VERSION ""

NS_ :

BS_:

BU_: ICC DVR EPC BBCM EAMP CMSM SBOX FLZCU_HCU_IC FLZCU_IC HCU_IC FLZCU_Signal_IC CGW TBOX BNCM CWC FRZCU

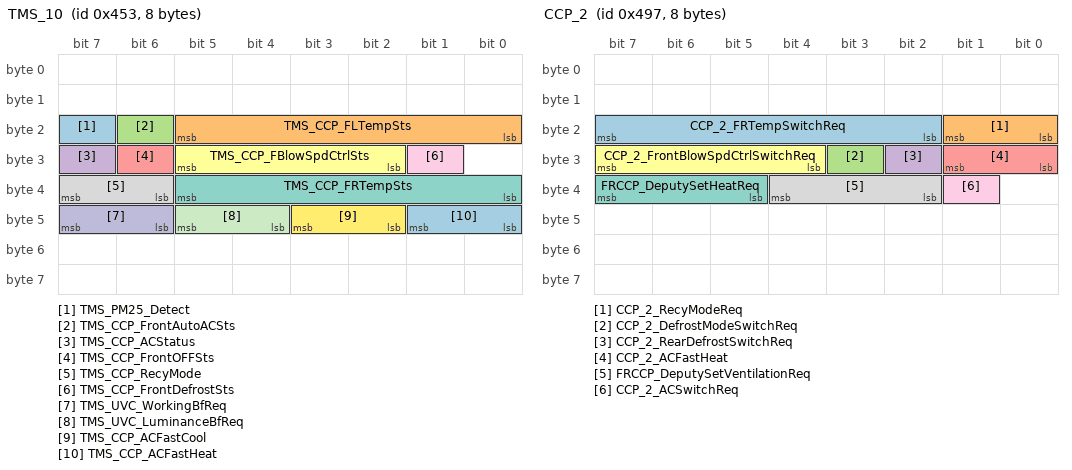
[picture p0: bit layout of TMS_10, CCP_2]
BO_ 1107 TMS_10: 8 CGW
 SG_ TMS_PM25_Detect : 23|1@0+ (1,0) [0|1] ""  ICC
 SG_ TMS_CCP_FLTempSts : 21|6@0+ (0.5,15.5) [15.5|30.5] "℃"  ICC
 SG_ TMS_CCP_FrontAutoACSts : 22|1@0+ (1,0) [0|1] ""  ICC
 SG_ TMS_CCP_ACStatus : 31|1@0+ (1,0) [0|1] ""  ICC
 SG_ TMS_CCP_FrontOFFSts : 30|1@0+ (1,0) [0|1] ""  ICC
 SG_ TMS_CCP_FBlowSpdCtrlSts : 29|4@0+ (1,0) [0|15] ""  ICC
 SG_ TMS_CCP_FRTempSts : 37|6@0+ (0.5,15.5) [15.5|30.5] "℃"  ICC
 SG_ TMS_CCP_RecyMode : 39|2@0+ (1,0) [0|3] ""  ICC
 SG_ TMS_CCP_FrontDefrostSts : 25|1@0+ (1,0) [0|1] ""  ICC
 SG_ TMS_UVC_WorkingBfReq : 47|2@0+ (1,0) [0|3] ""  ICC
 SG_ TMS_UVC_LuminanceBfReq : 45|2@0+ (1,0) [0|3] ""  ICC
 SG_ TMS_CCP_ACFastCool : 43|2@0+ (1,0) [0|3] ""  ICC
 SG_ TMS_CCP_ACFastHeat : 41|2@0+ (1,0) [0|3] ""  ICC

BO_ 1175 CCP_2: 8 CGW
 SG_ CCP_2_FRTempSwitchReq : 23|6@0+ (0.5,15.5) [15.5|30.5] "℃"  ICC
 SG_ CCP_2_RecyModeReq : 17|2@0+ (1,0) [0|3] ""  ICC
 SG_ CCP_2_DefrostModeSwitchReq : 27|1@0+ (1,0) [0|1] ""  ICC
 SG_ CCP_2_RearDefrostSwitchReq : 26|1@0+ (1,0) [0|1] ""  ICC
 SG_ CCP_2_ACFastHeat : 25|2@0+ (1,0) [0|3] ""  ICC
 SG_ CCP_2_FrontBlowSpdCtrlSwitchReq : 31|4@0+ (1,0) [0|15] ""  ICC
 SG_ FRCCP_DeputySetHeatReq : 39|3@0+ (1,0) [0|7] ""  ICC
 SG_ FRCCP_DeputySetVentilationReq : 36|3@0+ (1,0) [0|7] ""  ICC
 SG_ CCP_2_ACSwitchReq : 33|1@0+ (1,0) [0|1] ""  ICC

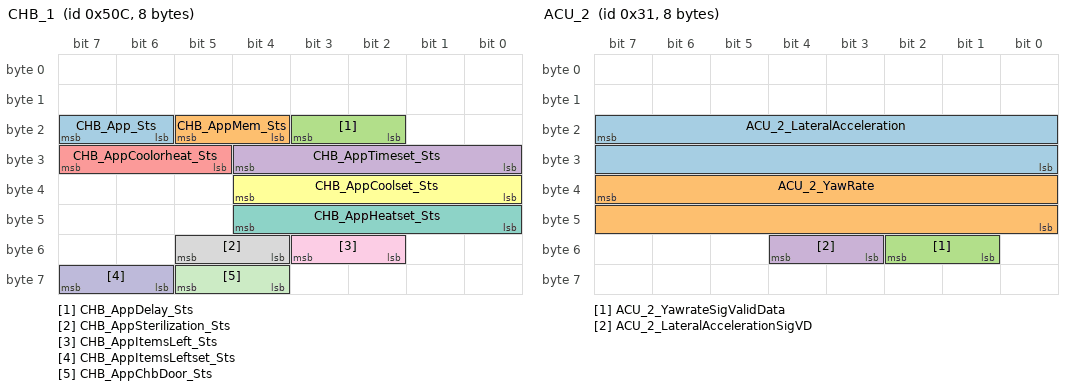
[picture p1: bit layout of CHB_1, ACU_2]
BO_ 1292 CHB_1: 8 CGW
 SG_ CHB_App_Sts : 23|2@0+ (1,0) [0|3] ""  ICC
 SG_ CHB_AppMem_Sts : 21|2@0+ (1,0) [0|3] ""  ICC
 SG_ CHB_AppDelay_Sts : 19|2@0+ (1,0) [0|3] ""  ICC
 SG_ CHB_AppTimeset_Sts : 28|5@0+ (1,0) [0|31] "h"  ICC
 SG_ CHB_AppCoolorheat_Sts : 31|3@0+ (1,0) [0|7] ""  ICC
 SG_ CHB_AppCoolset_Sts : 36|5@0+ (1,0) [0|31] ""  ICC
 SG_ CHB_AppHeatset_Sts : 44|5@0+ (1,0) [0|31] ""  ICC
 SG_ CHB_AppSterilization_Sts : 53|2@0+ (1,0) [0|3] ""  ICC
 SG_ CHB_AppItemsLeft_Sts : 51|2@0+ (1,0) [0|3] ""  ICC
 SG_ CHB_AppItemsLeftset_Sts : 63|2@0+ (1,0) [0|3] ""  ICC
 SG_ CHB_AppChbDoor_Sts : 61|2@0+ (1,0) [0|3] ""  ICC

BO_ 1241 EMS_4_G: 8 CGW
 SG_ FuelTankLidSystemFailureSts : 43|1@0+ (1,0) [0|1] ""  ICC
 SG_ FuelTankPressureConditionReached : 45|2@0+ (1,0) [0|3] ""  ICC

BO_ 49 ACU_2: 8 CGW
 SG_ ACU_2_LateralAcceleration : 23|16@0+ (0.001,-2) [-2|2] "g"  ICC
 SG_ ACU_2_YawRate : 39|16@0+ (0.01,-180) [-180|180] "deg/sec"  ICC
 SG_ ACU_2_YawrateSigValidData : 50|2@0+ (1,0) [0|3] ""  ICC
 SG_ ACU_2_LateralAccelerationSigVD : 52|2@0+ (1,0) [0|3] ""  ICC

BO_ 1024 FRZCU_13: 64 CGW
 SG_ FRZCU_QueenSeatPosSts : 80|1@0+ (1,0) [0|1] ""  BBCM,ICC
 SG_ FRZCU_QueenSeatEnterSts : 57|2@0+ (1,0) [0|3] ""  ICC
 SG_ FRZCU_QueenSeatMovFailCause : 87|4@0+ (1,0) [0|15] ""  ICC
 SG_ FRZCU_QueenSeatSts : 83|2@0+ (1,0) [0|3] ""  ICC
 SG_ FRZCU_PasgerSeatMovFailCause : 61|4@0+ (1,0) [0|15] ""  ICC
 SG_ FRZCU_ADSLightSts : 49|2@0+ (1,0) [0|3] ""  ICC
 SG_ CSunshadeSts : 23|3@0+ (1,0) [0|7] ""  ICC
 SG_ CSunshadePercentSts : 20|4@0+ (1,0) [0|15] ""  ICC
 SG_ FRZCU_SeatHeatLvlFR2 : 31|4@0+ (1,0) [0|15] ""  ICC
 SG_ FRZCU_SeatVentLvlFR2 : 27|4@0+ (1,0) [0|15] ""  ICC
 SG_ FRZCU_SeatVentLvlRR2 : 39|4@0+ (1,0) [0|15] ""  ICC
 SG_ FRZCU_SeatHeatLvlRR2 : 35|4@0+ (1,0) [0|15] ""  ICC
 SG_ FRZCU_ContainerlightSts : 47|2@0+ (1,0) [0|3] ""  ICC
 SG_ FRZCU_FRWinThermalSts : 45|1@0+ (1,0) [0|1] ""  ICC
 SG_ FRZCU_RRWinThermalSts : 44|1@0+ (1,0) [0|1] ""  ICC
 SG_ FRZCU_CSunshadeThermalSts : 43|1@0+ (1,0) [0|1] ""  ICC

BO_ 1182 CDU_OBC_3: 48 CGW
 SG_ OBC_InnerDischgVolt : 348|13@0+ (0.1,0) [0|800] ""  ICC
 SG_ OBC_InnerDischgCurr : 343|10@0+ (0.1,0) [0|100] ""  ICC
 SG_ OBC_ElectronicLockSts : 242|3@0+ (1,0) [0|4] ""  ICC
 SG_ OBC_WorkingMode : 251|4@0+ (1,0) [0|15] ""  ICC
 SG_ OBC_OutDischgCurr : 367|10@0+ (0.1,0) [0|100] "A"  ICC
 SG_ OBC_OutDischgVolt : 372|13@0+ (0.1,0) [0|800] "V"  ICC

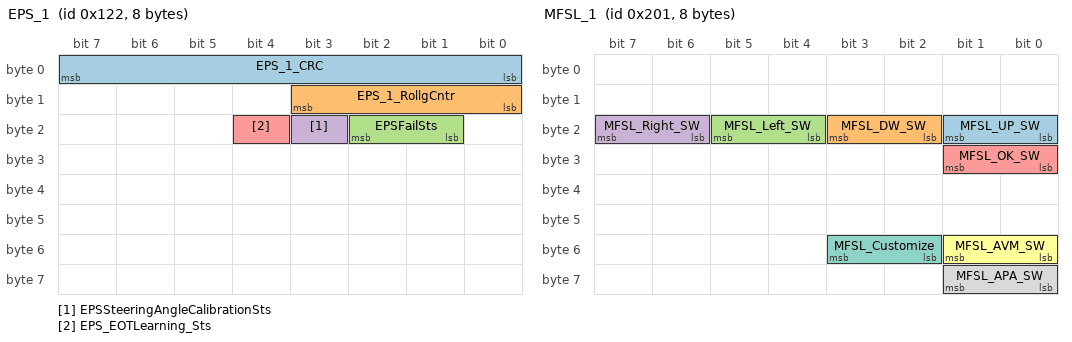
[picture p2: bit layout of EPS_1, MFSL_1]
BO_ 290 EPS_1: 8 CGW
 SG_ EPS_1_CRC : 7|8@0+ (1,0) [0|255] ""  ICC
 SG_ EPS_1_RollgCntr : 11|4@0+ (1,0) [0|14] ""  ICC
 SG_ EPSFailSts : 18|2@0+ (1,0) [0|3] ""  ICC
 SG_ EPSSteeringAngleCalibrationSts : 19|1@0+ (1,0) [0|1] ""  ICC
 SG_ EPS_EOTLearning_Sts : 20|1@0+ (1,0) [0|1] ""  ICC

BO_ 513 MFSL_1: 8 CGW
 SG_ MFSL_UP_SW : 17|2@0+ (1,0) [0|3] ""  ICC
 SG_ MFSL_DW_SW : 19|2@0+ (1,0) [0|3] ""  ICC
 SG_ MFSL_Left_SW : 21|2@0+ (1,0) [0|3] ""  ICC
 SG_ MFSL_Right_SW : 23|2@0+ (1,0) [0|3] ""  ICC
 SG_ MFSL_OK_SW : 25|2@0+ (1,0) [0|3] ""  ICC
 SG_ MFSL_AVM_SW : 49|2@0+ (1,0) [0|3] ""  ICC
 SG_ MFSL_Customize : 51|2@0+ (1,0) [0|3] ""  ICC
 SG_ MFSL_APA_SW : 57|2@0+ (1,0) [0|3] ""  ICC

BO_ 1152 TBOX_8: 16 CGW
 SG_ TBOX_PetmodeSetTemperature : 118|5@0+ (0.5,15.5) [15.5|30.5] "℃"  ICC

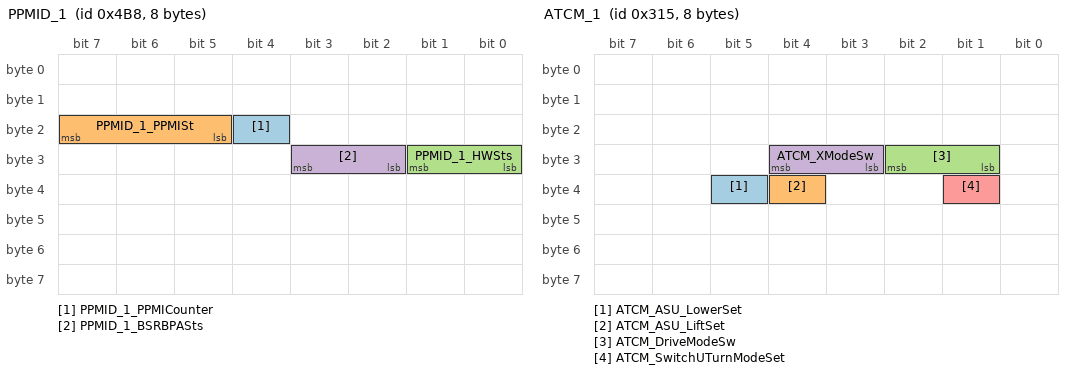
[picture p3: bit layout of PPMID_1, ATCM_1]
BO_ 1208 PPMID_1: 8 CGW
 SG_ PPMID_1_PPMICounter : 20|1@0+ (1,0) [0|1] ""  ICC
 SG_ PPMID_1_PPMISt : 23|3@0+ (1,0) [0|7] ""  ICC
 SG_ PPMID_1_HWSts : 25|2@0+ (1,0) [0|3] ""  ICC
 SG_ PPMID_1_BSRBPASts : 27|2@0+ (1,0) [0|3] ""  ICC

BO_ 794 ADS_COM_3: 24 CGW
 SG_ ADS_3_ICAStatus : 23|3@0+ (1,0) [0|7] ""  ICC
 SG_ ADS_3_ICATextinfo : 19|4@0+ (1,0) [0|15] ""  ICC
 SG_ ADS_3_ACCSts : 31|4@0+ (1,0) [0|15] ""  ICC
 SG_ ADS_3_DriverHandsoffWarning : 27|3@0+ (1,0) [0|7] ""  ICC
 SG_ ADS_3_LKSMod : 36|2@0+ (1,0) [0|3] ""  ICC
 SG_ ADS_3_LKSSts : 34|3@0+ (1,0) [0|7] ""  ICC
 SG_ ADS_3_ELKSts : 47|3@0+ (1,0) [0|7] ""  ICC
 SG_ ADS_3_LKSLeftTrackingSt : 44|2@0+ (1,0) [0|3] ""  ICC
 SG_ ADS_3_LKSRightTrackingSt : 42|2@0+ (1,0) [0|3] ""  ICC
 SG_ ADS_3_ELKLeftActiveSt : 55|2@0+ (1,0) [0|3] ""  ICC
 SG_ ADS_3_ELKRightActiveSt : 53|2@0+ (1,0) [0|3] ""  ICC

BO_ 1155 ASU_3: 16 CGW
 SG_ ASU_3_horizontalSts : 55|2@0+ (1,0) [0|3] ""  ICC
 SG_ ASU_3_horizontalmodeFb : 58|3@0+ (1,0) [0|7] ""  ICC

BO_ 1164 CDU_5: 64 CGW
 SG_ OBC_DischgSts : 123|3@0+ (1,0) [0|3] ""  ICC

BO_ 789 ATCM_1: 8 CGW
 SG_ ATCM_ASU_LowerSet : 37|1@0+ (1,0) [0|1] ""  ICC
 SG_ ATCM_ASU_LiftSet : 36|1@0+ (1,0) [0|1] ""  ICC
 SG_ ATCM_DriveModeSw : 26|2@0+ (1,0) [0|3] ""  ICC
 SG_ ATCM_XModeSw : 28|2@0+ (1,0) [0|3] ""  ICC
 SG_ ATCM_SwitchUTurnModeSet : 33|1@0+ (1,0) [0|1] ""  ICC

BO_ 1214 BNCM_16: 32 CGW
 SG_ BNCM_16_CRC1 : 7|8@0+ (1,0) [0|255] ""  ICC
 SG_ BNCM_16_RollgCntr1 : 11|4@0+ (1,0) [0|14] ""  ICC
 SG_ BNCM_16_Resd1 : 15|4@0+ (1,0) [0|15] ""  ICC
 SG_ BNCM_16_CMD : 23|16@0+ (1,0) [0|65535] ""  ICC
 SG_ BNCM_16_PDU1 : 39|64@0+ (1,0) [0|1.84467440737096E+019] ""  ICC
 SG_ BNCM_16_PDU2 : 103|64@0+ (1,0) [0|1.84467440737096E+019] ""  ICC
 SG_ BNCM_16_PDU3 : 167|64@0+ (1,0) [0|1.84467440737096E+019] ""  ICC
 SG_ BNCM_16_PDU4 : 231|32@0+ (1,0) [0|4294967295] ""  ICC

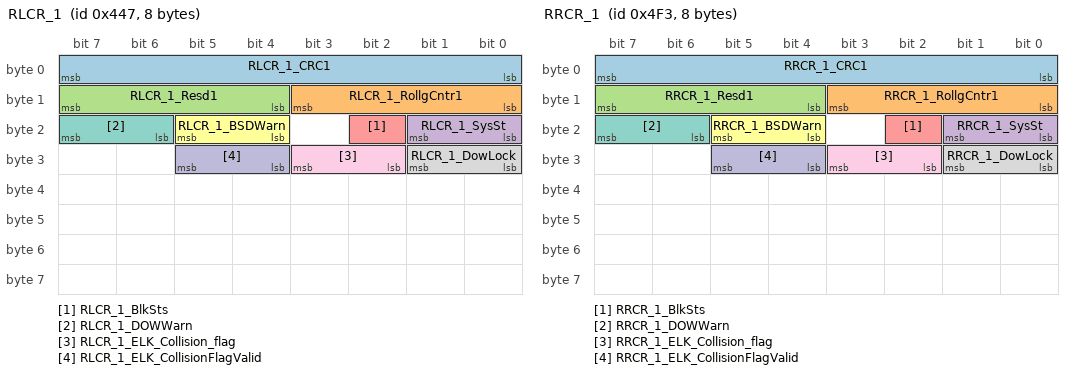
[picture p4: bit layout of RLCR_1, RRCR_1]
BO_ 1095 RLCR_1: 8 CGW
 SG_ RLCR_1_CRC1 : 7|8@0+ (1,0) [0|255] ""  ICC
 SG_ RLCR_1_RollgCntr1 : 11|4@0+ (1,0) [0|14] ""  ICC
 SG_ RLCR_1_Resd1 : 15|4@0+ (1,0) [0|15] ""  ICC
 SG_ RLCR_1_SysSt : 17|2@0+ (1,0) [0|3] ""  ICC
 SG_ RLCR_1_BlkSts : 18|1@0+ (1,0) [0|1] ""  ICC
 SG_ RLCR_1_BSDWarn : 21|2@0+ (1,0) [0|3] ""  ICC
 SG_ RLCR_1_DOWWarn : 23|2@0+ (1,0) [0|3] ""  ICC
 SG_ RLCR_1_DowLock : 25|2@0+ (1,0) [0|3] ""  ICC
 SG_ RLCR_1_ELK_Collision_flag : 27|2@0+ (1,0) [0|3] ""  ICC
 SG_ RLCR_1_ELK_CollisionFlagValid : 29|2@0+ (1,0) [0|3] ""  ICC

BO_ 1267 RRCR_1: 8 CGW
 SG_ RRCR_1_CRC1 : 7|8@0+ (1,0) [0|255] ""  ICC
 SG_ RRCR_1_RollgCntr1 : 11|4@0+ (1,0) [0|14] ""  ICC
 SG_ RRCR_1_Resd1 : 15|4@0+ (1,0) [0|15] ""  ICC
 SG_ RRCR_1_SysSt : 17|2@0+ (1,0) [0|3] ""  ICC
 SG_ RRCR_1_BlkSts : 18|1@0+ (1,0) [0|1] ""  ICC
 SG_ RRCR_1_BSDWarn : 21|2@0+ (1,0) [0|3] ""  ICC
 SG_ RRCR_1_DOWWarn : 23|2@0+ (1,0) [0|3] ""  ICC
 SG_ RRCR_1_DowLock : 25|2@0+ (1,0) [0|3] ""  ICC
 SG_ RRCR_1_ELK_Collision_flag : 27|2@0+ (1,0) [0|3] ""  ICC
 SG_ RRCR_1_ELK_CollisionFlagValid : 29|2@0+ (1,0) [0|3] ""  ICC

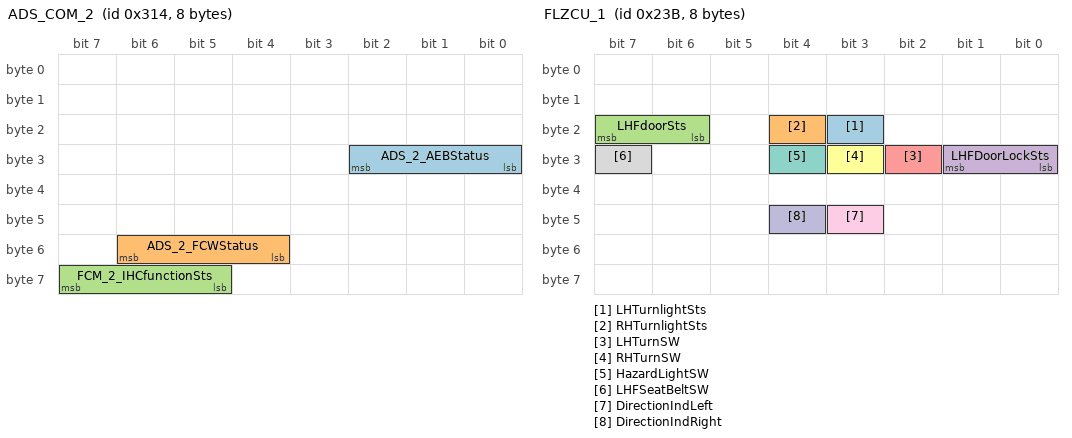
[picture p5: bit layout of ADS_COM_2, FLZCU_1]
BO_ 788 ADS_COM_2: 8 CGW
 SG_ ADS_2_AEBStatus : 26|3@0+ (1,0) [0|6] ""  ICC
 SG_ ADS_2_FCWStatus : 54|3@0+ (1,0) [0|7] ""  ICC
 SG_ FCM_2_IHCfunctionSts : 63|3@0+ (1,0) [0|7] ""  ICC

BO_ 571 FLZCU_1: 8 FLZCU_HCU_IC
 SG_ LHTurnlightSts : 19|1@0+ (1,0) [0|1] ""  ICC,DVR
 SG_ RHTurnlightSts : 20|1@0+ (1,0) [0|1] ""  ICC,DVR
 SG_ LHFdoorSts : 23|2@0+ (1,0) [0|3] ""  ICC,EPC,BBCM,CMSM
 SG_ LHFDoorLockSts : 25|2@0+ (1,0) [0|3] ""  ICC,EPC,BBCM
 SG_ LHTurnSW : 26|1@0+ (1,0) [0|1] ""  ICC
 SG_ RHTurnSW : 27|1@0+ (1,0) [0|1] ""  ICC
 SG_ HazardLightSW : 28|1@0+ (1,0) [0|1] ""  ICC
 SG_ LHFSeatBeltSW : 31|1@0+ (1,0) [0|1] ""  ICC
 SG_ DirectionIndLeft : 43|1@0+ (1,0) [0|1] ""  ICC
 SG_ DirectionIndRight : 44|1@0+ (1,0) [0|1] ""  ICC

BO_ 699 RZCU_2: 8 FLZCU_HCU_IC
 SG_ LHRdoorSts : 21|2@0+ (1,0) [0|3] ""  ICC,EPC,BBCM,CMSM

BO_ 787 FRZCU_14: 16 CGW
 SG_ ChrgHoodSts : 23|1@0+ (1,0) [0|1] ""  ICC
 SG_ FRZCU_FRSitPosnSts : 22|2@0+ (1,0) [0|3] ""  ICC

BO_ 524 ADS_6: 48 CGW
 SG_ New_Signal_20C : 16|1@0+ (1,0) [0|1] "" Vector__XXX
 SG_ New_Signal_20C_1 : 28|37@0+ (1,0) [0|137438953471] "" Vector__XXX
 SG_ ADS_6_CRC1 : 7|8@0+ (1,0) [0|255] ""  ICC
 SG_ ADS_6_RollgCntr1 : 11|4@0+ (1,0) [0|14] ""  ICC
 SG_ ADS_6_Resd1 : 15|4@0+ (1,0) [0|15] ""  ICC
 SG_ ADS_6_AVM_FuncSts : 23|2@0+ (1,0) [0|3] ""  ICC
 SG_ ADS_6_AVM_ButtonClick : 21|2@0+ (1,0) [0|1] ""  ICC
 SG_ ADS_6_Customize_buttonsFB : 19|3@0+ (1,0) [0|7] ""  ICC
 SG_ ADS_6_PAS_AudioTone : 31|3@0+ (1,0) [0|7] ""  ICC

BO_ 572 ONEBOX_7: 48 CGW
 SG_ ONEBOX_7_TAB_HighTemp : 49|1@0+ (1,0) [0|1] ""  ICC
 SG_ ONEBOX_7_TAB_Active : 51|2@0+ (1,0) [0|3] ""  ICC
 SG_ ONEBOX_7_BSW_Active : 60|2@0+ (1,0) [0|3] ""  ICC
 SG_ ONEBOX_7_iCCO_TgtVel : 151|8@0+ (0.1,0) [0|20] ""  ICC

BO_ 1212 VCU_3_G: 8 FLZCU_HCU_IC
 SG_ VCU_3_G_ActWheelTorqueFA : 23|16@0+ (1,-32768) [-32768|32767] "NM"  ICC
 SG_ VCU_3_G_ActWheelTorqueRA : 39|16@0+ (1,-32768) [-32768|32767] "NM"  ICC

BO_ 783 ADS_COM_1: 8 CGW
 SG_ ADCC_SysReadySts : 43|1@0+ (1,0) [0|1] ""  ICC

BO_ 1110 IMMO_ICC_11: 8 CGW
 SG_ IMMO_Chall_ICC : 7|64@0+ (1,0) [0|1.84467440737096E+019] ""  ICC

BO_ 1149 IMMO_VCC_12: 8 CGW
 SG_ IMMO_Teach_VCC : 7|64@0+ (1,0) [0|1.84467440737096E+019] ""  ICC

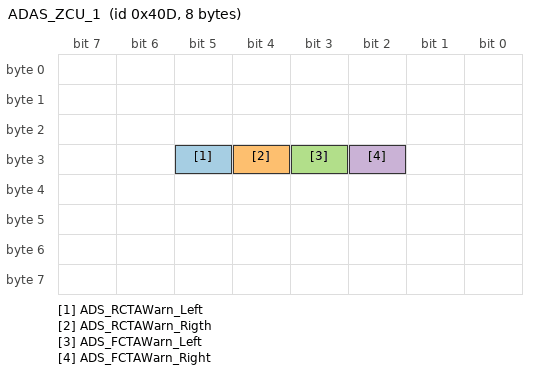
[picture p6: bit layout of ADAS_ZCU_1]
BO_ 1037 ADAS_ZCU_1: 8 CGW
 SG_ ADS_RCTAWarn_Left : 29|1@0+ (1,0) [0|1] ""  ICC
 SG_ ADS_RCTAWarn_Rigth : 28|1@0+ (1,0) [0|1] ""  ICC
 SG_ ADS_FCTAWarn_Left : 27|1@0+ (1,0) [0|1] ""  ICC
 SG_ ADS_FCTAWarn_Right : 26|1@0+ (1,0) [0|1] ""  ICC

BO_ 943 CSA_3: 32 CGW
 SG_ Fraxlebearingrate : 199|8@0+ (1,0) [0|100] ""  ICC
 SG_ CSA_3_CRC1 : 7|8@0+ (1,0) [0|255] ""  ICC
 SG_ CSA_3_RollgCntr1 : 11|4@0+ (1,0) [0|14] ""  ICC
 SG_ CSA_3_Resd1 : 15|4@0+ (1,0) [0|15] ""  ICC
 SG_ FlwheelBearing : 23|12@0+ (0.001,0) [0|4.095] "t"  ICC
 SG_ FrwheelBearing : 27|12@0+ (0.001,0) [0|4.095] "t"  ICC
 SG_ BlwheelBearing : 47|12@0+ (0.001,0) [0|4.095] "t"  ICC
 SG_ BrwheelBearing : 51|12@0+ (0.001,0) [0|4.095] "t"  ICC
 SG_ CSA_3_CRC2 : 71|8@0+ (1,0) [0|255] ""  ICC
 SG_ CSA_3_RollgCntr2 : 75|4@0+ (1,0) [0|14] ""  ICC
 SG_ VehicleBearing_kg : 87|12@0+ (1,0) [0|4095] "kg"  ICC
 SG_ VehicleBearing_lb : 91|14@0+ (1,0) [0|16383] "lb"  ICC
 SG_ GoodsWeight_kg : 109|12@0+ (1,0) [0|4095] "kg"  ICC
 SG_ Goods_Weight_Ratio : 113|10@0+ (0.1,0) [0|100] "%"  ICC
 SG_ CSA_3_CRC3 : 135|8@0+ (1,0) [0|255] ""  ICC
 SG_ CSA_3_RollgCntr3 : 139|4@0+ (1,0) [0|14] ""  ICC
 SG_ CSA_3_Resd3 : 143|4@0+ (1,0) [0|15] ""  ICC
 SG_ GoodsWeight_lb : 151|14@0+ (1,0) [0|16383] "lb"  ICC
 SG_ OverWeightValue_kg : 153|12@0+ (1,0) [0|4095] "kg"  ICC
 SG_ OverWeightValue_lb : 173|14@0+ (1,0) [0|16383] "lb"  ICC
 SG_ OverWeightRatio : 191|3@0+ (1,0) [0|7] "%"  ICC
 SG_ OverWeightWarning : 188|1@0+ (1,0) [0|1] ""  ICC
 SG_ OverLoadWarnShieldSetFed : 187|2@0+ (1,0) [0|3] ""  ICC

BO_ 1120 FLZCU_3: 8 FLZCU_HCU_IC
 SG_ RLHS_2_AmbBrightness : 19|12@0+ (20,0) [0|81880] "Lux"  ICC
 SG_ RLHS_LiSwithReason : 49|2@0+ (1,0) [0|3] ""  ICC

BO_ 850 ASU_6: 32 CGW
 SG_ ASU_trekthrough_352h : 47|2@0+ (1,0) [0|3] ""  ICC
 SG_ ASU_undergroundmode_352h : 45|2@0+ (1,0) [0|3] ""  ICC
 SG_ ASU_inflate_352h : 43|2@0+ (1,0) [0|3] ""  ICC
 SG_ ASU_6_HMIFailFb_JT : 23|4@0+ (1,0) [0|15] ""  ICC

BO_ 1199 TCM_1: 8 CGW
 SG_ TCM_1_TrailerSts : 16|1@0+ (1,0) [0|1] ""  ICC

BO_ 770 ADS_HW_302h: 64 CGW
 SG_ ADS_RPAOnlineOrNot_302h : 23|8@0+ (1,0) [0|255] ""  ICC
 SG_ ADS_RpaParkAuthn_302h : 31|2@0+ (1,0) [0|3] ""  ICC
 SG_ ADS_SeldParkID_302h : 29|4@0+ (1,0) [0|10] ""  ICC
 SG_ ADS_VehParkMod_302h : 25|3@0+ (1,0) [0|2] ""  ICC
 SG_ ADS_RemParkPatSel_302h : 38|2@0+ (1,0) [0|3] ""  ICC
 SG_ ADS_ParkDirCfm_302h : 36|4@0+ (1,0) [0|8] ""  ICC
 SG_ ADS_ParkProgs_302h : 32|7@0+ (1,0) [0|100] ""  ICC
 SG_ ADS_ParkRmngDst_302h : 41|9@0+ (0.1,0) [0|50] ""  ICC
 SG_ ADS_ObstclDst_302h : 48|5@0+ (1,0) [0|31] ""  ICC
 SG_ ADS_AutEve_302h : 59|4@0+ (1,0) [0|15] ""  ICC
 SG_ ADS_parkInterruptDuration_302h : 87|8@0+ (1,0) [0|255] ""  ICC
 SG_ APA_ResuAvl_302h : 95|2@0+ (1,0) [0|3] ""  ICC
 SG_ ADS_ParkStMac_302h : 93|5@0+ (1,0) [0|31] ""  ICC
 SG_ ADS_ParkOutDir_ParaLe_302h : 88|1@0+ (1,0) [0|1] ""  ICC
 SG_ ADS_ParkOutDir_ParaRi_302h : 103|1@0+ (1,0) [0|1] ""  ICC
 SG_ ADS_ParkOutDir_PerpFwd_302h : 102|1@0+ (1,0) [0|1] ""  ICC
 SG_ ADS_ParkOutDir_PerpLeFwd_302h : 101|1@0+ (1,0) [0|1] ""  ICC
 SG_ ADS_ParkOutDir_PerpRiFwd_302h : 100|1@0+ (1,0) [0|1] ""  ICC
 SG_ ADS_ParkOutDir_PerpLeBack_302h : 99|1@0+ (1,0) [0|1] ""  ICC
 SG_ ADS_ParkOutDir_PerpRiBack_302h : 98|1@0+ (1,0) [0|1] ""  ICC
 SG_ ADS_ParkOutDir_PerpBack_302h : 97|1@0+ (1,0) [0|1] ""  ICC
 SG_ APA_RPAFctUnavlMsg_1_302h : 96|1@0+ (1,0) [0|1] ""  ICC
 SG_ APA_RPAFctUnavlMsg_2_302h : 111|1@0+ (1,0) [0|1] ""  ICC
 SG_ APA_RPAFctUnavlMsg_3_302h : 110|1@0+ (1,0) [0|1] ""  ICC
 SG_ APA_RPAFctUnavlMsg_4_302h : 109|1@0+ (1,0) [0|1] ""  ICC
 SG_ APA_RPAFctUnavlMsg_5_302h : 108|1@0+ (1,0) [0|1] ""  ICC
 SG_ APA_RPAFctUnavlMsg_6_302h : 107|1@0+ (1,0) [0|1] ""  ICC
 SG_ APA_RPAFctUnavlMsg_7_302h : 106|1@0+ (1,0) [0|1] ""  ICC
 SG_ APA_RPAFctUnavlMsg_8_302h : 105|1@0+ (1,0) [0|1] ""  ICC
 SG_ APA_RPAFctUnavlMsg_9_302h : 104|1@0+ (1,0) [0|1] ""  ICC
 SG_ APA_RPAFctUnavlMsg_10_302h : 119|1@0+ (1,0) [0|1] ""  ICC
 SG_ APA_RPAFctUnavlMsg_11_302h : 118|1@0+ (1,0) [0|1] ""  ICC
 SG_ APA_RPAFctUnavlMsg_12_302h : 117|1@0+ (1,0) [0|1] ""  ICC
 SG_ APA_RPAFctUnavlMsg_13_302h : 116|1@0+ (1,0) [0|1] ""  ICC
 SG_ APA_RPAFctUnavlMsg_14_302h : 115|1@0+ (1,0) [0|1] ""  ICC
 SG_ APA_RPAFctUnavlMsg_15_302h : 114|1@0+ (1,0) [0|1] ""  ICC
 SG_ APA_RPAFctUnavlMsg_16_302h : 113|1@0+ (1,0) [0|1] ""  ICC
 SG_ APA_RPAFctUnavlMsg_17_302h : 112|1@0+ (1,0) [0|1] ""  ICC
 SG_ APA_RPAFctUnavlMsg_18_302h : 127|1@0+ (1,0) [0|1] ""  ICC
 SG_ APA_RPAFctUnavlMsg_19_302h : 126|1@0+ (1,0) [0|1] ""  ICC
 SG_ APA_RPAFctUnavlMsg_20_302h : 125|1@0+ (1,0) [0|1] ""  ICC
 SG_ APA_RPAFctUnavlMsg_21_302h : 124|1@0+ (1,0) [0|1] ""  ICC
 SG_ APA_RPAFctUnavlMsg_22_302h : 123|1@0+ (1,0) [0|1] ""  ICC
 SG_ APA_RPAFctUnavlMsg_23_302h : 122|1@0+ (1,0) [0|1] ""  ICC
 SG_ APA_RPAFctUnavlMsg_24_302h : 121|1@0+ (1,0) [0|1] ""  ICC
 SG_ APA_RPAFctUnavlMsg_25_302h : 120|1@0+ (1,0) [0|1] ""  ICC
 SG_ APA_RPACnclMsg_1_302h : 151|1@0+ (1,0) [0|1] ""  ICC
 SG_ APA_RPACnclMsg_2_302h : 150|1@0+ (1,0) [0|1] ""  ICC
 SG_ APA_RPACnclMsg_3 : 149|1@0+ (1,0) [0|1] ""  ICC
 SG_ APA_RPACnclMsg_4_302h : 148|1@0+ (1,0) [0|1] ""  ICC
 SG_ APA_RPACnclMsg_5_302h : 147|1@0+ (1,0) [0|1] ""  ICC
 SG_ APA_RPACnclMsg_6_302h : 146|1@0+ (1,0) [0|1] ""  ICC
 SG_ APA_RPACnclMsg_7_302h : 145|1@0+ (1,0) [0|1] ""  ICC
 SG_ APA_RPACnclMsg_8_302h : 144|1@0+ (1,0) [0|1] ""  ICC
 SG_ APA_RPACnclMsg_9_302h : 159|1@0+ (1,0) [0|1] ""  ICC
 SG_ APA_RPACnclMsg_10_302h : 158|1@0+ (1,0) [0|1] ""  ICC
 SG_ APA_RPACnclMsg_11_302h : 157|1@0+ (1,0) [0|1] ""  ICC
 SG_ APA_RPACnclMsg_12_302h : 156|1@0+ (1,0) [0|1] ""  ICC
 SG_ APA_RPACnclMsg_13_302h : 155|1@0+ (1,0) [0|1] ""  ICC
 SG_ APA_RPACnclMsg_14_302h : 154|1@0+ (1,0) [0|1] ""  ICC
 SG_ APA_RPACnclMsg_15_302h : 153|1@0+ (1,0) [0|1] ""  ICC
 SG_ APA_RPACnclMsg_16_302h : 152|1@0+ (1,0) [0|1] ""  ICC
 SG_ APA_RPACnclMsg_17_302h : 167|1@0+ (1,0) [0|1] ""  ICC
 SG_ APA_RPACnclMsg_18_302h : 166|1@0+ (1,0) [0|1] ""  ICC
 SG_ APA_RPACnclMsg_19_302h : 165|1@0+ (1,0) [0|1] ""  ICC
 SG_ APA_RPACnclMsg_20_302h : 164|1@0+ (1,0) [0|1] ""  ICC
 SG_ APA_RPAPauseMsg_1_302h : 163|1@0+ (1,0) [0|1] ""  ICC
 SG_ APA_RPAPauseMsg_2_302h : 162|1@0+ (1,0) [0|1] ""  ICC
 SG_ APA_RPAPauseMsg_3_302h : 161|1@0+ (1,0) [0|1] ""  ICC
 SG_ APA_RPAPauseMsg_4_302h : 160|1@0+ (1,0) [0|1] ""  ICC
 SG_ APA_RPAPauseMsg_5_302h : 175|1@0+ (1,0) [0|1] ""  ICC
 SG_ APA_RPAPauseMsg_6_302h : 174|1@0+ (1,0) [0|1] ""  ICC
 SG_ APA_RPAPauseMsg_7_302h : 173|1@0+ (1,0) [0|1] ""  ICC
 SG_ APA_RPAPauseMsg_8_302h : 172|1@0+ (1,0) [0|1] ""  ICC
 SG_ APA_RPAPauseMsg_9_302h : 171|1@0+ (1,0) [0|1] ""  ICC
 SG_ APA_RPAPauseMsg_10_302h : 170|1@0+ (1,0) [0|1] ""  ICC
 SG_ ADS_ParkPosn1_ID_302h : 169|4@0+ (1,0) [0|15] ""  ICC
 SG_ ADS_MnvrOrintChng1_302h : 181|2@0+ (1,0) [0|3] ""  ICC
 SG_ ADS_MnvrOrintChng2_302h : 179|2@0+ (1,0) [0|3] ""  ICC
 SG_ ADS_ParkRelPos1_x1_302h : 177|10@0+ (0.1,-50) [-50|50] ""  ICC
 SG_ ADS_ParkRelPos1_y1_302h : 215|10@0+ (0.1,-50) [-50|50] ""  ICC
 SG_ ADS_ParkRelPos1_x2_302h : 221|10@0+ (0.1,-50) [-50|50] ""  ICC
 SG_ ADS_ParkRelPos1_y2_302h : 227|10@0+ (0.1,-50) [-50|50] ""  ICC
 SG_ ADS_ParkRelPos1_x3_302h : 233|10@0+ (0.1,-50) [-50|50] ""  ICC
 SG_ ADS_TarParkSt_Posn1_302h : 255|3@0+ (1,0) [0|7] ""  ICC
 SG_ ADS_ParkChkSrc_Posn1_302h : 252|3@0+ (1,0) [0|3] ""  ICC
 SG_ ADS_VdcActvSts_302h : 249|1@0+ (1,0) [0|1] ""  ICC
 SG_ ADS_TcsActvSts_302h : 248|1@0+ (1,0) [0|1] ""  ICC
 SG_ ADS_ParkRelPos1_y3_302h : 279|10@0+ (0.1,-50) [-50|50] ""  ICC
 SG_ ADS_ParkRelPos1_x4_302h : 285|10@0+ (0.1,-50) [-50|50] ""  ICC
 SG_ ADS_ParkRelPos1_y4_302h : 291|10@0+ (0.1,-50) [-50|50] ""  ICC
 SG_ ADS_ParkPosn2_ID_302h : 297|4@0+ (1,0) [0|15] ""  ICC
 SG_ ADS_ParkRelPos2_x1_302h : 309|10@0+ (0.1,-50) [-50|50] ""  ICC
 SG_ ADS_ParkRelPos2_y1_302h : 343|10@0+ (0.1,-50) [-50|50] ""  ICC
 SG_ ADS_ParkRelPos2_x2_302h : 349|10@0+ (0.1,-50) [-50|50] ""  ICC
 SG_ ADS_ParkRelPos2_y2_302h : 355|10@0+ (0.1,-50) [-50|50] ""  ICC
 SG_ ADS_ParkRelPos2_x3_302h : 361|10@0+ (0.1,-50) [-50|50] ""  ICC
 SG_ ADS_TarParkSt_Posn2_302h : 383|3@0+ (1,0) [0|7] ""  ICC
 SG_ ADS_ParkChkSrc_Posn2_302h : 380|3@0+ (1,0) [0|3] ""  ICC
 SG_ ADS_ParkRelPos2_y3_302h : 407|10@0+ (0.1,-50) [-50|50] ""  ICC
 SG_ ADS_ParkRelPos2_x4_302h : 413|10@0+ (0.1,-50) [-50|50] ""  ICC
 SG_ ADS_ParkRelPos2_y4_302h : 419|10@0+ (0.1,-50) [-50|50] ""  ICC

BO_ 514 ADS_HW_202h: 16 CGW
 SG_ ADS_Resd1_202h : 15|4@0+ (1,0) [0|15] ""  ICC
 SG_ ADS_RollgCntr1_202h : 11|4@0+ (1,0) [0|14] ""  ICC
 SG_ ADS_CRC1_202h : 7|8@0+ (1,0) [0|255] ""  ICC
 SG_ ADS_AdsFault_202h : 23|3@0+ (1,0) [0|7] ""  ICC
 SG_ ADS_NicaReminderLEDVisual_202h : 20|3@0+ (1,0) [0|7] ""  ICC
 SG_ ADS_NicaReminderAcoustic_202h : 17|3@0+ (1,0) [0|7] ""  ICC
 SG_ ADS_TakeoverID_202h : 30|16@0+ (1,0) [0|65535] ""  ICC
 SG_ ADS_TakeoverLevel_202h : 46|3@0+ (1,0) [0|7] ""  ICC
 SG_ ADS_TakeoverType_202h : 43|4@0+ (1,0) [0|15] ""  ICC
 SG_ ADS_TORIDCorrespErrorID_202h : 55|16@0+ (1,0) [0|65535] ""  ICC
 SG_ ADS_TakeoverExtended16bit_202h : 87|16@0+ (1,0) [0|65535] ""  ICC
 SG_ ADS_TakeoverExtended8bit_202h : 103|8@0+ (1,0) [0|255] ""  ICC

BO_ 1041 ADS_HW_411h: 48 CGW
 SG_ ADS_RadarWarning0Distance_411h : 23|8@0+ (1,0) [0|255] "cm"  ICC
 SG_ ADS_RadarWarning1Distance_411h : 31|8@0+ (1,0) [0|255] "cm"  ICC
 SG_ ADS_RadarWarning2Distance_411h : 39|8@0+ (1,0) [0|255] "cm"  ICC
 SG_ ADS_RadarWarning3Distance_411h : 47|8@0+ (1,0) [0|255] "cm"  ICC
 SG_ ADS_RadarWarning4Distance_411h : 55|8@0+ (1,0) [0|255] "cm"  ICC
 SG_ ADS_RadarWarning5Distance_411h : 63|8@0+ (1,0) [0|255] "cm"  ICC
 SG_ ADS_RadarWarning6Distance_411h : 87|8@0+ (1,0) [0|255] "cm"  ICC
 SG_ ADS_RadarWarning7Distance_411h : 95|8@0+ (1,0) [0|255] "cm"  ICC
 SG_ ADS_RadarWarning8Distance_411h : 103|8@0+ (1,0) [0|255] "cm"  ICC
 SG_ ADS_RadarWarning9Distance_411h : 111|8@0+ (1,0) [0|255] "cm"  ICC
 SG_ ADS_RadarWarning10Distance_411h : 119|8@0+ (1,0) [0|255] "cm"  ICC
 SG_ ADS_RadarWarning11Distance_411h : 127|8@0+ (1,0) [0|255] "cm"  ICC
 SG_ ADS_RadarWarning12Distance_411h : 151|8@0+ (1,0) [0|255] "cm"  ICC
 SG_ ADS_RadarWarning13Distance_411h : 159|8@0+ (1,0) [0|255] "cm"  ICC
 SG_ ADS_RadarWarning14Distance_411h : 167|8@0+ (1,0) [0|255] "cm"  ICC
 SG_ ADS_RadarWarning15Distance_411h : 175|8@0+ (1,0) [0|255] "cm"  ICC
 SG_ ADS_RadarWarning0AcLvl_411h : 183|3@0+ (1,0) [0|7] ""  ICC
 SG_ ADS_RadarWarning1AcLvl_411h : 180|3@0+ (1,0) [0|7] ""  ICC
 SG_ ADS_RadarWarning2AcLvl_411h : 177|3@0+ (1,0) [0|7] ""  ICC
 SG_ ADS_RadarWarning3AcLvl_411h : 190|3@0+ (1,0) [0|7] ""  ICC
 SG_ ADS_RadarWarning4AcLvl_411h : 187|3@0+ (1,0) [0|7] ""  ICC
 SG_ ADS_RadarWarning5AcLvl_411h : 215|3@0+ (1,0) [0|7] ""  ICC
 SG_ ADS_RadarWarning6AcLvl_411h : 212|3@0+ (1,0) [0|7] ""  ICC
 SG_ ADS_RadarWarning7AcLvl_411h : 209|3@0+ (1,0) [0|7] ""  ICC
 SG_ ADS_RadarWarning8AcLvl_411h : 222|3@0+ (1,0) [0|7] ""  ICC
 SG_ ADS_RadarWarning9AcLvl_411h : 219|3@0+ (1,0) [0|7] ""  ICC
 SG_ ADS_RadarWarning10AcLvl_411h : 216|3@0+ (1,0) [0|7] ""  ICC
 SG_ ADS_RadarWarning11AcLvl_411h : 229|3@0+ (1,0) [0|7] ""  ICC
 SG_ ADS_RadarWarning12AcLvl_411h : 226|3@0+ (1,0) [0|7] ""  ICC
 SG_ ADS_RadarWarning13AcLvl_411h : 239|3@0+ (1,0) [0|7] ""  ICC
 SG_ ADS_RadarWarning14AcLvl_411h : 236|3@0+ (1,0) [0|7] ""  ICC
 SG_ ADS_RadarWarning15AcLvl_411h : 233|3@0+ (1,0) [0|7] ""  ICC
 SG_ ADC_FuncReq_SentryModWarn_411h : 246|1@0+ (1,0) [0|1] ""  ICC
 SG_ ADC_FuncReq_SentryModDetec_411h : 245|1@0+ (1,0) [0|1] ""  ICC
 SG_ ADC_MdcSentryAlarmMod_411h : 244|1@0+ (1,0) [0|1] ""  ICC

BO_ 769 ADS_HW_301h: 48 CGW
 SG_ ADS_AccFunctionStatus_301h : 23|4@0+ (1,0) [0|15] ""  ICC
 SG_ ADS_LccNcaFunctionStatus_301h : 19|6@0+ (1,0) [0|63] ""  ICC
 SG_ ADS_AdsFucntionNotActive_301h : 29|4@0+ (1,0) [0|15] ""  ICC
 SG_ ADS_AvpFunctionStatus_301h : 25|5@0+ (1,0) [0|31] ""  ICC
 SG_ ADS_SpeedSetByDriver_301h : 36|9@0+ (1,0) [0|511] "kph"  ICC
 SG_ ADS_SpeedLimitValue_301h : 43|8@0+ (1,0) [0|255] "kph"  ICC
 SG_ ADS_SpeedAutoFollow_301h : 51|3@0+ (1,0) [0|7] ""  ICC
 SG_ ADS_OneTouchSpeedAdjustment_301h : 48|3@0+ (1,0) [0|7] ""  ICC
 SG_ ADS_CalibState_301h : 61|3@0+ (1,0) [0|7] ""  ICC
 SG_ ADS_HODReminder_301h : 58|3@0+ (1,0) [0|7] ""  ICC
 SG_ ADS_DMSReminder_301h : 87|4@0+ (1,0) [0|15] ""  ICC
 SG_ ADS_FcwWaning_301h : 83|3@0+ (1,0) [0|7] ""  ICC
 SG_ ADS_FcwFault_301h : 80|2@0+ (1,0) [0|3] ""  ICC
 SG_ ADS_AebWaning_301h : 94|4@0+ (1,0) [0|15] ""  ICC
 SG_ ADS_AebFault_301h : 90|2@0+ (1,0) [0|3] ""  ICC
 SG_ ADS_AebObjType_301h : 88|3@0+ (1,0) [0|7] ""  ICC
 SG_ ADS_RaebWarning_301h : 101|3@0+ (1,0) [0|7] ""  ICC
 SG_ ADS_RaebFault_301h : 98|2@0+ (1,0) [0|3] ""  ICC
 SG_ ADS_RcwWarning_301h : 96|3@0+ (1,0) [0|7] ""  ICC
 SG_ ADS_RcwFault_301h : 109|2@0+ (1,0) [0|3] ""  ICC
 SG_ ADS_FctaLeftWarning_301h : 107|3@0+ (1,0) [0|7] ""  ICC
 SG_ ADS_FctaRightWarning_301h : 104|3@0+ (1,0) [0|7] ""  ICC
 SG_ ADS_FctbLeftWarning_301h : 117|3@0+ (1,0) [0|7] ""  ICC
 SG_ ADS_FctbRightWarning_301h : 114|3@0+ (1,0) [0|7] ""  ICC
 SG_ ADS_RctaLeftWarning_301h : 127|3@0+ (1,0) [0|7] ""  ICC
 SG_ ADS_RctaRightWarning_301h : 124|3@0+ (1,0) [0|7] ""  ICC
 SG_ ADS_RctaFault_301h : 121|2@0+ (1,0) [0|3] ""  ICC
 SG_ ADS_RctbLeftWarning_301h : 151|3@0+ (1,0) [0|7] ""  ICC
 SG_ ADS_RctbRightWarning_301h : 148|3@0+ (1,0) [0|7] ""  ICC
 SG_ ADS_LdwWarning_301h : 145|3@0+ (1,0) [0|7] ""  ICC
 SG_ ADS_LdwFault_301h : 158|3@0+ (1,0) [0|7] ""  ICC
 SG_ ADS_LKAWarning_301h : 155|3@0+ (1,0) [0|7] ""  ICC
 SG_ ADS_LkaFault_301h : 152|2@0+ (1,0) [0|3] ""  ICC
 SG_ ADS_LeftMirrWarningCmd_301h : 166|3@0+ (1,0) [0|7] ""  ICC
 SG_ ADS_RightMirrWarningCmd_301h : 163|3@0+ (1,0) [0|7] ""  ICC
 SG_ ADS_BsdFault_301h : 160|2@0+ (1,0) [0|3] ""  ICC
 SG_ ADS_LeFrntDoorWarningCmd_301h : 174|3@0+ (1,0) [0|7] ""  ICC
 SG_ ADS_LeReDoorWarningCmd_301h : 171|3@0+ (1,0) [0|7] ""  ICC
 SG_ ADS_RiFrntDoorWarningCmd_301h : 168|3@0+ (1,0) [0|7] ""  ICC
 SG_ ADS_RiReDoorWarningCmd_301h : 181|3@0+ (1,0) [0|7] ""  ICC
 SG_ ADS_DowFault_301h : 178|2@0+ (1,0) [0|3] ""  ICC
 SG_ ADS_SpeedLimitWarning_301h : 176|3@0+ (1,0) [0|7] ""  ICC
 SG_ ADS_TsrFault_301h : 189|2@0+ (1,0) [0|3] ""  ICC
 SG_ ADS_TlaFault_301h : 187|2@0+ (1,0) [0|3] ""  ICC
 SG_ ADS_ElkaFault_301h : 185|2@0+ (1,0) [0|3] ""  ICC
 SG_ ADS_AbsoultwSpeedLimit_301h : 215|16@0+ (1,0) [0|65535] "kph"  ICC
 SG_ ADS_TlaWarning_301h : 231|3@0+ (1,0) [0|7] ""  ICC
 SG_ ADS_ElkaWarning_301h : 228|3@0+ (1,0) [0|7] ""  ICC

BO_ 1042 ADS_HW_412h: 16 CGW
 SG_ New_Signal_412_1 : 56|1@0+ (1,0) [0|1] ""  ICC
 SG_ ADS_Resd1_412h : 15|4@0+ (1,0) [0|15] ""  ICC
 SG_ ADS_RollgCntr1_412h : 11|4@0+ (1,0) [0|14] ""  ICC
 SG_ ADS_CRC1_412h : 7|8@0+ (1,0) [0|255] ""  ICC
 SG_ ADS_BrkBeamReq_412h : 23|2@0+ (1,0) [0|3] ""  ICC
 SG_ ADS_AutoLightSwCtrl_412h : 21|2@0+ (1,0) [0|3] ""  ICC
 SG_ ADS_LeFrntDowWarning_412h : 19|2@0+ (1,0) [0|3] ""  ICC
 SG_ ADS_RiFrntDowWarning_412h : 17|2@0+ (1,0) [0|3] ""  ICC
 SG_ ADS_LeReDowWarning_412h : 31|2@0+ (1,0) [0|3] ""  ICC
 SG_ ADS_RiReDowWarning_412h : 29|2@0+ (1,0) [0|3] ""  ICC
 SG_ ADS_LeftMirrWarningCmd_412h : 27|2@0+ (1,0) [0|3] ""  ICC
 SG_ ADS_RightMirrWarningCmd_412h : 25|2@0+ (1,0) [0|3] ""  ICC
 SG_ ADS_ReMirrReq_412h : 39|2@0+ (1,0) [0|3] ""  ICC
 SG_ ADS_DoorLockReq_412h : 37|2@0+ (1,0) [0|3] ""  ICC
 SG_ ADS_SBeltControl_412h : 35|3@0+ (1,0) [0|7] ""  ICC
 SG_ ADS_WshrReq_412h : 32|1@0+ (1,0) [0|1] ""  ICC
 SG_ ADS_SeatShakeControl_412h : 47|2@0+ (1,0) [0|3] ""  ICC
 SG_ ADS_FrtWindshildHeatReq_412h : 45|2@0+ (1,0) [0|3] ""  ICC
 SG_ ADS_HornReq_412h : 43|2@0+ (1,0) [0|3] ""  ICC
 SG_ ADS_LeFmtWinCtrl_412h : 41|2@0+ (1,0) [0|3] ""  ICC
 SG_ ADS_RiFmtWinCtrl_412h : 55|2@0+ (1,0) [0|3] ""  ICC
 SG_ ADS_LeReWinCtrl_412h : 53|2@0+ (1,0) [0|3] ""  ICC
 SG_ ADS_RiReWinCtrl_412h : 51|2@0+ (1,0) [0|3] ""  ICC
 SG_ ADS_TopWinCtrl_412h : 49|2@0+ (1,0) [0|3] ""  ICC
 SG_ ADS_FrontWiperReq_412h : 63|1@0+ (1,0) [0|1] ""  ICC
 SG_ ADS_ChargingPortCmd_412h : 62|2@0+ (1,0) [0|3] ""  ICC
 SG_ ADAS_FctSts_412h : 60|1@0+ (1,0) [0|1] ""  ICC
 SG_ ADS_MdcCrtSts_412h : 59|3@0+ (1,0) [0|7] ""  ICC
 SG_ ADS_HVCtrlReq_412h : 87|1@0+ (1,0) [0|1] ""  ICC
 SG_ ADS_ThmPostRun_412h : 86|1@0+ (1,0) [0|1] "m/s2"  ICC
 SG_ ADS_FlowReq_412h : 85|4@0+ (1,0) [0|15] ""  ICC
 SG_ ADS_PwrOnOffReq_412h : 81|3@0+ (1,0) [0|7] ""  ICC
 SG_ ADS_hmaOnOffSts_412h : 94|2@0+ (1,0) [0|3] ""  ICC
 SG_ ADS_HMAStatus_412h : 92|2@0+ (1,0) [0|3] ""  ICC
 SG_ ADS_HiBeamReq_412h : 90|1@0+ (1,0) [0|1] ""  ICC

BO_ 1046 LBMS_SysSt4: 32 CGW
 SG_ LBMS_LoWSocFlt : 87|4@0+ (1,0) [0|15] ""  ICC
 SG_ LBMS_ThermRunawayFlt : 158|1@0+ (1,0) [0|1] ""  ICC
 SG_ LBMS_SysFlt : 157|1@0+ (1,0) [0|1] ""  ICC
 SG_ LBMS_LowPowerRemind : 167|4@0+ (1,0) [0|15] ""  ICC
 SG_ LBMS_EndLifeFlt : 152|1@0+ (1,0) [0|1] ""  ICC

BO_TX_BU_ 571 : FLZCU_HCU_IC,FLZCU_IC,FLZCU_Signal_IC;
BO_TX_BU_ 699 : FLZCU_HCU_IC,FLZCU_IC,FLZCU_Signal_IC;
BO_TX_BU_ 787 : CGW,FRZCU;
BO_TX_BU_ 1212 : FLZCU_HCU_IC,HCU_IC;
BO_TX_BU_ 1120 : FLZCU_HCU_IC,FLZCU_IC,FLZCU_Signal_IC;
CM_ SG_ 1107 TMS_CCP_FLTempSts "前排左侧温度设置";
CM_ SG_ 1107 TMS_CCP_FrontAutoACSts "前排自动功能";
CM_ SG_ 1107 TMS_CCP_ACStatus "ACStatus
AC_状态";
CM_ SG_ 1107 TMS_CCP_FrontOFFSts "空调关闭";
CM_ SG_ 1107 TMS_CCP_FBlowSpdCtrlSts "前排风速设置";
CM_ SG_ 1107 TMS_CCP_FRTempSts "前排右侧温度设置";
CM_ SG_ 1107 TMS_CCP_RecyMode "内外循环";
CM_ SG_ 1107 TMS_CCP_FrontDefrostSts "前除霜";
CM_ SG_ 1107 TMS_UVC_WorkingBfReq "紫外线杀菌灯请求";
CM_ SG_ 1107 TMS_UVC_LuminanceBfReq "紫外线杀菌灯强度请求";
CM_ SG_ 1107 TMS_CCP_ACFastCool "一键制冷反馈";
CM_ SG_ 1107 TMS_CCP_ACFastHeat "一键制热反馈";
CM_ SG_ 1175 CCP_2_FRTempSwitchReq "同上";
CM_ SG_ 1175 CCP_2_RecyModeReq "内外循环";
CM_ SG_ 1175 CCP_2_DefrostModeSwitchReq "前除霜";
CM_ SG_ 1175 CCP_2_RearDefrostSwitchReq "后除霜请求";
CM_ SG_ 1175 CCP_2_ACFastHeat "一键制热请求";
CM_ SG_ 1175 CCP_2_FrontBlowSpdCtrlSwitchReq "前排风速";
CM_ SG_ 1175 FRCCP_DeputySetHeatReq "副驾座椅加热";
CM_ SG_ 1175 FRCCP_DeputySetVentilationReq "副驾座椅通风";
CM_ SG_ 1175 CCP_2_ACSwitchReq "AC开关请求";
CM_ SG_ 1292 CHB_App_Sts "冰箱开关状态（捷途预留）";
CM_ SG_ 1292 CHB_AppMem_Sts "记忆开关状态";
CM_ SG_ 1292 CHB_AppDelay_Sts "延时开关状态";
CM_ SG_ 1292 CHB_AppTimeset_Sts "延时时间设置";
CM_ SG_ 1292 CHB_AppCoolorheat_Sts "制冷制热选择状态
冰箱工作模式（捷途使用）
0x0：无请求
0x1：制冷
0x2：制热
0x3：关
0x4：冷饮模式
0x5：冰淇淋模式
0x6：温奶模式
0x7：热饮模式";
CM_ SG_ 1292 CHB_AppCoolset_Sts "制冷温度设置
0xE~0x19:-18℃~-7℃（捷途预留）
0x1~0xD:-6℃~6℃（捷途使用）";
CM_ SG_ 1292 CHB_AppHeatset_Sts "制热温度调节设置";
CM_ SG_ 1292 CHB_AppSterilization_Sts "杀菌开关状态";
CM_ SG_ 1292 CHB_AppItemsLeft_Sts "物品遗留开关状态";
CM_ SG_ 1292 CHB_AppItemsLeftset_Sts "冰箱是否检测到物品的状态";
CM_ SG_ 1292 CHB_AppChbDoor_Sts "冰箱是门开关状态反馈信号";
CM_ SG_ 1241 FuelTankLidSystemFailureSts "加油小门系统故障信号";
CM_ SG_ 1241 FuelTankPressureConditionReached "油箱压力状态信号";
CM_ SG_ 49 ACU_2_LateralAcceleration "Lateral acceleration signal
Sensor accuracy：0.0027680342857143g";
CM_ SG_ 49 ACU_2_YawRate "Yaw rate signal
Sensor accuracy：0.122189236 deg/s";
CM_ SG_ 49 ACU_2_YawrateSigValidData "Signal state for yawrate";
CM_ SG_ 49 ACU_2_LateralAccelerationSigVD "If hasn’t been calibrated, after initialization, this signal ‘s value is always 10(invalid).";
CM_ SG_ 1024 CSunshadeSts "天幕遮阳帘实际状态
(大屏动效-可显示开启和关闭的动画)";
CM_ SG_ 1024 CSunshadePercentSts "天幕遮阳帘开度百分比状态";
CM_ SG_ 1024 FRZCU_SeatHeatLvlFR2 "副驾座椅加热状态--捷途使用";
CM_ SG_ 1024 FRZCU_SeatVentLvlFR2 "副驾座椅通风状态--捷途使用";
CM_ SG_ 1024 FRZCU_SeatVentLvlRR2 "二排右侧座椅通风状态--捷途使用";
CM_ SG_ 1024 FRZCU_SeatHeatLvlRR2 "二排右侧座椅加热状态--捷途使用";
CM_ SG_ 1024 FRZCU_ContainerlightSts "货箱灯状态反馈（D01P)";
CM_ SG_ 1024 FRZCU_FRWinThermalSts "右前车窗热保护状态
0：未触发热保护
1：热保护触发中";
CM_ SG_ 1024 FRZCU_RRWinThermalSts "右后车窗热保护状态
0：未触发热保护
1：热保护触发中";
CM_ SG_ 1024 FRZCU_CSunshadeThermalSts "天幕遮阳帘热保护状态
0：未触发热保护
1：热保护触发中";
CM_ SG_ 1182 OBC_ElectronicLockSts "Electronic Lock Sts";
CM_ SG_ 1182 OBC_WorkingMode "OBC working states";
CM_ SG_ 290 EPS_1_CRC "Profile1A:E2E CRC (SAE J1850 CRC-8) for 8 Bytes
DataID:0x002E";
CM_ SG_ 290 EPS_1_RollgCntr "Profile1A:E2E Rolling message counter(the maximum value of Alive counter is 14)";
CM_ SG_ 290 EPSFailSts "EPS Fail Status";
CM_ SG_ 290 EPSSteeringAngleCalibrationSts "EPS Steering Angle Calibration Status";
CM_ SG_ 290 EPS_EOTLearning_Sts "Indicates the status of EPS EOT(end of travel) learning, displayed on the DMC(ICM)";
CM_ SG_ 513 MFSL_APA_SW "APA开关(D01华为新增)";
CM_ SG_ 1152 TBOX_PetmodeSetTemperature "宠物模式远程空调温度设置";
CM_ SG_ 1208 PPMID_1_PPMICounter "PPMI counter/寿命计数状态";
CM_ SG_ 1208 PPMID_1_PPMISt "PPMI status/ PPMI是否有故障";
CM_ SG_ 1208 PPMID_1_HWSts "Haptic Warning(HWA) /  震动触觉提醒";
CM_ SG_ 1208 PPMID_1_BSRBPASts "Belt slack reduction(BSR) / 织带间隙消除
Belt parking assist(BPA) / 织带辅助回收";
CM_ SG_ 794 ADS_3_ICAStatus "ICA状态信号";
CM_ SG_ 794 ADS_3_ICATextinfo "ICA状态信号（文本提示）";
CM_ SG_ 794 ADS_3_ACCSts "ACC状态信号";
CM_ SG_ 794 ADS_3_DriverHandsoffWarning "驾驶员脱手报警请求";
CM_ SG_ 794 ADS_3_LKSMod "LDW LDP激活模式状态";
CM_ SG_ 794 ADS_3_LKSSts "LKS状态信号";
CM_ SG_ 794 ADS_3_ELKSts "ELK状态信号";
CM_ SG_ 794 ADS_3_LKSLeftTrackingSt "LDW LDP左侧车道线激活状态";
CM_ SG_ 794 ADS_3_LKSRightTrackingSt "LDW LDP右侧车道线激活状态";
CM_ SG_ 794 ADS_3_ELKLeftActiveSt "ELK左侧车道线激活状态";
CM_ SG_ 794 ADS_3_ELKRightActiveSt "ELK右侧车道线激活状态";
CM_ SG_ 1155 ASU_3_horizontalSts "露营找平开关状态
0x1:ON开关开启
0x2:OFF开关关闭";
CM_ SG_ 1155 ASU_3_horizontalmodeFb "露营找平模式反馈
0x0:Not Active条件不满足，未激活
0x1:Working找平中
0x2:Complete找平完成
0x3:Abort找平中断
0x4:Failure找平失败";
CM_ SG_ 1164 OBC_DischgSts "（新增OBC中控屏使用外放电电流显示）
0x0:NoDischarge
0x1:Discharging(外放电)
0x2:Discharging-Interior(内放电)
0x3:Discharging_AND_Discharging-Interior(内外放电同时进行)";
CM_ SG_ 789 ATCM_DriveModeSw "驾驶模式状态
（正旋一次共发送4帧信号：
三帧0×1加一帧0×0
反旋一次共发送4帧信号：
三帧0×2加一帧0×0
信号周期20ms/帧）";
CM_ SG_ 789 ATCM_XModeSw "X模式状态";
CM_ SG_ 789 ATCM_SwitchUTurnModeSet "极限掉头开关/坦克掉头
（点击一次共发送3帧信号：
三帧0×1）";
CM_ SG_ 1214 BNCM_16_CRC1 "Profile1A:E2E CRC (SAE J1850 CRC-8) for 8 Bytes
DataID:No ASIL requirements.Not configure
CRC Reserved.";
CM_ SG_ 1214 BNCM_16_RollgCntr1 "Profile1A:E2E Rolling message counter(the maximum value of Alive counter is 14)要求启动计数，每发一帧计数一次，到最大值14之后从0重新计数，防止有两个连续单帧的情况发生";
CM_ SG_ 1214 BNCM_16_Resd1 "Profile1A:E2E Reserved";
CM_ SG_ 1095 RLCR_1_CRC1 "Profile1A:E2E CRC (SAE J1850 CRC-8) for 8 Bytes
DataID:0x0044";
CM_ SG_ 1095 RLCR_1_RollgCntr1 "Profile1A:E2E Rolling message counter(the maximum value of Alive counter is 14)";
CM_ SG_ 1095 RLCR_1_Resd1 "Profile1A:E2E Reserved";
CM_ SG_ 1095 RLCR_1_SysSt "System self-test State";
CM_ SG_ 1095 RLCR_1_BlkSts "Blockage Status";
CM_ SG_ 1095 RLCR_1_BSDWarn "BSD/LCA Warning";
CM_ SG_ 1095 RLCR_1_DOWWarn "Door open warning Warning";
CM_ SG_ 1095 RLCR_1_DowLock "Door locking Warning（功能预留不发）";
CM_ SG_ 1267 RRCR_1_CRC1 "Profile1A:E2E CRC (SAE J1850 CRC-8) for 8 Bytes
DataID:0x0046";
CM_ SG_ 1267 RRCR_1_RollgCntr1 "Profile1A:E2E Rolling message counter(the maximum value of Alive counter is 14)";
CM_ SG_ 1267 RRCR_1_Resd1 "Profile1A:E2E Reserved";
CM_ SG_ 1267 RRCR_1_SysSt "System self-test State";
CM_ SG_ 1267 RRCR_1_BlkSts "Blockage Status";
CM_ SG_ 1267 RRCR_1_BSDWarn "BSD/LCA Warning";
CM_ SG_ 1267 RRCR_1_DOWWarn "Door open warning Warning";
CM_ SG_ 1267 RRCR_1_DowLock "Door locking Warning（功能预留不发）";
CM_ SG_ 788 ADS_2_AEBStatus "AEB状态信号
以下为平台化库数据内容
0x0:OFF
0x1:ON
0x2:Failure
0x3:no_active(0x3:available捷途使用)
0x4:active
0x5:pre-fill
0x6 blindness(捷途使用)";
CM_ SG_ 788 ADS_2_FCWStatus "FCW状态信号";
CM_ SG_ 788 FCM_2_IHCfunctionSts "远近光自动切换功能状态";
CM_ SG_ 571 LHTurnlightSts "转向灯-左";
CM_ SG_ 571 RHTurnlightSts "转向灯-右";
CM_ SG_ 571 LHFDoorLockSts "主驾门锁";
CM_ SG_ 571 LHTurnSW "左转向开关，打开发1；关闭发0，默认发0";
CM_ SG_ 571 RHTurnSW "右转向开关，打开发1；关闭发0，默认发0";
CM_ SG_ 571 HazardLightSW "带自锁的开关，按照危险灯状态发送；不带自锁的开关，发送危险灯状态";
CM_ SG_ 571 LHFSeatBeltSW "安全带检测开关，0为未插入，1为插入";
CM_ SG_ 571 DirectionIndLeft "当左转向灯闪烁时一直发1，转向灯熄灭时一直发0.";
CM_ SG_ 571 DirectionIndRight "当右转向灯闪烁时一直发1，转向灯熄灭时一直发0.";
CM_ SG_ 699 LHRdoorSts "左后门状态";
CM_ SG_ 787 ChrgHoodSts "充电口盖状态反馈
股份FLZCU0x33E发，捷途由FRZCU发";
CM_ SG_ 787 FRZCU_FRSitPosnSts "副驾座椅记忆位置反馈";
CM_ SG_ 524 ADS_6_CRC1 "Profile1A:E2E CRC (SAE J1850 CRC-8) for 8 Bytes
DataID:0x00F9";
CM_ SG_ 524 ADS_6_RollgCntr1 "Profile1A:E2E Rolling message counter(the maximum value of Alive counter is 14)";
CM_ SG_ 524 ADS_6_Resd1 "Profile1A:E2E Reserved";
CM_ SG_ 524 ADS_6_AVM_FuncSts "AVM当前激活状态";
CM_ SG_ 524 ADS_6_AVM_ButtonClick "AVM按键音请求";
CM_ SG_ 524 ADS_6_Customize_buttonsFB "自定义按键大屏设置设置项反馈
0x4:记忆泊车";
CM_ SG_ 524 ADS_6_PAS_AudioTone "倒车雷达报警声音";
CM_ SG_ 572 ONEBOX_7_TAB_HighTemp "坦克转弯工作温度过高";
CM_ SG_ 572 ONEBOX_7_TAB_Active "IPB反馈TAB状态";
CM_ SG_ 572 ONEBOX_7_BSW_Active "智能擦盘状态反馈信号";
CM_ SG_ 572 ONEBOX_7_iCCO_TgtVel "iCCO功能目标车速";
CM_ SG_ 1212 VCU_3_G_ActWheelTorqueFA "Actual wheel torque at FA前轮轮端实际扭矩";
CM_ SG_ 1212 VCU_3_G_ActWheelTorqueRA "Actual wheel torque at RA后轮轮端实际扭矩";
CM_ SG_ 783 ADCC_SysReadySts "ADAS系统状态";
CM_ SG_ 943 CSA_3_CRC1 "Profile1A:E2E CRC (SAE J1850 CRC-8) for 8 Bytes
DataID:Reserved";
CM_ SG_ 943 CSA_3_RollgCntr1 "Profile1A:E2E Rolling message counter(the maximum value of Alive counter is 14)";
CM_ SG_ 943 CSA_3_Resd1 "Profile1A:E2E Reserved";
CM_ SG_ 943 FlwheelBearing "持续发送左前轮载荷值(吨)";
CM_ SG_ 943 FrwheelBearing "持续发送右前轮载荷值(吨)";
CM_ SG_ 943 BlwheelBearing "持续发送左后轮载荷值(吨)";
CM_ SG_ 943 BrwheelBearing "持续发送右后轮载荷值(吨)";
CM_ SG_ 943 CSA_3_CRC2 "Profile1A:E2E CRC (SAE J1850 CRC-8) for 8 Bytes
DataID:Reserved";
CM_ SG_ 943 CSA_3_RollgCntr2 "Profile1A:E2E Rolling message counter(the maximum value of Alive counter is 14)";
CM_ SG_ 943 VehicleBearing_kg "持续发送整车重量(kg)";
CM_ SG_ 943 VehicleBearing_lb "持续发送整车重量(lb)";
CM_ SG_ 943 GoodsWeight_kg "持续发送货物重量(kg)";
CM_ SG_ 943 Goods_Weight_Ratio "持续发送货物重量百分比(%)";
CM_ SG_ 943 CSA_3_CRC3 "Profile1A:E2E CRC (SAE J1850 CRC-8) for 8 Bytes
DataID:Reserved";
CM_ SG_ 943 CSA_3_RollgCntr3 "Profile1A:E2E Rolling message counter(the maximum value of Alive counter is 14)";
CM_ SG_ 943 CSA_3_Resd3 "Profile1A:E2E Reserved";
CM_ SG_ 943 GoodsWeight_lb "持续发送货物重量(lb)";
CM_ SG_ 943 OverWeightValue_kg "持续发送超重值（kg)";
CM_ SG_ 943 OverWeightValue_lb "持续发送超重值（lb)";
CM_ SG_ 943 OverWeightRatio "持续发送超重百公比(%)";
CM_ SG_ 943 OverWeightWarning "超重时发送超重报警信号";
CM_ SG_ 943 OverLoadWarnShieldSetFed "大屏重量报警屏蔽软开关反馈信号";
CM_ SG_ 1120 RLHS_2_AmbBrightness "顶向光";
CM_ SG_ 1120 RLHS_LiSwithReason "开关灯切换原因
RLS_ LightSwithReason";
CM_ SG_ 850 ASU_6_HMIFailFb_JT "0x0:无状态，不显示
0x1:悬架调节已锁定，请先解除锁定
0x2:尾门未关闭，载物模式已退出
0x3:悬架高度调节已禁用
0x4:悬架软硬调节已禁用
0x5:当前海拔过高，悬架高度调节已禁用
0x6~0xF:reserved";
CM_ SG_ 1199 TCM_1_TrailerSts "Trailer Status send by TCM. Vehicle can use this information to turn off/on some assistance like Park Distance Control. Furthermore it might be used to turn off the fog light on the vehicle when a trailer is connected (at least in germany, there is a law saying that the vehicles fog lamp must not be turned on when a trailer is connected - only the fog of the trailer should be turned on).";
CM_ SG_ 770 ADS_RPAOnlineOrNot_302h "RPA业务心跳消息";
CM_ SG_ 770 ADS_RpaParkAuthn_302h "RPA泊车授权";
CM_ SG_ 770 ADS_SeldParkID_302h "选中的目标车位ID号";
CM_ SG_ 770 ADS_VehParkMod_302h "自车泊入方式";
CM_ SG_ 770 ADS_RemParkPatSel_302h "RPA远程泊车模式选择确认";
CM_ SG_ 770 ADS_ParkDirCfm_302h "RPA泊出方向确认";
CM_ SG_ 770 ADS_ParkProgs_302h "泊车进度0~100%";
CM_ SG_ 770 ADS_ParkRmngDst_302h "泊车剩余距离0~50m";
CM_ SG_ 770 ADS_ObstclDst_302h "障碍物距离";
CM_ SG_ 770 ADS_AutEve_302h "智能驾驶事件（RPA指示信息）";
CM_ SG_ 770 ADS_parkInterruptDuration_302h "RPA暂停倒计时";
CM_ SG_ 770 APA_ResuAvl_302h "RPA功能是否可以恢复泊车";
CM_ SG_ 770 ADS_ParkStMac_302h "泊车状态机";
CM_ SG_ 770 ADS_ParkOutDir_ParaLe_302h "水平向左";
CM_ SG_ 770 ADS_ParkOutDir_ParaRi_302h "水平向右";
CM_ SG_ 770 ADS_ParkOutDir_PerpFwd_302h "垂直向前";
CM_ SG_ 770 ADS_ParkOutDir_PerpLeFwd_302h "垂直向左前";
CM_ SG_ 770 ADS_ParkOutDir_PerpRiFwd_302h "垂直向右前";
CM_ SG_ 770 ADS_ParkOutDir_PerpLeBack_302h "垂直向左后";
CM_ SG_ 770 ADS_ParkOutDir_PerpRiBack_302h "垂直向右后";
CM_ SG_ 770 ADS_ParkOutDir_PerpBack_302h "垂直向后";
CM_ SG_ 770 APA_RPAFctUnavlMsg_1_302h "RPA功能不可用原因1";
CM_ SG_ 770 APA_RPAFctUnavlMsg_2_302h "RPA功能不可用原因2";
CM_ SG_ 770 APA_RPAFctUnavlMsg_3_302h "RPA功能不可用原因3";
CM_ SG_ 770 APA_RPAFctUnavlMsg_4_302h "RPA功能不可用原因4";
CM_ SG_ 770 APA_RPAFctUnavlMsg_5_302h "RPA功能不可用原因5";
CM_ SG_ 770 APA_RPAFctUnavlMsg_6_302h "RPA功能不可用原因6";
CM_ SG_ 770 APA_RPAFctUnavlMsg_7_302h "RPA功能不可用原因7";
CM_ SG_ 770 APA_RPAFctUnavlMsg_8_302h "RPA功能不可用原因8";
CM_ SG_ 770 APA_RPAFctUnavlMsg_9_302h "RPA功能不可用原因9";
CM_ SG_ 770 APA_RPAFctUnavlMsg_10_302h "RPA功能不可用原因10";
CM_ SG_ 770 APA_RPAFctUnavlMsg_11_302h "RPA功能不可用原因11";
CM_ SG_ 770 APA_RPAFctUnavlMsg_12_302h "RPA功能不可用原因12";
CM_ SG_ 770 APA_RPAFctUnavlMsg_13_302h "RPA功能不可用原因13";
CM_ SG_ 770 APA_RPAFctUnavlMsg_14_302h "RPA功能不可用原因14";
CM_ SG_ 770 APA_RPAFctUnavlMsg_15_302h "RPA功能不可用原因15";
CM_ SG_ 770 APA_RPAFctUnavlMsg_16_302h "RPA功能不可用原因16";
CM_ SG_ 770 APA_RPAFctUnavlMsg_17_302h "RPA功能不可用原因17";
CM_ SG_ 770 APA_RPAFctUnavlMsg_18_302h "RPA功能不可用原因18";
CM_ SG_ 770 APA_RPAFctUnavlMsg_19_302h "RPA功能不可用原因19";
CM_ SG_ 770 APA_RPAFctUnavlMsg_20_302h "RPA功能不可用原因20";
CM_ SG_ 770 APA_RPAFctUnavlMsg_21_302h "RPA功能不可用原因21";
CM_ SG_ 770 APA_RPAFctUnavlMsg_22_302h "RPA功能不可用原因22";
CM_ SG_ 770 APA_RPAFctUnavlMsg_23_302h "RPA功能不可用原因23";
CM_ SG_ 770 APA_RPAFctUnavlMsg_24_302h "RPA功能不可用原因24";
CM_ SG_ 770 APA_RPAFctUnavlMsg_25_302h "RPA功能不可用原因25";
CM_ SG_ 770 APA_RPACnclMsg_1_302h "RPA功能取消原因1";
CM_ SG_ 770 APA_RPACnclMsg_2_302h "RPA功能取消原因2";
CM_ SG_ 770 APA_RPACnclMsg_3 "RPA功能取消原因3";
CM_ SG_ 770 APA_RPACnclMsg_4_302h "RPA功能取消原因4";
CM_ SG_ 770 APA_RPACnclMsg_5_302h "RPA功能取消原因5";
CM_ SG_ 770 APA_RPACnclMsg_6_302h "RPA功能取消原因6";
CM_ SG_ 770 APA_RPACnclMsg_7_302h "RPA功能取消原因7";
CM_ SG_ 770 APA_RPACnclMsg_8_302h "RPA功能取消原因8";
CM_ SG_ 770 APA_RPACnclMsg_9_302h "RPA功能取消原因9";
CM_ SG_ 770 APA_RPACnclMsg_10_302h "RPA功能取消原因10";
CM_ SG_ 770 APA_RPACnclMsg_11_302h "RPA功能取消原因11";
CM_ SG_ 770 APA_RPACnclMsg_12_302h "RPA功能取消原因12";
CM_ SG_ 770 APA_RPACnclMsg_13_302h "RPA功能取消原因13";
CM_ SG_ 770 APA_RPACnclMsg_14_302h "RPA功能取消原因14";
CM_ SG_ 770 APA_RPACnclMsg_15_302h "RPA功能取消原因15";
CM_ SG_ 770 APA_RPACnclMsg_16_302h "RPA功能取消原因16";
CM_ SG_ 770 APA_RPACnclMsg_17_302h "RPA功能取消原因17";
CM_ SG_ 770 APA_RPACnclMsg_18_302h "RPA功能取消原因18";
CM_ SG_ 770 APA_RPACnclMsg_19_302h "RPA功能取消原因19";
CM_ SG_ 770 APA_RPACnclMsg_20_302h "RPA功能取消原因20";
CM_ SG_ 770 APA_RPAPauseMsg_1_302h "RPA功能暂停原因1";
CM_ SG_ 770 APA_RPAPauseMsg_2_302h "RPA功能暂停原因2";
CM_ SG_ 770 APA_RPAPauseMsg_3_302h "RPA功能暂停原因3";
CM_ SG_ 770 APA_RPAPauseMsg_4_302h "RPA功能暂停原因4";
CM_ SG_ 770 APA_RPAPauseMsg_5_302h "RPA功能暂停原因5";
CM_ SG_ 770 APA_RPAPauseMsg_6_302h "RPA功能暂停原因6";
CM_ SG_ 770 APA_RPAPauseMsg_7_302h "RPA功能暂停原因7";
CM_ SG_ 770 APA_RPAPauseMsg_8_302h "RPA功能暂停原因8";
CM_ SG_ 770 APA_RPAPauseMsg_9_302h "RPA功能暂停原因9";
CM_ SG_ 770 APA_RPAPauseMsg_10_302h "RPA功能暂停原因10";
CM_ SG_ 770 ADS_ParkPosn1_ID_302h "车位1_ID号0~15";
CM_ SG_ 770 ADS_MnvrOrintChng1_302h "目标车位1类型";
CM_ SG_ 770 ADS_MnvrOrintChng2_302h "目标车位2类型";
CM_ SG_ 770 ADS_ParkRelPos1_x1_302h "目标车位相对位置1_x1(-50.0~50.0m)";
CM_ SG_ 770 ADS_ParkRelPos1_y1_302h "目标车位相对位置1_y1(-50.0~50.0m)";
CM_ SG_ 770 ADS_ParkRelPos1_x2_302h "目标车位相对位置1_x2(-50.0~50.0m)";
CM_ SG_ 770 ADS_ParkRelPos1_y2_302h "目标车位相对位置1_y2(-50.0~50.0m)";
CM_ SG_ 770 ADS_ParkRelPos1_x3_302h "目标车位相对位置1_x3(-50.0~50.0m)";
CM_ SG_ 770 ADS_TarParkSt_Posn1_302h "目标车位1的状态";
CM_ SG_ 770 ADS_ParkChkSrc_Posn1_302h "目标车位1检测来源";
CM_ SG_ 770 ADS_VdcActvSts_302h "VDC激活状态";
CM_ SG_ 770 ADS_TcsActvSts_302h "TCS激活状态";
CM_ SG_ 770 ADS_ParkRelPos1_y3_302h "目标车位相对位置1_y3(-50.0~50.0m)";
CM_ SG_ 770 ADS_ParkRelPos1_x4_302h "目标车位相对位置1_x4(-50.0~50.0m)";
CM_ SG_ 770 ADS_ParkRelPos1_y4_302h "目标车位相对位置1_y4(-50.0~50.0m)";
CM_ SG_ 770 ADS_ParkPosn2_ID_302h "车位2_ID号(0~15)";
CM_ SG_ 770 ADS_ParkRelPos2_x1_302h "目标车位相对位置2_x1(-50.0~50.0m)";
CM_ SG_ 770 ADS_ParkRelPos2_y1_302h "目标车位相对位置2_y1(-50.0~50.0m)";
CM_ SG_ 770 ADS_ParkRelPos2_x2_302h "目标车位相对位置2_x2(-50.0~50.0m)";
CM_ SG_ 770 ADS_ParkRelPos2_y2_302h "目标车位相对位置2_y2(-50.0~50.0m)";
CM_ SG_ 770 ADS_ParkRelPos2_x3_302h "目标车位相对位置2_x3(-50.0~50.0m)";
CM_ SG_ 770 ADS_TarParkSt_Posn2_302h "目标车位2的状态";
CM_ SG_ 770 ADS_ParkChkSrc_Posn2_302h "目标车位2检测来源";
CM_ SG_ 770 ADS_ParkRelPos2_y3_302h "目标车位相对位置2_y3(-50.0~50.0m)";
CM_ SG_ 770 ADS_ParkRelPos2_x4_302h "目标车位相对位置2_x4(-50.0~50.0m)";
CM_ SG_ 770 ADS_ParkRelPos2_y4_302h "目标车位相对位置2_y4(-50.0~50.0m)";
CM_ SG_ 514 ADS_AdsFault_202h "ADS系统故障";
CM_ SG_ 514 ADS_NicaReminderLEDVisual_202h "ADS功能接告警灯提醒";
CM_ SG_ 514 ADS_NicaReminderAcoustic_202h "ADS功能告警声音提醒";
CM_ SG_ 514 ADS_TakeoverID_202h "ADS功能接管提醒ID";
CM_ SG_ 514 ADS_TakeoverLevel_202h "TORLevel";
CM_ SG_ 514 ADS_TakeoverType_202h "TORType";
CM_ SG_ 514 ADS_TORIDCorrespErrorID_202h "TOR对应的error code ID";
CM_ SG_ 514 ADS_TakeoverExtended16bit_202h "接管扩展字段(如：弹窗内数值显示)";
CM_ SG_ 514 ADS_TakeoverExtended8bit_202h "接管扩展字段(如：功能激活失败)";
CM_ SG_ 1041 ADS_RadarWarning0Distance_411h "雷达告警扇区与障碍物距离";
CM_ SG_ 1041 ADS_RadarWarning1Distance_411h "雷达告警扇区与障碍物距离";
CM_ SG_ 1041 ADS_RadarWarning2Distance_411h "雷达告警扇区与障碍物距离";
CM_ SG_ 1041 ADS_RadarWarning3Distance_411h "雷达告警扇区与障碍物距离";
CM_ SG_ 1041 ADS_RadarWarning4Distance_411h "雷达告警扇区与障碍物距离";
CM_ SG_ 1041 ADS_RadarWarning5Distance_411h "雷达告警扇区与障碍物距离";
CM_ SG_ 1041 ADS_RadarWarning6Distance_411h "雷达告警扇区与障碍物距离";
CM_ SG_ 1041 ADS_RadarWarning7Distance_411h "雷达告警扇区与障碍物距离";
CM_ SG_ 1041 ADS_RadarWarning8Distance_411h "雷达告警扇区与障碍物距离";
CM_ SG_ 1041 ADS_RadarWarning9Distance_411h "雷达告警扇区与障碍物距离";
CM_ SG_ 1041 ADS_RadarWarning10Distance_411h "雷达告警扇区与障碍物距离";
CM_ SG_ 1041 ADS_RadarWarning11Distance_411h "雷达告警扇区与障碍物距离";
CM_ SG_ 1041 ADS_RadarWarning12Distance_411h "雷达告警扇区与障碍物距离";
CM_ SG_ 1041 ADS_RadarWarning13Distance_411h "雷达告警扇区与障碍物距离";
CM_ SG_ 1041 ADS_RadarWarning14Distance_411h "雷达告警扇区与障碍物距离";
CM_ SG_ 1041 ADS_RadarWarning15Distance_411h "雷达告警扇区与障碍物距离";
CM_ SG_ 1041 ADS_RadarWarning0AcLvl_411h "雷达告警扇区与障碍物声音报警等级";
CM_ SG_ 1041 ADS_RadarWarning1AcLvl_411h "雷达告警扇区与障碍物声音报警等级";
CM_ SG_ 1041 ADS_RadarWarning2AcLvl_411h "雷达告警扇区与障碍物声音报警等级";
CM_ SG_ 1041 ADS_RadarWarning3AcLvl_411h "雷达告警扇区与障碍物声音报警等级";
CM_ SG_ 1041 ADS_RadarWarning4AcLvl_411h "雷达告警扇区与障碍物声音报警等级";
CM_ SG_ 1041 ADS_RadarWarning5AcLvl_411h "雷达告警扇区与障碍物声音报警等级";
CM_ SG_ 1041 ADS_RadarWarning6AcLvl_411h "雷达告警扇区与障碍物声音报警等级";
CM_ SG_ 1041 ADS_RadarWarning7AcLvl_411h "雷达告警扇区与障碍物声音报警等级";
CM_ SG_ 1041 ADS_RadarWarning8AcLvl_411h "雷达告警扇区与障碍物声音报警等级";
CM_ SG_ 1041 ADS_RadarWarning9AcLvl_411h "雷达告警扇区与障碍物声音报警等级";
CM_ SG_ 1041 ADS_RadarWarning10AcLvl_411h "雷达告警扇区与障碍物声音报警等级";
CM_ SG_ 1041 ADS_RadarWarning11AcLvl_411h "雷达告警扇区与障碍物声音报警等级";
CM_ SG_ 1041 ADS_RadarWarning12AcLvl_411h "雷达告警扇区与障碍物声音报警等级";
CM_ SG_ 1041 ADS_RadarWarning13AcLvl_411h "雷达告警扇区与障碍物声音报警等级";
CM_ SG_ 1041 ADS_RadarWarning14AcLvl_411h "雷达告警扇区与障碍物声音报警等级";
CM_ SG_ 1041 ADS_RadarWarning15AcLvl_411h "雷达告警扇区与障碍物声音报警等级";
CM_ SG_ 1041 ADC_FuncReq_SentryModWarn_411h "ADS哨兵模式告警唤醒功能报文";
CM_ SG_ 1041 ADC_FuncReq_SentryModDetec_411h "哨兵模式功能维持信号";
CM_ SG_ 1041 ADC_MdcSentryAlarmMod_411h "ADS哨兵模式警告";
CM_ SG_ 769 ADS_AccFunctionStatus_301h "ACC功能状态机";
CM_ SG_ 769 ADS_LccNcaFunctionStatus_301h "LCC和NCA的功能状态机";
CM_ SG_ 769 ADS_AdsFucntionNotActive_301h "ADS无法激活";
CM_ SG_ 769 ADS_AvpFunctionStatus_301h "AVP的功能状态机";
CM_ SG_ 769 ADS_SpeedSetByDriver_301h "ADS 智驾定速值";
CM_ SG_ 769 ADS_SpeedLimitValue_301h "ADS 道路限速值";
CM_ SG_ 769 ADS_SpeedAutoFollow_301h "智能限速状态";
CM_ SG_ 769 ADS_OneTouchSpeedAdjustment_301h "非智能限速一键调速";
CM_ SG_ 769 ADS_CalibState_301h "标定状态";
CM_ SG_ 769 ADS_HODReminder_301h "脱手提醒";
CM_ SG_ 769 ADS_DMSReminder_301h "DIL提醒";
CM_ SG_ 769 ADS_FcwWaning_301h "FCW告警";
CM_ SG_ 769 ADS_FcwFault_301h "FCW故障";
CM_ SG_ 769 ADS_AebWaning_301h "AEB告警";
CM_ SG_ 769 ADS_AebFault_301h "AEB故障";
CM_ SG_ 769 ADS_AebObjType_301h "AEB触发障碍物类型";
CM_ SG_ 769 ADS_RaebWarning_301h "RAEB告警";
CM_ SG_ 769 ADS_RaebFault_301h "RAEB故障";
CM_ SG_ 769 ADS_RcwWarning_301h "RCW告警";
CM_ SG_ 769 ADS_RcwFault_301h "RCW故障";
CM_ SG_ 769 ADS_FctaLeftWarning_301h "左FCTA告警";
CM_ SG_ 769 ADS_FctaRightWarning_301h "右FCTA告警";
CM_ SG_ 769 ADS_FctbLeftWarning_301h "左FCTB告警";
CM_ SG_ 769 ADS_FctbRightWarning_301h "右FCTB告警";
CM_ SG_ 769 ADS_RctaLeftWarning_301h "左RCTA告警";
CM_ SG_ 769 ADS_RctaRightWarning_301h "右RCTA告警";
CM_ SG_ 769 ADS_RctaFault_301h "RCTA故障";
CM_ SG_ 769 ADS_RctbLeftWarning_301h "左RCTB告警";
CM_ SG_ 769 ADS_RctbRightWarning_301h "右RCTB告警";
CM_ SG_ 769 ADS_LdwWarning_301h "LDW告警";
CM_ SG_ 769 ADS_LdwFault_301h "LDW故障";
CM_ SG_ 769 ADS_LKAWarning_301h "LKA告警";
CM_ SG_ 769 ADS_LkaFault_301h "LKA故障";
CM_ SG_ 769 ADS_LeftMirrWarningCmd_301h "左BSD告警";
CM_ SG_ 769 ADS_RightMirrWarningCmd_301h "右BSD告警";
CM_ SG_ 769 ADS_BsdFault_301h "BSD故障";
CM_ SG_ 769 ADS_LeFrntDoorWarningCmd_301h "左前门的告警";
CM_ SG_ 769 ADS_LeReDoorWarningCmd_301h "左后门的告警";
CM_ SG_ 769 ADS_RiFrntDoorWarningCmd_301h "右前门的告警";
CM_ SG_ 769 ADS_RiReDoorWarningCmd_301h "右后门的告警";
CM_ SG_ 769 ADS_DowFault_301h "DOW故障";
CM_ SG_ 769 ADS_SpeedLimitWarning_301h "超速告警";
CM_ SG_ 769 ADS_TsrFault_301h "TSR故障";
CM_ SG_ 769 ADS_TlaFault_301h "TLA故障";
CM_ SG_ 769 ADS_ElkaFault_301h "ELKA故障";
CM_ SG_ 769 ADS_AbsoultwSpeedLimit_301h "设定的绝对限速值";
CM_ SG_ 769 ADS_TlaWarning_301h "TLA告警";
CM_ SG_ 769 ADS_ElkaWarning_301h "ELKA告警";
CM_ SG_ 1042 ADS_BrkBeamReq_412h "刹车灯开启请求";
CM_ SG_ 1042 ADS_AutoLightSwCtrl_412h "自动灯光控制（Auto）";
CM_ SG_ 1042 ADS_LeFrntDowWarning_412h "左前门氛围灯报警";
CM_ SG_ 1042 ADS_RiFrntDowWarning_412h "右前门氛围灯报警";
CM_ SG_ 1042 ADS_LeReDowWarning_412h "左后门氛围灯报警";
CM_ SG_ 1042 ADS_RiReDowWarning_412h "右后门氛围灯报警";
CM_ SG_ 1042 ADS_LeftMirrWarningCmd_412h "左后视镜告警请求";
CM_ SG_ 1042 ADS_RightMirrWarningCmd_412h "右后视镜告警请求";
CM_ SG_ 1042 ADS_ReMirrReq_412h "后视镜控制请求";
CM_ SG_ 1042 ADS_DoorLockReq_412h "车门解闭锁控制请求";
CM_ SG_ 1042 ADS_SBeltControl_412h "主动安全带控制";
CM_ SG_ 1042 ADS_WshrReq_412h "洗涤点动开启请求";
CM_ SG_ 1042 ADS_SeatShakeControl_412h "座椅震动提示";
CM_ SG_ 1042 ADS_FrtWindshildHeatReq_412h "前风挡加热丝控制请求";
CM_ SG_ 1042 ADS_HornReq_412h "喇叭开启请求";
CM_ SG_ 1042 ADS_LeFmtWinCtrl_412h "驾驶员侧车窗控制";
CM_ SG_ 1042 ADS_RiFmtWinCtrl_412h "副驾驶员侧车窗控制";
CM_ SG_ 1042 ADS_LeReWinCtrl_412h "左后侧车窗控制";
CM_ SG_ 1042 ADS_RiReWinCtrl_412h "右后侧车窗控制";
CM_ SG_ 1042 ADS_TopWinCtrl_412h "天窗控制（若有）";
CM_ SG_ 1042 ADS_FrontWiperReq_412h "雨刮开启请求";
CM_ SG_ 1042 ADS_ChargingPortCmd_412h "充电口控制";
CM_ SG_ 1042 ADAS_FctSts_412h "智驾功能状态";
CM_ SG_ 1042 ADS_MdcCrtSts_412h "MDC工作状态";
CM_ SG_ 1042 ADS_HVCtrlReq_412h "MDC请求高压";
CM_ SG_ 1042 ADS_ThmPostRun_412h "MDC液冷需求";
CM_ SG_ 1042 ADS_FlowReq_412h "MDC冷却液流速请求（百分比或枚举如下）";
CM_ SG_ 1042 ADS_PwrOnOffReq_412h "整车上下电控制请求
泊车上下电和上下Ready";
CM_ SG_ 1042 ADS_hmaOnOffSts_412h "智能大灯辅助(HMA)功能开启/关闭状态信号";
CM_ SG_ 1042 ADS_HMAStatus_412h "智能远光灯状态";
CM_ SG_ 1042 ADS_HiBeamReq_412h "HMA远光灯控制请求";
CM_ SG_ 1046 LBMS_LoWSocFlt "SOC过低故障(同时也是电量告警整车的标志)";
CM_ SG_ 1046 LBMS_ThermRunawayFlt "热失控故障";
CM_ SG_ 1046 LBMS_SysFlt "低压电池故障状态";
CM_ SG_ 1046 LBMS_LowPowerRemind "锁电信号提示";
CM_ SG_ 1046 LBMS_EndLifeFlt "锂电池寿命终结信号，SOH≤70%置为1";
BA_DEF_ BO_  "GenMsgCycleTimeFast" INT 0 50000;
BA_DEF_ BO_  "GenMsgNrOfRepetition" INT 0 999999;
BA_DEF_ BO_  "GenMsgDelayTime" INT 0 1000;
BA_DEF_ BO_  "VFrameFormat" ENUM  "StandardCAN","ExtendedCAN","reserved","reserved","reserved","reserved","reserved","reserved","reserved","reserved","reserved","reserved","reserved","reserved","StandardCAN_FD","ExtendedCAN_FD";
BA_DEF_ BO_  "GenMsgILSupport" ENUM  "No","Yes";
BA_DEF_ BO_  "NmMessage" ENUM  "No","Yes";
BA_DEF_ BO_  "GenMsgSendType" ENUM  "Cycle","Event","IfActive","CE","CA","NoMsgSendType";
BA_DEF_ BO_  "GenMsgCycleTime" INT 0 50000;
BA_DEF_ BO_  "CANFD_BRS" INT 0 1;
BA_DEF_ BO_  "NmAsrMessage" ENUM  "No","Yes";
BA_DEF_ BO_  "GRC_ASIL" ENUM  "vector_leerstring","QM","A","B","C","D";
BA_DEF_ BO_  "GRC_History" STRING ;
BA_DEF_ SG_  "GenSigStartValue" FLOAT 0 100000000000;
BA_DEF_ SG_  "GenSigInactiveValue" INT 0 100000;
BA_DEF_ SG_  "GenSigInvalidValue" INT 0 100000;
BA_DEF_ SG_  "GenSigSendType" ENUM  "Cycle","OnChange","OnWrite","IfActive","OnChangeWithRepetition","OnWriteWithRepetition","IfActiveWithRepetition","NoSigSendType","OnChangeAndIfActive","OnChangeAndIfActiveWithRepetition","CA","CE","Event";
BA_DEF_ SG_  "GRC_Sig_ASIL" ENUM  "vector_leerstring","QM","A","B","C","D";
BA_DEF_ SG_  "E2EDataId" INT 0 0;
BA_DEF_ SG_  "E2EProfile" STRING ;
BA_DEF_ SG_  "E2EDataLength" INT 0 512;
BA_DEF_DEF_  "GenMsgCycleTimeFast" 0;
BA_DEF_DEF_  "GenMsgNrOfRepetition" 0;
BA_DEF_DEF_  "GenMsgDelayTime" 0;
BA_DEF_DEF_  "VFrameFormat" "StandardCAN";
BA_DEF_DEF_  "GenMsgILSupport" "No";
BA_DEF_DEF_  "NmMessage" "No";
BA_DEF_DEF_  "GenMsgSendType" "NoMsgSendType";
BA_DEF_DEF_  "GenMsgCycleTime" 0;
BA_DEF_DEF_  "CANFD_BRS" 0;
BA_DEF_DEF_  "NmAsrMessage" "No";
BA_DEF_DEF_  "GRC_ASIL" "";
BA_DEF_DEF_  "GRC_History" "";
BA_DEF_DEF_  "GenSigStartValue" 0;
BA_DEF_DEF_  "GenSigInactiveValue" 0;
BA_DEF_DEF_  "GenSigInvalidValue" 0;
BA_DEF_DEF_  "GenSigSendType" "NoSigSendType";
BA_DEF_DEF_  "GRC_Sig_ASIL" "";
BA_DEF_DEF_  "E2EDataId" 0;
BA_DEF_DEF_  "E2EProfile" "";
BA_DEF_DEF_  "E2EDataLength" 0;
BA_ "CANFD_BRS" BO_ 1107 1;
BA_ "GenMsgSendType" BO_ 1107 0;
BA_ "GenMsgCycleTime" BO_ 1107 100;
BA_ "GenMsgILSupport" BO_ 1107 1;
BA_ "GRC_History" BO_ 1107 "[{'approvedBy':'贾少辉','author':'吴慧','changesComments':'史文妍GL网段更新，根据与热管理TMS,UVC魏成贤、刘林森沟通：\n将TMS_UVC_WorkingBfSts名称更新为TMS_UVC_WorkingBfReq，信号描述更新为紫外线杀菌灯请求；TMS_UVC_LuminanceBfSts名称更新为TMS_UVC_LuminanceB";
BA_ "VFrameFormat" BO_ 1107 14;
BA_ "CANFD_BRS" BO_ 1175 1;
BA_ "GenMsgSendType" BO_ 1175 3;
BA_ "GenMsgCycleTime" BO_ 1175 100;
BA_ "GenMsgCycleTimeFast" BO_ 1175 20;
BA_ "GenMsgNrOfRepetition" BO_ 1175 3;
BA_ "GenMsgDelayTime" BO_ 1175 5;
BA_ "GenMsgILSupport" BO_ 1175 1;
BA_ "GRC_History" BO_ 1175 "[{'approvedBy':'贾少辉','author':'吴慧','changesComments':'刘标ICC需求新增接收CCP_2_ACFastHeat一键制热请求，D01P使用','date':'2025/3/10','ecu':'CCP_2(0x497)','ecuName':'ICC','reviewedBy':'杨华','revision':'V2.3'}]";
BA_ "VFrameFormat" BO_ 1175 14;
BA_ "CANFD_BRS" BO_ 1292 1;
BA_ "GenMsgSendType" BO_ 1292 0;
BA_ "GenMsgCycleTime" BO_ 1292 500;
BA_ "GenMsgILSupport" BO_ 1292 1;
BA_ "VFrameFormat" BO_ 1292 14;
BA_ "CANFD_BRS" BO_ 1241 1;
BA_ "GenMsgSendType" BO_ 1241 0;
BA_ "GenMsgCycleTime" BO_ 1241 100;
BA_ "GenMsgILSupport" BO_ 1241 1;
BA_ "VFrameFormat" BO_ 1241 14;
BA_ "CANFD_BRS" BO_ 49 1;
BA_ "GenMsgSendType" BO_ 49 0;
BA_ "GenMsgCycleTime" BO_ 49 10;
BA_ "GenMsgILSupport" BO_ 49 1;
BA_ "VFrameFormat" BO_ 49 14;
BA_ "CANFD_BRS" BO_ 1024 1;
BA_ "GenMsgSendType" BO_ 1024 0;
BA_ "GenMsgCycleTime" BO_ 1024 100;
BA_ "GenMsgILSupport" BO_ 1024 1;
BA_ "GRC_History" BO_ 1024 "[{'approvedBy':'贾少辉','author':'吴慧','changesComments':'同步GL网段：电子电器丁阁文需求新增一个信号Antifault_UnlockReq，无接收','date':'2025/3/17','ecu':'FRZCU_13(0x400)','ecuName':'CGW','reviewedBy':'杨华','revision':'V2.3'},{'approvedBy':'贾少辉','au";
BA_ "VFrameFormat" BO_ 1024 14;
BA_ "CANFD_BRS" BO_ 1182 1;
BA_ "GenMsgSendType" BO_ 1182 0;
BA_ "GenMsgCycleTime" BO_ 1182 100;
BA_ "GenMsgILSupport" BO_ 1182 1;
BA_ "VFrameFormat" BO_ 1182 14;
BA_ "CANFD_BRS" BO_ 290 1;
BA_ "GenMsgSendType" BO_ 290 0;
BA_ "GenMsgCycleTime" BO_ 290 10;
BA_ "GenMsgILSupport" BO_ 290 1;
BA_ "VFrameFormat" BO_ 290 14;
BA_ "CANFD_BRS" BO_ 513 1;
BA_ "GenMsgSendType" BO_ 513 0;
BA_ "GenMsgCycleTime" BO_ 513 20;
BA_ "GenMsgILSupport" BO_ 513 1;
BA_ "GRC_History" BO_ 513 "[{'approvedBy':'贾少辉','author':'吴慧','changesComments':'刘胤翠BD网段-D01华为项目新增MFSL_APA_SW开关信号，ICC接收','date':'2025/3/10','ecu':'MFSL_1(0x201)','ecuName':'ICC','reviewedBy':'杨华','revision':'V3.0'}]";
BA_ "VFrameFormat" BO_ 513 14;
BA_ "CANFD_BRS" BO_ 1152 1;
BA_ "GenMsgSendType" BO_ 1152 1;
BA_ "GenMsgCycleTimeFast" BO_ 1152 100;
BA_ "GenMsgNrOfRepetition" BO_ 1152 3;
BA_ "GenMsgDelayTime" BO_ 1152 5;
BA_ "GenMsgILSupport" BO_ 1152 1;
BA_ "GRC_History" BO_ 1152 "[{'approvedBy':'贾少辉','author':'吴慧','changesComments':'（同步D01主项目V2.3.1版本更新）章攀TBOX新增发送TBOX_SetTemperature_R信号，远控空调副驾，无接收','date':'2025/5/6','ecu':'TBOX_8(0x480)','ecuName':'CGW','reviewedBy':'杨华','revision':'V3.2'}]";
BA_ "VFrameFormat" BO_ 1152 14;
BA_ "GenMsgSendType" BO_ 1208 0;
BA_ "GenMsgCycleTime" BO_ 1208 100;
BA_ "GenMsgILSupport" BO_ 1208 1;
BA_ "VFrameFormat" BO_ 1208 14;
BA_ "CANFD_BRS" BO_ 794 1;
BA_ "GenMsgSendType" BO_ 794 0;
BA_ "GenMsgCycleTime" BO_ 794 50;
BA_ "GenMsgILSupport" BO_ 794 1;
BA_ "GRC_History" BO_ 794 "[{'approvedBy':'贾少辉','author':'吴慧','changesComments':'匹配华为MDC需求，智驾删除发送，矩阵预留（预留DA-DK路由）','date':'2025/3/10','ecu':'ADS_COM_3(0x31A)','ecuName':'ICC','reviewedBy':'杨华','revision':'V3.0'}]";
BA_ "VFrameFormat" BO_ 794 14;
BA_ "CANFD_BRS" BO_ 1155 1;
BA_ "GenMsgSendType" BO_ 1155 0;
BA_ "GenMsgCycleTime" BO_ 1155 100;
BA_ "GenMsgILSupport" BO_ 1155 1;
BA_ "VFrameFormat" BO_ 1155 14;
BA_ "CANFD_BRS" BO_ 1164 1;
BA_ "GenMsgSendType" BO_ 1164 0;
BA_ "GenMsgCycleTime" BO_ 1164 100;
BA_ "GenMsgILSupport" BO_ 1164 1;
BA_ "VFrameFormat" BO_ 1164 14;
BA_ "GenMsgSendType" BO_ 789 1;
BA_ "GenMsgCycleTimeFast" BO_ 789 20;
BA_ "GenMsgNrOfRepetition" BO_ 789 3;
BA_ "GenMsgDelayTime" BO_ 789 5;
BA_ "GenMsgILSupport" BO_ 789 1;
BA_ "VFrameFormat" BO_ 789 14;
BA_ "CANFD_BRS" BO_ 1214 1;
BA_ "GenMsgSendType" BO_ 1214 1;
BA_ "GenMsgDelayTime" BO_ 1214 5;
BA_ "GenMsgILSupport" BO_ 1214 1;
BA_ "VFrameFormat" BO_ 1214 14;
BA_ "CANFD_BRS" BO_ 1095 1;
BA_ "GenMsgSendType" BO_ 1095 0;
BA_ "GenMsgCycleTime" BO_ 1095 100;
BA_ "GenMsgILSupport" BO_ 1095 1;
BA_ "GRC_History" BO_ 1095 "[{'approvedBy':'贾少辉','author':'吴慧','changesComments':'匹配华为MDC需求，重新编制DA矩阵，矩阵预留（预留DA-DK路由）','date':'2025/3/10','ecu':'RLCR_1(0x447)','ecuName':'ICC','reviewedBy':'杨华','revision':'V3.0'}]";
BA_ "VFrameFormat" BO_ 1095 14;
BA_ "CANFD_BRS" BO_ 1267 1;
BA_ "GenMsgSendType" BO_ 1267 0;
BA_ "GenMsgCycleTime" BO_ 1267 100;
BA_ "GenMsgILSupport" BO_ 1267 1;
BA_ "GRC_History" BO_ 1267 "[{'approvedBy':'贾少辉','author':'吴慧','changesComments':'匹配华为MDC需求，重新编制DA矩阵，矩阵预留（预留DA-DK路由）','date':'2025/3/10','ecu':'RRCR_1(0x4F3)','ecuName':'ICC','reviewedBy':'杨华','revision':'V3.0'}]";
BA_ "VFrameFormat" BO_ 1267 14;
BA_ "CANFD_BRS" BO_ 788 1;
BA_ "GenMsgSendType" BO_ 788 0;
BA_ "GenMsgCycleTime" BO_ 788 50;
BA_ "GenMsgILSupport" BO_ 788 1;
BA_ "GRC_History" BO_ 788 "[{'approvedBy':'贾少辉','author':'吴慧','changesComments':'匹配华为MDC需求，智驾删除发送，矩阵预留（预留DA-DK路由）','date':'2025/3/10','ecu':'ADS_COM_2(0x314)','ecuName':'ICC','reviewedBy':'杨华','revision':'V3.0'}]";
BA_ "VFrameFormat" BO_ 788 14;
BA_ "CANFD_BRS" BO_ 571 1;
BA_ "GenMsgSendType" BO_ 571 0;
BA_ "GenMsgCycleTime" BO_ 571 20;
BA_ "GenMsgILSupport" BO_ 571 1;
BA_ "VFrameFormat" BO_ 571 14;
BA_ "CANFD_BRS" BO_ 699 1;
BA_ "GenMsgSendType" BO_ 699 0;
BA_ "GenMsgCycleTime" BO_ 699 20;
BA_ "GenMsgILSupport" BO_ 699 1;
BA_ "VFrameFormat" BO_ 699 14;
BA_ "CANFD_BRS" BO_ 787 1;
BA_ "GenMsgSendType" BO_ 787 0;
BA_ "GenMsgCycleTime" BO_ 787 50;
BA_ "GenMsgILSupport" BO_ 787 1;
BA_ "GRC_ASIL" BO_ 787 3;
BA_ "GRC_History" BO_ 787 "[{'approvedBy':'贾少辉','author':'吴慧','changesComments':'（同步D01主项目V2.3.3版本更新）同步史文妍FL网段更新：电子电器FRZCU丁阁文需求（产线需求）\n1、FRZCU_PwrOnReason信号值描述增加0xB:Diagnose_power_on_from_OFF、0xC:Diagnose_power_on_from_Comfort\n2、";
BA_ "VFrameFormat" BO_ 787 14;
BA_ "CANFD_BRS" BO_ 524 1;
BA_ "GenMsgSendType" BO_ 524 0;
BA_ "GenMsgCycleTime" BO_ 524 20;
BA_ "GenMsgILSupport" BO_ 524 1;
BA_ "GRC_History" BO_ 524 "[{'approvedBy':'贾少辉','author':'吴慧','changesComments':'匹配华为MDC需求，重新编制DA矩阵，矩阵预留（预留DA-DK路由）','date':'2025/3/10','ecu':'ADS_6(0x20C)','ecuName':'ICC','reviewedBy':'杨华','revision':'V3.0'}]";
BA_ "VFrameFormat" BO_ 524 14;
BA_ "CANFD_BRS" BO_ 572 1;
BA_ "GenMsgSendType" BO_ 572 0;
BA_ "GenMsgCycleTime" BO_ 572 20;
BA_ "GenMsgILSupport" BO_ 572 1;
BA_ "GRC_History" BO_ 572 "[{'approvedBy':'贾少辉','author':'吴慧','changesComments':'（同步T1J华为智驾版更改）汪苇CH网段-根据越野王曦秀需求：\nONEBOX_7(0x23C)新增发送ONEBOX_7_TAB_Active(TAB状态反馈)；\nONEBOX_7_TAB_HighTemp(TAB工作温度过高);ICC接收','date':'2025/3/10','ecu':'ONEB";
BA_ "VFrameFormat" BO_ 572 14;
BA_ "CANFD_BRS" BO_ 1212 1;
BA_ "GenMsgSendType" BO_ 1212 0;
BA_ "GenMsgCycleTime" BO_ 1212 100;
BA_ "GenMsgILSupport" BO_ 1212 1;
BA_ "VFrameFormat" BO_ 1212 14;
BA_ "CANFD_BRS" BO_ 783 1;
BA_ "GenMsgSendType" BO_ 783 0;
BA_ "GenMsgCycleTime" BO_ 783 50;
BA_ "GenMsgILSupport" BO_ 783 1;
BA_ "GRC_History" BO_ 783 "[{'approvedBy':'贾少辉','author':'吴慧','changesComments':'匹配华为MDC需求，重新编制DA矩阵，矩阵预留（预留DA-DK路由）','date':'2025/3/10','ecu':'ADS_COM_1(0x30F)','ecuName':'ICC','reviewedBy':'杨华','revision':'V3.0'}]";
BA_ "VFrameFormat" BO_ 783 14;
BA_ "CANFD_BRS" BO_ 1110 1;
BA_ "GenMsgSendType" BO_ 1110 1;
BA_ "GenMsgILSupport" BO_ 1110 1;
BA_ "VFrameFormat" BO_ 1110 14;
BA_ "CANFD_BRS" BO_ 1149 1;
BA_ "GenMsgSendType" BO_ 1149 1;
BA_ "GenMsgILSupport" BO_ 1149 1;
BA_ "VFrameFormat" BO_ 1149 14;
BA_ "CANFD_BRS" BO_ 1037 1;
BA_ "GenMsgSendType" BO_ 1037 0;
BA_ "GenMsgCycleTime" BO_ 1037 100;
BA_ "GenMsgILSupport" BO_ 1037 1;
BA_ "GRC_History" BO_ 1037 "[{'approvedBy':'贾少辉','author':'吴慧','changesComments':'匹配华为MDC需求，重新编制DA矩阵，矩阵预留（预留DA-DK路由）','date':'2025/3/10','ecu':'ADAS_ZCU_1(0x40D)','ecuName':'ICC','reviewedBy':'杨华','revision':'V3.0'}]";
BA_ "VFrameFormat" BO_ 1037 14;
BA_ "CANFD_BRS" BO_ 943 1;
BA_ "GenMsgSendType" BO_ 943 0;
BA_ "GenMsgCycleTime" BO_ 943 50;
BA_ "GenMsgILSupport" BO_ 943 1;
BA_ "VFrameFormat" BO_ 943 14;
BA_ "CANFD_BRS" BO_ 1120 1;
BA_ "GenMsgSendType" BO_ 1120 0;
BA_ "GenMsgCycleTime" BO_ 1120 100;
BA_ "GenMsgILSupport" BO_ 1120 1;
BA_ "VFrameFormat" BO_ 1120 14;
BA_ "CANFD_BRS" BO_ 850 1;
BA_ "GenMsgSendType" BO_ 850 0;
BA_ "GenMsgCycleTime" BO_ 850 50;
BA_ "GenMsgILSupport" BO_ 850 1;
BA_ "VFrameFormat" BO_ 850 14;
BA_ "GenMsgSendType" BO_ 1199 0;
BA_ "GenMsgCycleTime" BO_ 1199 100;
BA_ "GenMsgILSupport" BO_ 1199 1;
BA_ "VFrameFormat" BO_ 1199 14;
BA_ "CANFD_BRS" BO_ 770 1;
BA_ "GenMsgSendType" BO_ 770 0;
BA_ "GenMsgCycleTime" BO_ 770 50;
BA_ "GenMsgILSupport" BO_ 770 1;
BA_ "GRC_History" BO_ 770 "[{'approvedBy':'贾少辉','author':'吴慧','changesComments':'（同步T1J华为智驾版新增）姜新ICC需求接收报文，MDC华为智驾方案，新增DA-IC路由','date':'2025/3/10','ecu':'ADS_HW_302h(0x302)','ecuName':'ICC','reviewedBy':'杨华','revision':'V3.0'},{'approvedBy':'�";
BA_ "VFrameFormat" BO_ 770 14;
BA_ "CANFD_BRS" BO_ 514 1;
BA_ "GenMsgSendType" BO_ 514 0;
BA_ "GenMsgCycleTime" BO_ 514 20;
BA_ "GenMsgILSupport" BO_ 514 1;
BA_ "GRC_History" BO_ 514 "[{'approvedBy':'贾少辉','author':'吴慧','changesComments':'（同步T1J华为智驾版新增）姜新ICC需求接收报文，MDC华为智驾方案，新增DA-IC路由','date':'2025/3/10','ecu':'ADS_HW_202h(0x202)','ecuName':'ICC','reviewedBy':'杨华','revision':'V3.0'}]";
BA_ "VFrameFormat" BO_ 514 14;
BA_ "CANFD_BRS" BO_ 1041 1;
BA_ "GenMsgSendType" BO_ 1041 0;
BA_ "GenMsgCycleTime" BO_ 1041 100;
BA_ "GenMsgILSupport" BO_ 1041 1;
BA_ "GRC_History" BO_ 1041 "[{'approvedBy':'贾少辉','author':'吴慧','changesComments':'（同步T1J华为智驾版新增）姜新ICC需求接收报文，MDC华为智驾方案，新增DA-IC路由','date':'2025/3/10','ecu':'ADS_HW_411h(0x411)','ecuName':'ICC','reviewedBy':'杨华','revision':'V3.0'}]";
BA_ "VFrameFormat" BO_ 1041 14;
BA_ "CANFD_BRS" BO_ 769 1;
BA_ "GenMsgSendType" BO_ 769 0;
BA_ "GenMsgCycleTime" BO_ 769 50;
BA_ "GenMsgILSupport" BO_ 769 1;
BA_ "GRC_History" BO_ 769 "[{'approvedBy':'贾少辉','author':'吴慧','changesComments':'（同步T1J华为智驾版新增）姜新ICC需求接收报文，MDC华为智驾方案，新增DA-IC路由','date':'2025/3/10','ecu':'ADS_HW_301h(0x301)','ecuName':'ICC','reviewedBy':'杨华','revision':'V3.0'}]";
BA_ "VFrameFormat" BO_ 769 14;
BA_ "CANFD_BRS" BO_ 1042 1;
BA_ "GenMsgSendType" BO_ 1042 0;
BA_ "GenMsgCycleTime" BO_ 1042 100;
BA_ "GenMsgILSupport" BO_ 1042 1;
BA_ "GRC_History" BO_ 1042 "[{'approvedBy':'贾少辉','author':'吴慧','changesComments':'（同步T1J华为智驾版新增）姜新ICC需求接收报文，MDC华为智驾方案，新增DA-IC路由','date':'2025/3/10','ecu':'ADS_HW_412h(0x412)','ecuName':'ICC','reviewedBy':'杨华','revision':'V3.0'}]";
BA_ "VFrameFormat" BO_ 1042 14;
BA_ "CANFD_BRS" BO_ 1046 1;
BA_ "GenMsgSendType" BO_ 1046 0;
BA_ "GenMsgCycleTime" BO_ 1046 100;
BA_ "GenMsgILSupport" BO_ 1046 1;
BA_ "GRC_History" BO_ 1046 "[{'approvedBy':'贾少辉','author':'吴慧','changesComments':'（同步T1J华为智驾版新增）新增EP-IC路由转发：王振兴需求ICC新增接收5条信号','date':'2025/4/15','ecu':'LBMS_SysSt4(0x416)','ecuName':'ICC','reviewedBy':'杨华','revision':'V3.1'}]";
BA_ "VFrameFormat" BO_ 1046 14;
BA_ "GenSigSendType" SG_ 1107 TMS_PM25_Detect 0;
BA_ "GenSigSendType" SG_ 1107 TMS_CCP_FLTempSts 0;
BA_ "GenSigInvalidValue" SG_ 1107 TMS_CCP_FLTempSts 31;
BA_ "GenSigStartValue" SG_ 1107 TMS_CCP_FLTempSts 31;
BA_ "GenSigSendType" SG_ 1107 TMS_CCP_FrontAutoACSts 0;
BA_ "GenSigSendType" SG_ 1107 TMS_CCP_ACStatus 0;
BA_ "GenSigSendType" SG_ 1107 TMS_CCP_FrontOFFSts 0;
BA_ "GenSigSendType" SG_ 1107 TMS_CCP_FBlowSpdCtrlSts 0;
BA_ "GenSigSendType" SG_ 1107 TMS_CCP_FRTempSts 0;
BA_ "GenSigInvalidValue" SG_ 1107 TMS_CCP_FRTempSts 31;
BA_ "GenSigStartValue" SG_ 1107 TMS_CCP_FRTempSts 31;
BA_ "GenSigSendType" SG_ 1107 TMS_CCP_RecyMode 0;
BA_ "GenSigSendType" SG_ 1107 TMS_CCP_FrontDefrostSts 0;
BA_ "GenSigSendType" SG_ 1107 TMS_UVC_WorkingBfReq 0;
BA_ "GenSigSendType" SG_ 1107 TMS_UVC_LuminanceBfReq 0;
BA_ "GenSigSendType" SG_ 1107 TMS_CCP_ACFastCool 0;
BA_ "GenSigSendType" SG_ 1107 TMS_CCP_ACFastHeat 0;
BA_ "GenSigSendType" SG_ 1175 CCP_2_FRTempSwitchReq 0;
BA_ "GenSigInvalidValue" SG_ 1175 CCP_2_FRTempSwitchReq 31;
BA_ "GenSigStartValue" SG_ 1175 CCP_2_FRTempSwitchReq 31;
BA_ "GenSigSendType" SG_ 1175 CCP_2_RecyModeReq 0;
BA_ "GenSigSendType" SG_ 1175 CCP_2_DefrostModeSwitchReq 0;
BA_ "GenSigSendType" SG_ 1175 CCP_2_RearDefrostSwitchReq 0;
BA_ "GenSigSendType" SG_ 1175 CCP_2_ACFastHeat 0;
BA_ "GenSigSendType" SG_ 1175 CCP_2_FrontBlowSpdCtrlSwitchReq 0;
BA_ "GenSigSendType" SG_ 1175 FRCCP_DeputySetHeatReq 0;
BA_ "GenSigSendType" SG_ 1175 FRCCP_DeputySetVentilationReq 0;
BA_ "GenSigSendType" SG_ 1175 CCP_2_ACSwitchReq 0;
BA_ "GenSigSendType" SG_ 1292 CHB_App_Sts 0;
BA_ "GenSigSendType" SG_ 1292 CHB_AppMem_Sts 0;
BA_ "GenSigSendType" SG_ 1292 CHB_AppDelay_Sts 0;
BA_ "GenSigSendType" SG_ 1292 CHB_AppTimeset_Sts 0;
BA_ "GenSigInvalidValue" SG_ 1292 CHB_AppTimeset_Sts 31;
BA_ "GenSigSendType" SG_ 1292 CHB_AppCoolorheat_Sts 0;
BA_ "GenSigSendType" SG_ 1292 CHB_AppCoolset_Sts 0;
BA_ "GenSigSendType" SG_ 1292 CHB_AppHeatset_Sts 0;
BA_ "GenSigSendType" SG_ 1292 CHB_AppSterilization_Sts 0;
BA_ "GenSigSendType" SG_ 1292 CHB_AppItemsLeft_Sts 0;
BA_ "GenSigSendType" SG_ 1292 CHB_AppItemsLeftset_Sts 0;
BA_ "GenSigSendType" SG_ 1292 CHB_AppChbDoor_Sts 0;
BA_ "GenSigSendType" SG_ 1241 FuelTankLidSystemFailureSts 0;
BA_ "GenSigSendType" SG_ 1241 FuelTankPressureConditionReached 0;
BA_ "GRC_Sig_ASIL" SG_ 49 ACU_2_LateralAcceleration 3;
BA_ "GenSigSendType" SG_ 49 ACU_2_LateralAcceleration 0;
BA_ "GenSigInvalidValue" SG_ 49 ACU_2_LateralAcceleration 65535;
BA_ "GenSigStartValue" SG_ 49 ACU_2_LateralAcceleration 2000;
BA_ "GRC_Sig_ASIL" SG_ 49 ACU_2_YawRate 3;
BA_ "GenSigSendType" SG_ 49 ACU_2_YawRate 0;
BA_ "GenSigInvalidValue" SG_ 49 ACU_2_YawRate 65535;
BA_ "GenSigStartValue" SG_ 49 ACU_2_YawRate 18000;
BA_ "GRC_Sig_ASIL" SG_ 49 ACU_2_YawrateSigValidData 3;
BA_ "GenSigSendType" SG_ 49 ACU_2_YawrateSigValidData 0;
BA_ "GenSigStartValue" SG_ 49 ACU_2_YawrateSigValidData 3;
BA_ "GRC_Sig_ASIL" SG_ 49 ACU_2_LateralAccelerationSigVD 3;
BA_ "GenSigSendType" SG_ 49 ACU_2_LateralAccelerationSigVD 0;
BA_ "GenSigStartValue" SG_ 49 ACU_2_LateralAccelerationSigVD 3;
BA_ "GenSigSendType" SG_ 1024 FRZCU_QueenSeatPosSts 0;
BA_ "GenSigSendType" SG_ 1024 FRZCU_QueenSeatEnterSts 0;
BA_ "GenSigSendType" SG_ 1024 FRZCU_QueenSeatMovFailCause 0;
BA_ "GenSigSendType" SG_ 1024 FRZCU_QueenSeatSts 0;
BA_ "GenSigSendType" SG_ 1024 FRZCU_PasgerSeatMovFailCause 0;
BA_ "GenSigSendType" SG_ 1024 FRZCU_ADSLightSts 0;
BA_ "GenSigSendType" SG_ 1024 CSunshadeSts 0;
BA_ "GenSigSendType" SG_ 1024 CSunshadePercentSts 0;
BA_ "GenSigSendType" SG_ 1024 FRZCU_SeatHeatLvlFR2 0;
BA_ "GenSigSendType" SG_ 1024 FRZCU_SeatVentLvlFR2 0;
BA_ "GenSigSendType" SG_ 1024 FRZCU_SeatVentLvlRR2 0;
BA_ "GenSigSendType" SG_ 1024 FRZCU_SeatHeatLvlRR2 0;
BA_ "GenSigSendType" SG_ 1024 FRZCU_ContainerlightSts 0;
BA_ "GenSigSendType" SG_ 1024 FRZCU_FRWinThermalSts 0;
BA_ "GenSigSendType" SG_ 1024 FRZCU_RRWinThermalSts 0;
BA_ "GenSigSendType" SG_ 1024 FRZCU_CSunshadeThermalSts 0;
BA_ "GenSigSendType" SG_ 1182 OBC_InnerDischgVolt 0;
BA_ "GenSigSendType" SG_ 1182 OBC_InnerDischgCurr 0;
BA_ "GenSigSendType" SG_ 1182 OBC_ElectronicLockSts 0;
BA_ "GRC_Sig_ASIL" SG_ 1182 OBC_WorkingMode 2;
BA_ "GenSigSendType" SG_ 1182 OBC_WorkingMode 0;
BA_ "GRC_Sig_ASIL" SG_ 1182 OBC_OutDischgCurr 2;
BA_ "GenSigSendType" SG_ 1182 OBC_OutDischgCurr 0;
BA_ "GRC_Sig_ASIL" SG_ 1182 OBC_OutDischgVolt 2;
BA_ "GenSigSendType" SG_ 1182 OBC_OutDischgVolt 0;
BA_ "GenSigSendType" SG_ 290 EPS_1_CRC 0;
BA_ "E2EDataId" SG_ 290 EPS_1_CRC 46;
BA_ "E2EProfile" SG_ 290 EPS_1_CRC "P01";
BA_ "E2EDataLength" SG_ 290 EPS_1_CRC 64;
BA_ "GenSigSendType" SG_ 290 EPS_1_RollgCntr 0;
BA_ "E2EDataId" SG_ 290 EPS_1_RollgCntr 46;
BA_ "E2EProfile" SG_ 290 EPS_1_RollgCntr "P01";
BA_ "E2EDataLength" SG_ 290 EPS_1_RollgCntr 64;
BA_ "GRC_Sig_ASIL" SG_ 290 EPSFailSts 3;
BA_ "GenSigSendType" SG_ 290 EPSFailSts 0;
BA_ "E2EDataId" SG_ 290 EPSFailSts 46;
BA_ "E2EProfile" SG_ 290 EPSFailSts "P01";
BA_ "E2EDataLength" SG_ 290 EPSFailSts 64;
BA_ "GenSigSendType" SG_ 290 EPSSteeringAngleCalibrationSts 0;
BA_ "E2EDataId" SG_ 290 EPSSteeringAngleCalibrationSts 46;
BA_ "E2EProfile" SG_ 290 EPSSteeringAngleCalibrationSts "P01";
BA_ "E2EDataLength" SG_ 290 EPSSteeringAngleCalibrationSts 64;
BA_ "GenSigSendType" SG_ 290 EPS_EOTLearning_Sts 0;
BA_ "E2EDataId" SG_ 290 EPS_EOTLearning_Sts 46;
BA_ "E2EProfile" SG_ 290 EPS_EOTLearning_Sts "P01";
BA_ "E2EDataLength" SG_ 290 EPS_EOTLearning_Sts 64;
BA_ "GenSigSendType" SG_ 513 MFSL_UP_SW 0;
BA_ "GenSigSendType" SG_ 513 MFSL_DW_SW 0;
BA_ "GenSigSendType" SG_ 513 MFSL_Left_SW 0;
BA_ "GenSigSendType" SG_ 513 MFSL_Right_SW 0;
BA_ "GenSigSendType" SG_ 513 MFSL_OK_SW 0;
BA_ "GenSigSendType" SG_ 513 MFSL_AVM_SW 0;
BA_ "GenSigSendType" SG_ 513 MFSL_Customize 0;
BA_ "GenSigSendType" SG_ 513 MFSL_APA_SW 0;
BA_ "GenSigSendType" SG_ 1152 TBOX_PetmodeSetTemperature 5;
BA_ "GenSigInvalidValue" SG_ 1152 TBOX_PetmodeSetTemperature 31;
BA_ "GenSigStartValue" SG_ 1152 TBOX_PetmodeSetTemperature 31;
BA_ "GenSigSendType" SG_ 1208 PPMID_1_PPMICounter 0;
BA_ "GenSigSendType" SG_ 1208 PPMID_1_PPMISt 0;
BA_ "GenSigStartValue" SG_ 1208 PPMID_1_PPMISt 1;
BA_ "GenSigSendType" SG_ 1208 PPMID_1_HWSts 0;
BA_ "GenSigStartValue" SG_ 1208 PPMID_1_HWSts 1;
BA_ "GenSigSendType" SG_ 1208 PPMID_1_BSRBPASts 0;
BA_ "GenSigStartValue" SG_ 1208 PPMID_1_BSRBPASts 1;
BA_ "GenSigSendType" SG_ 794 ADS_3_ICAStatus 0;
BA_ "GenSigSendType" SG_ 794 ADS_3_ICATextinfo 0;
BA_ "GenSigSendType" SG_ 794 ADS_3_ACCSts 0;
BA_ "GenSigSendType" SG_ 794 ADS_3_DriverHandsoffWarning 0;
BA_ "GenSigSendType" SG_ 794 ADS_3_LKSMod 0;
BA_ "GenSigSendType" SG_ 794 ADS_3_LKSSts 0;
BA_ "GenSigSendType" SG_ 794 ADS_3_ELKSts 0;
BA_ "GenSigSendType" SG_ 794 ADS_3_LKSLeftTrackingSt 0;
BA_ "GenSigSendType" SG_ 794 ADS_3_LKSRightTrackingSt 0;
BA_ "GenSigSendType" SG_ 794 ADS_3_ELKLeftActiveSt 0;
BA_ "GenSigSendType" SG_ 794 ADS_3_ELKRightActiveSt 0;
BA_ "GenSigSendType" SG_ 1155 ASU_3_horizontalSts 0;
BA_ "GenSigSendType" SG_ 1155 ASU_3_horizontalmodeFb 0;
BA_ "GenSigSendType" SG_ 1164 OBC_DischgSts 0;
BA_ "GenSigSendType" SG_ 789 ATCM_ASU_LowerSet 5;
BA_ "GenSigSendType" SG_ 789 ATCM_ASU_LiftSet 5;
BA_ "GenSigSendType" SG_ 789 ATCM_DriveModeSw 5;
BA_ "GenSigSendType" SG_ 789 ATCM_XModeSw 5;
BA_ "GenSigSendType" SG_ 789 ATCM_SwitchUTurnModeSet 5;
BA_ "GenSigSendType" SG_ 1214 BNCM_16_CRC1 1;
BA_ "GenSigSendType" SG_ 1214 BNCM_16_RollgCntr1 1;
BA_ "GenSigSendType" SG_ 1214 BNCM_16_Resd1 1;
BA_ "GenSigSendType" SG_ 1214 BNCM_16_CMD 1;
BA_ "GenSigSendType" SG_ 1214 BNCM_16_PDU1 1;
BA_ "GenSigSendType" SG_ 1214 BNCM_16_PDU2 1;
BA_ "GenSigSendType" SG_ 1214 BNCM_16_PDU3 1;
BA_ "GenSigSendType" SG_ 1214 BNCM_16_PDU4 1;
BA_ "GenSigSendType" SG_ 1095 RLCR_1_CRC1 0;
BA_ "E2EDataId" SG_ 1095 RLCR_1_CRC1 68;
BA_ "E2EProfile" SG_ 1095 RLCR_1_CRC1 "P01";
BA_ "E2EDataLength" SG_ 1095 RLCR_1_CRC1 64;
BA_ "GenSigSendType" SG_ 1095 RLCR_1_RollgCntr1 0;
BA_ "E2EDataId" SG_ 1095 RLCR_1_RollgCntr1 68;
BA_ "E2EProfile" SG_ 1095 RLCR_1_RollgCntr1 "P01";
BA_ "E2EDataLength" SG_ 1095 RLCR_1_RollgCntr1 64;
BA_ "GenSigSendType" SG_ 1095 RLCR_1_Resd1 0;
BA_ "E2EDataId" SG_ 1095 RLCR_1_Resd1 68;
BA_ "E2EProfile" SG_ 1095 RLCR_1_Resd1 "P01";
BA_ "E2EDataLength" SG_ 1095 RLCR_1_Resd1 64;
BA_ "GenSigSendType" SG_ 1095 RLCR_1_SysSt 0;
BA_ "E2EDataId" SG_ 1095 RLCR_1_SysSt 68;
BA_ "E2EProfile" SG_ 1095 RLCR_1_SysSt "P01";
BA_ "E2EDataLength" SG_ 1095 RLCR_1_SysSt 64;
BA_ "GenSigSendType" SG_ 1095 RLCR_1_BlkSts 0;
BA_ "E2EDataId" SG_ 1095 RLCR_1_BlkSts 68;
BA_ "E2EProfile" SG_ 1095 RLCR_1_BlkSts "P01";
BA_ "E2EDataLength" SG_ 1095 RLCR_1_BlkSts 64;
BA_ "GenSigSendType" SG_ 1095 RLCR_1_BSDWarn 0;
BA_ "E2EDataId" SG_ 1095 RLCR_1_BSDWarn 68;
BA_ "E2EProfile" SG_ 1095 RLCR_1_BSDWarn "P01";
BA_ "E2EDataLength" SG_ 1095 RLCR_1_BSDWarn 64;
BA_ "GenSigSendType" SG_ 1095 RLCR_1_DOWWarn 0;
BA_ "E2EDataId" SG_ 1095 RLCR_1_DOWWarn 68;
BA_ "E2EProfile" SG_ 1095 RLCR_1_DOWWarn "P01";
BA_ "E2EDataLength" SG_ 1095 RLCR_1_DOWWarn 64;
BA_ "GenSigSendType" SG_ 1095 RLCR_1_DowLock 0;
BA_ "E2EDataId" SG_ 1095 RLCR_1_DowLock 68;
BA_ "E2EProfile" SG_ 1095 RLCR_1_DowLock "P01";
BA_ "E2EDataLength" SG_ 1095 RLCR_1_DowLock 64;
BA_ "GenSigSendType" SG_ 1095 RLCR_1_ELK_Collision_flag 0;
BA_ "E2EDataId" SG_ 1095 RLCR_1_ELK_Collision_flag 68;
BA_ "E2EProfile" SG_ 1095 RLCR_1_ELK_Collision_flag "P01";
BA_ "E2EDataLength" SG_ 1095 RLCR_1_ELK_Collision_flag 64;
BA_ "GenSigSendType" SG_ 1095 RLCR_1_ELK_CollisionFlagValid 0;
BA_ "E2EDataId" SG_ 1095 RLCR_1_ELK_CollisionFlagValid 68;
BA_ "E2EProfile" SG_ 1095 RLCR_1_ELK_CollisionFlagValid "P01";
BA_ "E2EDataLength" SG_ 1095 RLCR_1_ELK_CollisionFlagValid 64;
BA_ "GenSigSendType" SG_ 1267 RRCR_1_CRC1 0;
BA_ "E2EDataId" SG_ 1267 RRCR_1_CRC1 70;
BA_ "E2EProfile" SG_ 1267 RRCR_1_CRC1 "P01";
BA_ "E2EDataLength" SG_ 1267 RRCR_1_CRC1 64;
BA_ "GenSigSendType" SG_ 1267 RRCR_1_RollgCntr1 0;
BA_ "E2EDataId" SG_ 1267 RRCR_1_RollgCntr1 70;
BA_ "E2EProfile" SG_ 1267 RRCR_1_RollgCntr1 "P01";
BA_ "E2EDataLength" SG_ 1267 RRCR_1_RollgCntr1 64;
BA_ "GenSigSendType" SG_ 1267 RRCR_1_Resd1 0;
BA_ "E2EDataId" SG_ 1267 RRCR_1_Resd1 70;
BA_ "E2EProfile" SG_ 1267 RRCR_1_Resd1 "P01";
BA_ "E2EDataLength" SG_ 1267 RRCR_1_Resd1 64;
BA_ "GenSigSendType" SG_ 1267 RRCR_1_SysSt 0;
BA_ "E2EDataId" SG_ 1267 RRCR_1_SysSt 70;
BA_ "E2EProfile" SG_ 1267 RRCR_1_SysSt "P01";
BA_ "E2EDataLength" SG_ 1267 RRCR_1_SysSt 64;
BA_ "GenSigSendType" SG_ 1267 RRCR_1_BlkSts 0;
BA_ "E2EDataId" SG_ 1267 RRCR_1_BlkSts 70;
BA_ "E2EProfile" SG_ 1267 RRCR_1_BlkSts "P01";
BA_ "E2EDataLength" SG_ 1267 RRCR_1_BlkSts 64;
BA_ "GenSigSendType" SG_ 1267 RRCR_1_BSDWarn 0;
BA_ "E2EDataId" SG_ 1267 RRCR_1_BSDWarn 70;
BA_ "E2EProfile" SG_ 1267 RRCR_1_BSDWarn "P01";
BA_ "E2EDataLength" SG_ 1267 RRCR_1_BSDWarn 64;
BA_ "GenSigSendType" SG_ 1267 RRCR_1_DOWWarn 0;
BA_ "E2EDataId" SG_ 1267 RRCR_1_DOWWarn 70;
BA_ "E2EProfile" SG_ 1267 RRCR_1_DOWWarn "P01";
BA_ "E2EDataLength" SG_ 1267 RRCR_1_DOWWarn 64;
BA_ "GenSigSendType" SG_ 1267 RRCR_1_DowLock 0;
BA_ "E2EDataId" SG_ 1267 RRCR_1_DowLock 70;
BA_ "E2EProfile" SG_ 1267 RRCR_1_DowLock "P01";
BA_ "E2EDataLength" SG_ 1267 RRCR_1_DowLock 64;
BA_ "GenSigSendType" SG_ 1267 RRCR_1_ELK_Collision_flag 0;
BA_ "E2EDataId" SG_ 1267 RRCR_1_ELK_Collision_flag 70;
BA_ "E2EProfile" SG_ 1267 RRCR_1_ELK_Collision_flag "P01";
BA_ "E2EDataLength" SG_ 1267 RRCR_1_ELK_Collision_flag 64;
BA_ "GenSigSendType" SG_ 1267 RRCR_1_ELK_CollisionFlagValid 0;
BA_ "E2EDataId" SG_ 1267 RRCR_1_ELK_CollisionFlagValid 70;
BA_ "E2EProfile" SG_ 1267 RRCR_1_ELK_CollisionFlagValid "P01";
BA_ "E2EDataLength" SG_ 1267 RRCR_1_ELK_CollisionFlagValid 64;
BA_ "GenSigSendType" SG_ 788 ADS_2_AEBStatus 0;
BA_ "GenSigSendType" SG_ 788 ADS_2_FCWStatus 0;
BA_ "GenSigSendType" SG_ 788 FCM_2_IHCfunctionSts 0;
BA_ "GRC_Sig_ASIL" SG_ 571 LHTurnlightSts 3;
BA_ "GenSigSendType" SG_ 571 LHTurnlightSts 0;
BA_ "GRC_Sig_ASIL" SG_ 571 RHTurnlightSts 3;
BA_ "GenSigSendType" SG_ 571 RHTurnlightSts 0;
BA_ "GRC_Sig_ASIL" SG_ 571 LHFdoorSts 2;
BA_ "GenSigSendType" SG_ 571 LHFdoorSts 0;
BA_ "GRC_Sig_ASIL" SG_ 571 LHFDoorLockSts 2;
BA_ "GenSigSendType" SG_ 571 LHFDoorLockSts 0;
BA_ "GenSigStartValue" SG_ 571 LHFDoorLockSts 3;
BA_ "GenSigSendType" SG_ 571 LHTurnSW 0;
BA_ "GenSigSendType" SG_ 571 RHTurnSW 0;
BA_ "GenSigSendType" SG_ 571 HazardLightSW 0;
BA_ "GRC_Sig_ASIL" SG_ 571 LHFSeatBeltSW 2;
BA_ "GenSigSendType" SG_ 571 LHFSeatBeltSW 0;
BA_ "GRC_Sig_ASIL" SG_ 571 DirectionIndLeft 3;
BA_ "GenSigSendType" SG_ 571 DirectionIndLeft 0;
BA_ "GRC_Sig_ASIL" SG_ 571 DirectionIndRight 3;
BA_ "GenSigSendType" SG_ 571 DirectionIndRight 0;
BA_ "GRC_Sig_ASIL" SG_ 699 LHRdoorSts 2;
BA_ "GenSigSendType" SG_ 699 LHRdoorSts 0;
BA_ "GenSigSendType" SG_ 787 ChrgHoodSts 0;
BA_ "GenSigSendType" SG_ 787 FRZCU_FRSitPosnSts 0;
BA_ "GenSigSendType" SG_ 524 New_Signal_20C 0;
BA_ "E2EDataId" SG_ 524 New_Signal_20C 249;
BA_ "E2EProfile" SG_ 524 New_Signal_20C "P01";
BA_ "E2EDataLength" SG_ 524 New_Signal_20C 64;
BA_ "GenSigSendType" SG_ 524 New_Signal_20C_1 0;
BA_ "E2EDataId" SG_ 524 New_Signal_20C_1 249;
BA_ "E2EProfile" SG_ 524 New_Signal_20C_1 "P01";
BA_ "E2EDataLength" SG_ 524 New_Signal_20C_1 64;
BA_ "GenSigSendType" SG_ 524 ADS_6_CRC1 0;
BA_ "E2EDataId" SG_ 524 ADS_6_CRC1 249;
BA_ "E2EProfile" SG_ 524 ADS_6_CRC1 "P01";
BA_ "E2EDataLength" SG_ 524 ADS_6_CRC1 64;
BA_ "GenSigSendType" SG_ 524 ADS_6_RollgCntr1 0;
BA_ "E2EDataId" SG_ 524 ADS_6_RollgCntr1 249;
BA_ "E2EProfile" SG_ 524 ADS_6_RollgCntr1 "P01";
BA_ "E2EDataLength" SG_ 524 ADS_6_RollgCntr1 64;
BA_ "GenSigSendType" SG_ 524 ADS_6_Resd1 0;
BA_ "E2EDataId" SG_ 524 ADS_6_Resd1 249;
BA_ "E2EProfile" SG_ 524 ADS_6_Resd1 "P01";
BA_ "E2EDataLength" SG_ 524 ADS_6_Resd1 64;
BA_ "GenSigSendType" SG_ 524 ADS_6_AVM_FuncSts 0;
BA_ "E2EDataId" SG_ 524 ADS_6_AVM_FuncSts 249;
BA_ "E2EProfile" SG_ 524 ADS_6_AVM_FuncSts "P01";
BA_ "E2EDataLength" SG_ 524 ADS_6_AVM_FuncSts 64;
BA_ "GenSigSendType" SG_ 524 ADS_6_AVM_ButtonClick 0;
BA_ "E2EDataId" SG_ 524 ADS_6_AVM_ButtonClick 249;
BA_ "E2EProfile" SG_ 524 ADS_6_AVM_ButtonClick "P01";
BA_ "E2EDataLength" SG_ 524 ADS_6_AVM_ButtonClick 64;
BA_ "GenSigSendType" SG_ 524 ADS_6_Customize_buttonsFB 0;
BA_ "E2EDataId" SG_ 524 ADS_6_Customize_buttonsFB 249;
BA_ "E2EProfile" SG_ 524 ADS_6_Customize_buttonsFB "P01";
BA_ "E2EDataLength" SG_ 524 ADS_6_Customize_buttonsFB 64;
BA_ "GenSigSendType" SG_ 524 ADS_6_PAS_AudioTone 0;
BA_ "E2EDataId" SG_ 524 ADS_6_PAS_AudioTone 249;
BA_ "E2EProfile" SG_ 524 ADS_6_PAS_AudioTone "P01";
BA_ "E2EDataLength" SG_ 524 ADS_6_PAS_AudioTone 64;
BA_ "GenSigSendType" SG_ 572 ONEBOX_7_TAB_HighTemp 0;
BA_ "GenSigSendType" SG_ 572 ONEBOX_7_TAB_Active 0;
BA_ "GenSigSendType" SG_ 572 ONEBOX_7_BSW_Active 0;
BA_ "GenSigSendType" SG_ 572 ONEBOX_7_iCCO_TgtVel 0;
BA_ "GRC_Sig_ASIL" SG_ 1212 VCU_3_G_ActWheelTorqueFA 3;
BA_ "GenSigSendType" SG_ 1212 VCU_3_G_ActWheelTorqueFA 0;
BA_ "GRC_Sig_ASIL" SG_ 1212 VCU_3_G_ActWheelTorqueRA 3;
BA_ "GenSigSendType" SG_ 1212 VCU_3_G_ActWheelTorqueRA 0;
BA_ "GenSigSendType" SG_ 783 ADCC_SysReadySts 0;
BA_ "GenSigSendType" SG_ 1110 IMMO_Chall_ICC 2;
BA_ "GenSigSendType" SG_ 1149 IMMO_Teach_VCC 2;
BA_ "GenSigSendType" SG_ 1037 ADS_RCTAWarn_Left 0;
BA_ "GenSigSendType" SG_ 1037 ADS_RCTAWarn_Rigth 0;
BA_ "GenSigSendType" SG_ 1037 ADS_FCTAWarn_Left 0;
BA_ "GenSigSendType" SG_ 1037 ADS_FCTAWarn_Right 0;
BA_ "GenSigSendType" SG_ 943 Fraxlebearingrate 0;
BA_ "GenSigInvalidValue" SG_ 943 Fraxlebearingrate 255;
BA_ "GenSigSendType" SG_ 943 CSA_3_CRC1 0;
BA_ "GenSigSendType" SG_ 943 CSA_3_RollgCntr1 0;
BA_ "GenSigSendType" SG_ 943 CSA_3_Resd1 0;
BA_ "GenSigSendType" SG_ 943 FlwheelBearing 0;
BA_ "GenSigInvalidValue" SG_ 943 FlwheelBearing 4095;
BA_ "GenSigSendType" SG_ 943 FrwheelBearing 0;
BA_ "GenSigInvalidValue" SG_ 943 FrwheelBearing 4095;
BA_ "GenSigSendType" SG_ 943 BlwheelBearing 0;
BA_ "GenSigInvalidValue" SG_ 943 BlwheelBearing 4095;
BA_ "GenSigSendType" SG_ 943 BrwheelBearing 0;
BA_ "GenSigInvalidValue" SG_ 943 BrwheelBearing 4095;
BA_ "GenSigSendType" SG_ 943 CSA_3_CRC2 0;
BA_ "GenSigSendType" SG_ 943 CSA_3_RollgCntr2 0;
BA_ "GenSigSendType" SG_ 943 VehicleBearing_kg 0;
BA_ "GenSigInvalidValue" SG_ 943 VehicleBearing_kg 4095;
BA_ "GenSigSendType" SG_ 943 VehicleBearing_lb 0;
BA_ "GenSigInvalidValue" SG_ 943 VehicleBearing_lb 4095;
BA_ "GenSigSendType" SG_ 943 GoodsWeight_kg 0;
BA_ "GenSigInvalidValue" SG_ 943 GoodsWeight_kg 4095;
BA_ "GenSigSendType" SG_ 943 Goods_Weight_Ratio 0;
BA_ "GenSigInvalidValue" SG_ 943 Goods_Weight_Ratio 1023;
BA_ "GenSigSendType" SG_ 943 CSA_3_CRC3 0;
BA_ "GenSigSendType" SG_ 943 CSA_3_RollgCntr3 0;
BA_ "GenSigSendType" SG_ 943 CSA_3_Resd3 0;
BA_ "GenSigSendType" SG_ 943 GoodsWeight_lb 0;
BA_ "GenSigInvalidValue" SG_ 943 GoodsWeight_lb 4095;
BA_ "GenSigSendType" SG_ 943 OverWeightValue_kg 0;
BA_ "GenSigInvalidValue" SG_ 943 OverWeightValue_kg 4095;
BA_ "GenSigSendType" SG_ 943 OverWeightValue_lb 0;
BA_ "GenSigInvalidValue" SG_ 943 OverWeightValue_lb 4095;
BA_ "GenSigSendType" SG_ 943 OverWeightRatio 0;
BA_ "GenSigSendType" SG_ 943 OverWeightWarning 0;
BA_ "GenSigSendType" SG_ 943 OverLoadWarnShieldSetFed 0;
BA_ "GenSigSendType" SG_ 1120 RLHS_2_AmbBrightness 0;
BA_ "GenSigInvalidValue" SG_ 1120 RLHS_2_AmbBrightness 4095;
BA_ "GenSigSendType" SG_ 1120 RLHS_LiSwithReason 0;
BA_ "GenSigSendType" SG_ 850 ASU_trekthrough_352h 0;
BA_ "GenSigSendType" SG_ 850 ASU_undergroundmode_352h 0;
BA_ "GenSigSendType" SG_ 850 ASU_inflate_352h 0;
BA_ "GRC_Sig_ASIL" SG_ 850 ASU_6_HMIFailFb_JT 3;
BA_ "GenSigSendType" SG_ 850 ASU_6_HMIFailFb_JT 0;
BA_ "GenSigSendType" SG_ 1199 TCM_1_TrailerSts 0;
BA_ "GenSigSendType" SG_ 770 ADS_RPAOnlineOrNot_302h 0;
BA_ "GenSigSendType" SG_ 770 ADS_RpaParkAuthn_302h 0;
BA_ "GenSigSendType" SG_ 770 ADS_SeldParkID_302h 0;
BA_ "GenSigInvalidValue" SG_ 770 ADS_SeldParkID_302h 11;
BA_ "GenSigSendType" SG_ 770 ADS_VehParkMod_302h 0;
BA_ "GenSigInvalidValue" SG_ 770 ADS_VehParkMod_302h 3;
BA_ "GenSigSendType" SG_ 770 ADS_RemParkPatSel_302h 0;
BA_ "GenSigSendType" SG_ 770 ADS_ParkDirCfm_302h 0;
BA_ "GenSigInvalidValue" SG_ 770 ADS_ParkDirCfm_302h 8;
BA_ "GenSigSendType" SG_ 770 ADS_ParkProgs_302h 0;
BA_ "GenSigSendType" SG_ 770 ADS_ParkRmngDst_302h 0;
BA_ "GenSigSendType" SG_ 770 ADS_ObstclDst_302h 0;
BA_ "GenSigSendType" SG_ 770 ADS_AutEve_302h 0;
BA_ "GenSigSendType" SG_ 770 ADS_parkInterruptDuration_302h 0;
BA_ "GenSigSendType" SG_ 770 APA_ResuAvl_302h 0;
BA_ "GenSigSendType" SG_ 770 ADS_ParkStMac_302h 0;
BA_ "GenSigSendType" SG_ 770 ADS_ParkOutDir_ParaLe_302h 0;
BA_ "GenSigSendType" SG_ 770 ADS_ParkOutDir_ParaRi_302h 0;
BA_ "GenSigSendType" SG_ 770 ADS_ParkOutDir_PerpFwd_302h 0;
BA_ "GenSigSendType" SG_ 770 ADS_ParkOutDir_PerpLeFwd_302h 0;
BA_ "GenSigSendType" SG_ 770 ADS_ParkOutDir_PerpRiFwd_302h 0;
BA_ "GenSigSendType" SG_ 770 ADS_ParkOutDir_PerpLeBack_302h 0;
BA_ "GenSigSendType" SG_ 770 ADS_ParkOutDir_PerpRiBack_302h 0;
BA_ "GenSigSendType" SG_ 770 ADS_ParkOutDir_PerpBack_302h 0;
BA_ "GenSigSendType" SG_ 770 APA_RPAFctUnavlMsg_1_302h 0;
BA_ "GenSigSendType" SG_ 770 APA_RPAFctUnavlMsg_2_302h 0;
BA_ "GenSigSendType" SG_ 770 APA_RPAFctUnavlMsg_3_302h 0;
BA_ "GenSigSendType" SG_ 770 APA_RPAFctUnavlMsg_4_302h 0;
BA_ "GenSigSendType" SG_ 770 APA_RPAFctUnavlMsg_5_302h 0;
BA_ "GenSigSendType" SG_ 770 APA_RPAFctUnavlMsg_6_302h 0;
BA_ "GenSigSendType" SG_ 770 APA_RPAFctUnavlMsg_7_302h 0;
BA_ "GenSigSendType" SG_ 770 APA_RPAFctUnavlMsg_8_302h 0;
BA_ "GenSigSendType" SG_ 770 APA_RPAFctUnavlMsg_9_302h 0;
BA_ "GenSigSendType" SG_ 770 APA_RPAFctUnavlMsg_10_302h 0;
BA_ "GenSigSendType" SG_ 770 APA_RPAFctUnavlMsg_11_302h 0;
BA_ "GenSigSendType" SG_ 770 APA_RPAFctUnavlMsg_12_302h 0;
BA_ "GenSigSendType" SG_ 770 APA_RPAFctUnavlMsg_13_302h 0;
BA_ "GenSigSendType" SG_ 770 APA_RPAFctUnavlMsg_14_302h 0;
BA_ "GenSigSendType" SG_ 770 APA_RPAFctUnavlMsg_15_302h 0;
BA_ "GenSigSendType" SG_ 770 APA_RPAFctUnavlMsg_16_302h 0;
BA_ "GenSigSendType" SG_ 770 APA_RPAFctUnavlMsg_17_302h 0;
BA_ "GenSigSendType" SG_ 770 APA_RPAFctUnavlMsg_18_302h 0;
BA_ "GenSigSendType" SG_ 770 APA_RPAFctUnavlMsg_19_302h 0;
BA_ "GenSigSendType" SG_ 770 APA_RPAFctUnavlMsg_20_302h 0;
BA_ "GenSigSendType" SG_ 770 APA_RPAFctUnavlMsg_21_302h 0;
BA_ "GenSigSendType" SG_ 770 APA_RPAFctUnavlMsg_22_302h 0;
BA_ "GenSigSendType" SG_ 770 APA_RPAFctUnavlMsg_23_302h 0;
BA_ "GenSigSendType" SG_ 770 APA_RPAFctUnavlMsg_24_302h 0;
BA_ "GenSigSendType" SG_ 770 APA_RPAFctUnavlMsg_25_302h 0;
BA_ "GenSigSendType" SG_ 770 APA_RPACnclMsg_1_302h 0;
BA_ "GenSigSendType" SG_ 770 APA_RPACnclMsg_2_302h 0;
BA_ "GenSigSendType" SG_ 770 APA_RPACnclMsg_3 0;
BA_ "GenSigSendType" SG_ 770 APA_RPACnclMsg_4_302h 0;
BA_ "GenSigSendType" SG_ 770 APA_RPACnclMsg_5_302h 0;
BA_ "GenSigSendType" SG_ 770 APA_RPACnclMsg_6_302h 0;
BA_ "GenSigSendType" SG_ 770 APA_RPACnclMsg_7_302h 0;
BA_ "GenSigSendType" SG_ 770 APA_RPACnclMsg_8_302h 0;
BA_ "GenSigSendType" SG_ 770 APA_RPACnclMsg_9_302h 0;
BA_ "GenSigSendType" SG_ 770 APA_RPACnclMsg_10_302h 0;
BA_ "GenSigSendType" SG_ 770 APA_RPACnclMsg_11_302h 0;
BA_ "GenSigSendType" SG_ 770 APA_RPACnclMsg_12_302h 0;
BA_ "GenSigSendType" SG_ 770 APA_RPACnclMsg_13_302h 0;
BA_ "GenSigSendType" SG_ 770 APA_RPACnclMsg_14_302h 0;
BA_ "GenSigSendType" SG_ 770 APA_RPACnclMsg_15_302h 0;
BA_ "GenSigSendType" SG_ 770 APA_RPACnclMsg_16_302h 0;
BA_ "GenSigSendType" SG_ 770 APA_RPACnclMsg_17_302h 0;
BA_ "GenSigSendType" SG_ 770 APA_RPACnclMsg_18_302h 0;
BA_ "GenSigSendType" SG_ 770 APA_RPACnclMsg_19_302h 0;
BA_ "GenSigSendType" SG_ 770 APA_RPACnclMsg_20_302h 0;
BA_ "GenSigSendType" SG_ 770 APA_RPAPauseMsg_1_302h 0;
BA_ "GenSigSendType" SG_ 770 APA_RPAPauseMsg_2_302h 0;
BA_ "GenSigSendType" SG_ 770 APA_RPAPauseMsg_3_302h 0;
BA_ "GenSigSendType" SG_ 770 APA_RPAPauseMsg_4_302h 0;
BA_ "GenSigSendType" SG_ 770 APA_RPAPauseMsg_5_302h 0;
BA_ "GenSigSendType" SG_ 770 APA_RPAPauseMsg_6_302h 0;
BA_ "GenSigSendType" SG_ 770 APA_RPAPauseMsg_7_302h 0;
BA_ "GenSigSendType" SG_ 770 APA_RPAPauseMsg_8_302h 0;
BA_ "GenSigSendType" SG_ 770 APA_RPAPauseMsg_9_302h 0;
BA_ "GenSigSendType" SG_ 770 APA_RPAPauseMsg_10_302h 0;
BA_ "GenSigSendType" SG_ 770 ADS_ParkPosn1_ID_302h 0;
BA_ "GenSigSendType" SG_ 770 ADS_MnvrOrintChng1_302h 0;
BA_ "GenSigSendType" SG_ 770 ADS_MnvrOrintChng2_302h 0;
BA_ "GenSigSendType" SG_ 770 ADS_ParkRelPos1_x1_302h 0;
BA_ "GenSigSendType" SG_ 770 ADS_ParkRelPos1_y1_302h 0;
BA_ "GenSigSendType" SG_ 770 ADS_ParkRelPos1_x2_302h 0;
BA_ "GenSigSendType" SG_ 770 ADS_ParkRelPos1_y2_302h 0;
BA_ "GenSigSendType" SG_ 770 ADS_ParkRelPos1_x3_302h 0;
BA_ "GenSigSendType" SG_ 770 ADS_TarParkSt_Posn1_302h 0;
BA_ "GenSigSendType" SG_ 770 ADS_ParkChkSrc_Posn1_302h 0;
BA_ "GenSigSendType" SG_ 770 ADS_VdcActvSts_302h 0;
BA_ "GenSigSendType" SG_ 770 ADS_TcsActvSts_302h 0;
BA_ "GenSigSendType" SG_ 770 ADS_ParkRelPos1_y3_302h 0;
BA_ "GenSigSendType" SG_ 770 ADS_ParkRelPos1_x4_302h 0;
BA_ "GenSigSendType" SG_ 770 ADS_ParkRelPos1_y4_302h 0;
BA_ "GenSigSendType" SG_ 770 ADS_ParkPosn2_ID_302h 0;
BA_ "GenSigSendType" SG_ 770 ADS_ParkRelPos2_x1_302h 0;
BA_ "GenSigSendType" SG_ 770 ADS_ParkRelPos2_y1_302h 0;
BA_ "GenSigSendType" SG_ 770 ADS_ParkRelPos2_x2_302h 0;
BA_ "GenSigSendType" SG_ 770 ADS_ParkRelPos2_y2_302h 0;
BA_ "GenSigSendType" SG_ 770 ADS_ParkRelPos2_x3_302h 0;
BA_ "GenSigSendType" SG_ 770 ADS_TarParkSt_Posn2_302h 0;
BA_ "GenSigSendType" SG_ 770 ADS_ParkChkSrc_Posn2_302h 0;
BA_ "GenSigSendType" SG_ 770 ADS_ParkRelPos2_y3_302h 0;
BA_ "GenSigSendType" SG_ 770 ADS_ParkRelPos2_x4_302h 0;
BA_ "GenSigSendType" SG_ 770 ADS_ParkRelPos2_y4_302h 0;
BA_ "GenSigSendType" SG_ 514 ADS_Resd1_202h 0;
BA_ "E2EDataId" SG_ 514 ADS_Resd1_202h 255;
BA_ "E2EProfile" SG_ 514 ADS_Resd1_202h "P01";
BA_ "E2EDataLength" SG_ 514 ADS_Resd1_202h 64;
BA_ "GenSigSendType" SG_ 514 ADS_RollgCntr1_202h 0;
BA_ "E2EDataId" SG_ 514 ADS_RollgCntr1_202h 255;
BA_ "E2EProfile" SG_ 514 ADS_RollgCntr1_202h "P01";
BA_ "E2EDataLength" SG_ 514 ADS_RollgCntr1_202h 64;
BA_ "GenSigSendType" SG_ 514 ADS_CRC1_202h 0;
BA_ "E2EDataId" SG_ 514 ADS_CRC1_202h 255;
BA_ "E2EProfile" SG_ 514 ADS_CRC1_202h "P01";
BA_ "E2EDataLength" SG_ 514 ADS_CRC1_202h 64;
BA_ "GRC_Sig_ASIL" SG_ 514 ADS_AdsFault_202h 3;
BA_ "GenSigSendType" SG_ 514 ADS_AdsFault_202h 0;
BA_ "E2EDataId" SG_ 514 ADS_AdsFault_202h 255;
BA_ "E2EProfile" SG_ 514 ADS_AdsFault_202h "P01";
BA_ "E2EDataLength" SG_ 514 ADS_AdsFault_202h 64;
BA_ "GRC_Sig_ASIL" SG_ 514 ADS_NicaReminderLEDVisual_202h 3;
BA_ "GenSigSendType" SG_ 514 ADS_NicaReminderLEDVisual_202h 0;
BA_ "E2EDataId" SG_ 514 ADS_NicaReminderLEDVisual_202h 255;
BA_ "E2EProfile" SG_ 514 ADS_NicaReminderLEDVisual_202h "P01";
BA_ "E2EDataLength" SG_ 514 ADS_NicaReminderLEDVisual_202h 64;
BA_ "GRC_Sig_ASIL" SG_ 514 ADS_NicaReminderAcoustic_202h 1;
BA_ "GenSigSendType" SG_ 514 ADS_NicaReminderAcoustic_202h 0;
BA_ "E2EDataId" SG_ 514 ADS_NicaReminderAcoustic_202h 255;
BA_ "E2EProfile" SG_ 514 ADS_NicaReminderAcoustic_202h "P01";
BA_ "E2EDataLength" SG_ 514 ADS_NicaReminderAcoustic_202h 64;
BA_ "GRC_Sig_ASIL" SG_ 514 ADS_TakeoverID_202h 1;
BA_ "GenSigSendType" SG_ 514 ADS_TakeoverID_202h 0;
BA_ "E2EDataId" SG_ 514 ADS_TakeoverID_202h 255;
BA_ "E2EProfile" SG_ 514 ADS_TakeoverID_202h "P01";
BA_ "E2EDataLength" SG_ 514 ADS_TakeoverID_202h 64;
BA_ "GRC_Sig_ASIL" SG_ 514 ADS_TakeoverLevel_202h 1;
BA_ "GenSigSendType" SG_ 514 ADS_TakeoverLevel_202h 0;
BA_ "E2EDataId" SG_ 514 ADS_TakeoverLevel_202h 255;
BA_ "E2EProfile" SG_ 514 ADS_TakeoverLevel_202h "P01";
BA_ "E2EDataLength" SG_ 514 ADS_TakeoverLevel_202h 64;
BA_ "GRC_Sig_ASIL" SG_ 514 ADS_TakeoverType_202h 1;
BA_ "GenSigSendType" SG_ 514 ADS_TakeoverType_202h 0;
BA_ "E2EDataId" SG_ 514 ADS_TakeoverType_202h 255;
BA_ "E2EProfile" SG_ 514 ADS_TakeoverType_202h "P01";
BA_ "E2EDataLength" SG_ 514 ADS_TakeoverType_202h 64;
BA_ "GRC_Sig_ASIL" SG_ 514 ADS_TORIDCorrespErrorID_202h 1;
BA_ "GenSigSendType" SG_ 514 ADS_TORIDCorrespErrorID_202h 0;
BA_ "E2EDataId" SG_ 514 ADS_TORIDCorrespErrorID_202h 255;
BA_ "E2EDataLength" SG_ 514 ADS_TORIDCorrespErrorID_202h 64;
BA_ "E2EProfile" SG_ 514 ADS_TORIDCorrespErrorID_202h "P01";
BA_ "GRC_Sig_ASIL" SG_ 514 ADS_TakeoverExtended16bit_202h 1;
BA_ "GenSigSendType" SG_ 514 ADS_TakeoverExtended16bit_202h 0;
BA_ "GRC_Sig_ASIL" SG_ 514 ADS_TakeoverExtended8bit_202h 1;
BA_ "GenSigSendType" SG_ 514 ADS_TakeoverExtended8bit_202h 0;
BA_ "GenSigSendType" SG_ 1041 ADS_RadarWarning0Distance_411h 0;
BA_ "GenSigSendType" SG_ 1041 ADS_RadarWarning1Distance_411h 0;
BA_ "GenSigSendType" SG_ 1041 ADS_RadarWarning2Distance_411h 0;
BA_ "GenSigSendType" SG_ 1041 ADS_RadarWarning3Distance_411h 0;
BA_ "GenSigSendType" SG_ 1041 ADS_RadarWarning4Distance_411h 0;
BA_ "GenSigSendType" SG_ 1041 ADS_RadarWarning5Distance_411h 0;
BA_ "GenSigSendType" SG_ 1041 ADS_RadarWarning6Distance_411h 0;
BA_ "GenSigSendType" SG_ 1041 ADS_RadarWarning7Distance_411h 0;
BA_ "GenSigSendType" SG_ 1041 ADS_RadarWarning8Distance_411h 0;
BA_ "GenSigSendType" SG_ 1041 ADS_RadarWarning9Distance_411h 0;
BA_ "GenSigSendType" SG_ 1041 ADS_RadarWarning10Distance_411h 0;
BA_ "GenSigSendType" SG_ 1041 ADS_RadarWarning11Distance_411h 0;
BA_ "GenSigSendType" SG_ 1041 ADS_RadarWarning12Distance_411h 0;
BA_ "GenSigSendType" SG_ 1041 ADS_RadarWarning13Distance_411h 0;
BA_ "GenSigSendType" SG_ 1041 ADS_RadarWarning14Distance_411h 0;
BA_ "GenSigSendType" SG_ 1041 ADS_RadarWarning15Distance_411h 0;
BA_ "GenSigSendType" SG_ 1041 ADS_RadarWarning0AcLvl_411h 0;
BA_ "GenSigSendType" SG_ 1041 ADS_RadarWarning1AcLvl_411h 0;
BA_ "GenSigSendType" SG_ 1041 ADS_RadarWarning2AcLvl_411h 0;
BA_ "GenSigSendType" SG_ 1041 ADS_RadarWarning3AcLvl_411h 0;
BA_ "GenSigSendType" SG_ 1041 ADS_RadarWarning4AcLvl_411h 0;
BA_ "GenSigSendType" SG_ 1041 ADS_RadarWarning5AcLvl_411h 0;
BA_ "GenSigSendType" SG_ 1041 ADS_RadarWarning6AcLvl_411h 0;
BA_ "GenSigSendType" SG_ 1041 ADS_RadarWarning7AcLvl_411h 0;
BA_ "GenSigSendType" SG_ 1041 ADS_RadarWarning8AcLvl_411h 0;
BA_ "GenSigSendType" SG_ 1041 ADS_RadarWarning9AcLvl_411h 0;
BA_ "GenSigSendType" SG_ 1041 ADS_RadarWarning10AcLvl_411h 0;
BA_ "GenSigSendType" SG_ 1041 ADS_RadarWarning11AcLvl_411h 0;
BA_ "GenSigSendType" SG_ 1041 ADS_RadarWarning12AcLvl_411h 0;
BA_ "GenSigSendType" SG_ 1041 ADS_RadarWarning13AcLvl_411h 0;
BA_ "GenSigSendType" SG_ 1041 ADS_RadarWarning14AcLvl_411h 0;
BA_ "GenSigSendType" SG_ 1041 ADS_RadarWarning15AcLvl_411h 0;
BA_ "GenSigSendType" SG_ 1041 ADC_FuncReq_SentryModWarn_411h 0;
BA_ "GenSigSendType" SG_ 1041 ADC_FuncReq_SentryModDetec_411h 0;
BA_ "GenSigSendType" SG_ 1041 ADC_MdcSentryAlarmMod_411h 0;
BA_ "GRC_Sig_ASIL" SG_ 769 ADS_AccFunctionStatus_301h 1;
BA_ "GenSigSendType" SG_ 769 ADS_AccFunctionStatus_301h 0;
BA_ "GRC_Sig_ASIL" SG_ 769 ADS_LccNcaFunctionStatus_301h 1;
BA_ "GenSigSendType" SG_ 769 ADS_LccNcaFunctionStatus_301h 0;
BA_ "GRC_Sig_ASIL" SG_ 769 ADS_AdsFucntionNotActive_301h 1;
BA_ "GenSigSendType" SG_ 769 ADS_AdsFucntionNotActive_301h 0;
BA_ "GRC_Sig_ASIL" SG_ 769 ADS_AvpFunctionStatus_301h 1;
BA_ "GenSigSendType" SG_ 769 ADS_AvpFunctionStatus_301h 0;
BA_ "GRC_Sig_ASIL" SG_ 769 ADS_SpeedSetByDriver_301h 1;
BA_ "GenSigSendType" SG_ 769 ADS_SpeedSetByDriver_301h 0;
BA_ "GRC_Sig_ASIL" SG_ 769 ADS_SpeedLimitValue_301h 1;
BA_ "GenSigSendType" SG_ 769 ADS_SpeedLimitValue_301h 0;
BA_ "GRC_Sig_ASIL" SG_ 769 ADS_SpeedAutoFollow_301h 1;
BA_ "GenSigSendType" SG_ 769 ADS_SpeedAutoFollow_301h 0;
BA_ "GRC_Sig_ASIL" SG_ 769 ADS_OneTouchSpeedAdjustment_301h 1;
BA_ "GenSigSendType" SG_ 769 ADS_OneTouchSpeedAdjustment_301h 0;
BA_ "GRC_Sig_ASIL" SG_ 769 ADS_CalibState_301h 1;
BA_ "GenSigSendType" SG_ 769 ADS_CalibState_301h 0;
BA_ "GRC_Sig_ASIL" SG_ 769 ADS_HODReminder_301h 1;
BA_ "GenSigSendType" SG_ 769 ADS_HODReminder_301h 0;
BA_ "GRC_Sig_ASIL" SG_ 769 ADS_DMSReminder_301h 1;
BA_ "GenSigSendType" SG_ 769 ADS_DMSReminder_301h 0;
BA_ "GRC_Sig_ASIL" SG_ 769 ADS_FcwWaning_301h 1;
BA_ "GenSigSendType" SG_ 769 ADS_FcwWaning_301h 0;
BA_ "GRC_Sig_ASIL" SG_ 769 ADS_FcwFault_301h 1;
BA_ "GenSigSendType" SG_ 769 ADS_FcwFault_301h 0;
BA_ "GRC_Sig_ASIL" SG_ 769 ADS_AebWaning_301h 1;
BA_ "GenSigSendType" SG_ 769 ADS_AebWaning_301h 0;
BA_ "GRC_Sig_ASIL" SG_ 769 ADS_AebFault_301h 1;
BA_ "GenSigSendType" SG_ 769 ADS_AebFault_301h 0;
BA_ "GRC_Sig_ASIL" SG_ 769 ADS_AebObjType_301h 1;
BA_ "GenSigSendType" SG_ 769 ADS_AebObjType_301h 0;
BA_ "GRC_Sig_ASIL" SG_ 769 ADS_RaebWarning_301h 1;
BA_ "GenSigSendType" SG_ 769 ADS_RaebWarning_301h 0;
BA_ "GRC_Sig_ASIL" SG_ 769 ADS_RaebFault_301h 1;
BA_ "GenSigSendType" SG_ 769 ADS_RaebFault_301h 0;
BA_ "GRC_Sig_ASIL" SG_ 769 ADS_RcwWarning_301h 1;
BA_ "GenSigSendType" SG_ 769 ADS_RcwWarning_301h 0;
BA_ "GRC_Sig_ASIL" SG_ 769 ADS_RcwFault_301h 1;
BA_ "GenSigSendType" SG_ 769 ADS_RcwFault_301h 0;
BA_ "GRC_Sig_ASIL" SG_ 769 ADS_FctaLeftWarning_301h 1;
BA_ "GenSigSendType" SG_ 769 ADS_FctaLeftWarning_301h 0;
BA_ "GRC_Sig_ASIL" SG_ 769 ADS_FctaRightWarning_301h 1;
BA_ "GenSigSendType" SG_ 769 ADS_FctaRightWarning_301h 0;
BA_ "GRC_Sig_ASIL" SG_ 769 ADS_FctbLeftWarning_301h 1;
BA_ "GenSigSendType" SG_ 769 ADS_FctbLeftWarning_301h 0;
BA_ "GRC_Sig_ASIL" SG_ 769 ADS_FctbRightWarning_301h 1;
BA_ "GenSigSendType" SG_ 769 ADS_FctbRightWarning_301h 0;
BA_ "GRC_Sig_ASIL" SG_ 769 ADS_RctaLeftWarning_301h 1;
BA_ "GenSigSendType" SG_ 769 ADS_RctaLeftWarning_301h 0;
BA_ "GRC_Sig_ASIL" SG_ 769 ADS_RctaRightWarning_301h 1;
BA_ "GenSigSendType" SG_ 769 ADS_RctaRightWarning_301h 0;
BA_ "GRC_Sig_ASIL" SG_ 769 ADS_RctaFault_301h 1;
BA_ "GenSigSendType" SG_ 769 ADS_RctaFault_301h 0;
BA_ "GRC_Sig_ASIL" SG_ 769 ADS_RctbLeftWarning_301h 1;
BA_ "GenSigSendType" SG_ 769 ADS_RctbLeftWarning_301h 0;
BA_ "GRC_Sig_ASIL" SG_ 769 ADS_RctbRightWarning_301h 1;
BA_ "GenSigSendType" SG_ 769 ADS_RctbRightWarning_301h 0;
BA_ "GRC_Sig_ASIL" SG_ 769 ADS_LdwWarning_301h 1;
BA_ "GenSigSendType" SG_ 769 ADS_LdwWarning_301h 0;
BA_ "GRC_Sig_ASIL" SG_ 769 ADS_LdwFault_301h 1;
BA_ "GenSigSendType" SG_ 769 ADS_LdwFault_301h 0;
BA_ "GRC_Sig_ASIL" SG_ 769 ADS_LKAWarning_301h 1;
BA_ "GenSigSendType" SG_ 769 ADS_LKAWarning_301h 0;
BA_ "GRC_Sig_ASIL" SG_ 769 ADS_LkaFault_301h 1;
BA_ "GenSigSendType" SG_ 769 ADS_LkaFault_301h 0;
BA_ "GRC_Sig_ASIL" SG_ 769 ADS_LeftMirrWarningCmd_301h 1;
BA_ "GenSigSendType" SG_ 769 ADS_LeftMirrWarningCmd_301h 0;
BA_ "GRC_Sig_ASIL" SG_ 769 ADS_RightMirrWarningCmd_301h 1;
BA_ "GenSigSendType" SG_ 769 ADS_RightMirrWarningCmd_301h 0;
BA_ "GRC_Sig_ASIL" SG_ 769 ADS_BsdFault_301h 1;
BA_ "GenSigSendType" SG_ 769 ADS_BsdFault_301h 0;
BA_ "GRC_Sig_ASIL" SG_ 769 ADS_LeFrntDoorWarningCmd_301h 1;
BA_ "GenSigSendType" SG_ 769 ADS_LeFrntDoorWarningCmd_301h 0;
BA_ "GRC_Sig_ASIL" SG_ 769 ADS_LeReDoorWarningCmd_301h 1;
BA_ "GenSigSendType" SG_ 769 ADS_LeReDoorWarningCmd_301h 0;
BA_ "GRC_Sig_ASIL" SG_ 769 ADS_RiFrntDoorWarningCmd_301h 1;
BA_ "GenSigSendType" SG_ 769 ADS_RiFrntDoorWarningCmd_301h 0;
BA_ "GRC_Sig_ASIL" SG_ 769 ADS_RiReDoorWarningCmd_301h 1;
BA_ "GenSigSendType" SG_ 769 ADS_RiReDoorWarningCmd_301h 0;
BA_ "GRC_Sig_ASIL" SG_ 769 ADS_DowFault_301h 1;
BA_ "GenSigSendType" SG_ 769 ADS_DowFault_301h 0;
BA_ "GRC_Sig_ASIL" SG_ 769 ADS_SpeedLimitWarning_301h 1;
BA_ "GenSigSendType" SG_ 769 ADS_SpeedLimitWarning_301h 0;
BA_ "GRC_Sig_ASIL" SG_ 769 ADS_TsrFault_301h 1;
BA_ "GenSigSendType" SG_ 769 ADS_TsrFault_301h 0;
BA_ "GRC_Sig_ASIL" SG_ 769 ADS_TlaFault_301h 1;
BA_ "GenSigSendType" SG_ 769 ADS_TlaFault_301h 0;
BA_ "GRC_Sig_ASIL" SG_ 769 ADS_ElkaFault_301h 1;
BA_ "GenSigSendType" SG_ 769 ADS_ElkaFault_301h 0;
BA_ "GRC_Sig_ASIL" SG_ 769 ADS_AbsoultwSpeedLimit_301h 1;
BA_ "GenSigSendType" SG_ 769 ADS_AbsoultwSpeedLimit_301h 0;
BA_ "GRC_Sig_ASIL" SG_ 769 ADS_TlaWarning_301h 1;
BA_ "GenSigSendType" SG_ 769 ADS_TlaWarning_301h 0;
BA_ "GRC_Sig_ASIL" SG_ 769 ADS_ElkaWarning_301h 1;
BA_ "GenSigSendType" SG_ 769 ADS_ElkaWarning_301h 0;
BA_ "GenSigSendType" SG_ 1042 New_Signal_412_1 0;
BA_ "E2EDataId" SG_ 1042 New_Signal_412_1 479;
BA_ "E2EProfile" SG_ 1042 New_Signal_412_1 "P01";
BA_ "E2EDataLength" SG_ 1042 New_Signal_412_1 64;
BA_ "GenSigSendType" SG_ 1042 ADS_Resd1_412h 0;
BA_ "E2EDataId" SG_ 1042 ADS_Resd1_412h 479;
BA_ "E2EProfile" SG_ 1042 ADS_Resd1_412h "P01";
BA_ "E2EDataLength" SG_ 1042 ADS_Resd1_412h 64;
BA_ "GenSigSendType" SG_ 1042 ADS_RollgCntr1_412h 0;
BA_ "E2EDataId" SG_ 1042 ADS_RollgCntr1_412h 479;
BA_ "E2EProfile" SG_ 1042 ADS_RollgCntr1_412h "P01";
BA_ "E2EDataLength" SG_ 1042 ADS_RollgCntr1_412h 64;
BA_ "GenSigSendType" SG_ 1042 ADS_CRC1_412h 0;
BA_ "E2EDataId" SG_ 1042 ADS_CRC1_412h 479;
BA_ "E2EProfile" SG_ 1042 ADS_CRC1_412h "P01";
BA_ "E2EDataLength" SG_ 1042 ADS_CRC1_412h 64;
BA_ "GRC_Sig_ASIL" SG_ 1042 ADS_BrkBeamReq_412h 3;
BA_ "GenSigSendType" SG_ 1042 ADS_BrkBeamReq_412h 0;
BA_ "E2EDataId" SG_ 1042 ADS_BrkBeamReq_412h 479;
BA_ "E2EProfile" SG_ 1042 ADS_BrkBeamReq_412h "P01";
BA_ "E2EDataLength" SG_ 1042 ADS_BrkBeamReq_412h 64;
BA_ "GenSigSendType" SG_ 1042 ADS_AutoLightSwCtrl_412h 0;
BA_ "E2EDataId" SG_ 1042 ADS_AutoLightSwCtrl_412h 479;
BA_ "E2EProfile" SG_ 1042 ADS_AutoLightSwCtrl_412h "P01";
BA_ "E2EDataLength" SG_ 1042 ADS_AutoLightSwCtrl_412h 64;
BA_ "GRC_Sig_ASIL" SG_ 1042 ADS_LeFrntDowWarning_412h 1;
BA_ "GenSigSendType" SG_ 1042 ADS_LeFrntDowWarning_412h 0;
BA_ "E2EDataId" SG_ 1042 ADS_LeFrntDowWarning_412h 479;
BA_ "E2EProfile" SG_ 1042 ADS_LeFrntDowWarning_412h "P01";
BA_ "E2EDataLength" SG_ 1042 ADS_LeFrntDowWarning_412h 64;
BA_ "GRC_Sig_ASIL" SG_ 1042 ADS_RiFrntDowWarning_412h 1;
BA_ "GenSigSendType" SG_ 1042 ADS_RiFrntDowWarning_412h 0;
BA_ "E2EDataId" SG_ 1042 ADS_RiFrntDowWarning_412h 479;
BA_ "E2EProfile" SG_ 1042 ADS_RiFrntDowWarning_412h "P01";
BA_ "E2EDataLength" SG_ 1042 ADS_RiFrntDowWarning_412h 64;
BA_ "GRC_Sig_ASIL" SG_ 1042 ADS_LeReDowWarning_412h 1;
BA_ "GenSigSendType" SG_ 1042 ADS_LeReDowWarning_412h 0;
BA_ "E2EDataId" SG_ 1042 ADS_LeReDowWarning_412h 479;
BA_ "E2EProfile" SG_ 1042 ADS_LeReDowWarning_412h "P01";
BA_ "E2EDataLength" SG_ 1042 ADS_LeReDowWarning_412h 64;
BA_ "GRC_Sig_ASIL" SG_ 1042 ADS_RiReDowWarning_412h 1;
BA_ "GenSigSendType" SG_ 1042 ADS_RiReDowWarning_412h 0;
BA_ "E2EDataId" SG_ 1042 ADS_RiReDowWarning_412h 479;
BA_ "E2EProfile" SG_ 1042 ADS_RiReDowWarning_412h "P01";
BA_ "E2EDataLength" SG_ 1042 ADS_RiReDowWarning_412h 64;
BA_ "GRC_Sig_ASIL" SG_ 1042 ADS_LeftMirrWarningCmd_412h 1;
BA_ "GenSigSendType" SG_ 1042 ADS_LeftMirrWarningCmd_412h 0;
BA_ "E2EDataId" SG_ 1042 ADS_LeftMirrWarningCmd_412h 479;
BA_ "E2EProfile" SG_ 1042 ADS_LeftMirrWarningCmd_412h "P01";
BA_ "E2EDataLength" SG_ 1042 ADS_LeftMirrWarningCmd_412h 64;
BA_ "GRC_Sig_ASIL" SG_ 1042 ADS_RightMirrWarningCmd_412h 1;
BA_ "GenSigSendType" SG_ 1042 ADS_RightMirrWarningCmd_412h 0;
BA_ "E2EDataId" SG_ 1042 ADS_RightMirrWarningCmd_412h 479;
BA_ "E2EProfile" SG_ 1042 ADS_RightMirrWarningCmd_412h "P01";
BA_ "E2EDataLength" SG_ 1042 ADS_RightMirrWarningCmd_412h 64;
BA_ "GRC_Sig_ASIL" SG_ 1042 ADS_ReMirrReq_412h 1;
BA_ "GenSigSendType" SG_ 1042 ADS_ReMirrReq_412h 0;
BA_ "E2EDataId" SG_ 1042 ADS_ReMirrReq_412h 479;
BA_ "E2EProfile" SG_ 1042 ADS_ReMirrReq_412h "P01";
BA_ "E2EDataLength" SG_ 1042 ADS_ReMirrReq_412h 64;
BA_ "GRC_Sig_ASIL" SG_ 1042 ADS_DoorLockReq_412h 1;
BA_ "GenSigSendType" SG_ 1042 ADS_DoorLockReq_412h 0;
BA_ "E2EDataId" SG_ 1042 ADS_DoorLockReq_412h 479;
BA_ "E2EProfile" SG_ 1042 ADS_DoorLockReq_412h "P01";
BA_ "E2EDataLength" SG_ 1042 ADS_DoorLockReq_412h 64;
BA_ "GRC_Sig_ASIL" SG_ 1042 ADS_SBeltControl_412h 1;
BA_ "GenSigSendType" SG_ 1042 ADS_SBeltControl_412h 0;
BA_ "E2EDataId" SG_ 1042 ADS_SBeltControl_412h 479;
BA_ "E2EProfile" SG_ 1042 ADS_SBeltControl_412h "P01";
BA_ "E2EDataLength" SG_ 1042 ADS_SBeltControl_412h 64;
BA_ "GRC_Sig_ASIL" SG_ 1042 ADS_WshrReq_412h 1;
BA_ "GenSigSendType" SG_ 1042 ADS_WshrReq_412h 0;
BA_ "E2EDataId" SG_ 1042 ADS_WshrReq_412h 479;
BA_ "E2EProfile" SG_ 1042 ADS_WshrReq_412h "P01";
BA_ "E2EDataLength" SG_ 1042 ADS_WshrReq_412h 64;
BA_ "GenSigSendType" SG_ 1042 ADS_SeatShakeControl_412h 0;
BA_ "E2EDataId" SG_ 1042 ADS_SeatShakeControl_412h 479;
BA_ "E2EProfile" SG_ 1042 ADS_SeatShakeControl_412h "P01";
BA_ "E2EDataLength" SG_ 1042 ADS_SeatShakeControl_412h 64;
BA_ "GRC_Sig_ASIL" SG_ 1042 ADS_FrtWindshildHeatReq_412h 1;
BA_ "GenSigSendType" SG_ 1042 ADS_FrtWindshildHeatReq_412h 0;
BA_ "E2EDataId" SG_ 1042 ADS_FrtWindshildHeatReq_412h 479;
BA_ "E2EProfile" SG_ 1042 ADS_FrtWindshildHeatReq_412h "P01";
BA_ "E2EDataLength" SG_ 1042 ADS_FrtWindshildHeatReq_412h 64;
BA_ "GRC_Sig_ASIL" SG_ 1042 ADS_HornReq_412h 1;
BA_ "GenSigSendType" SG_ 1042 ADS_HornReq_412h 0;
BA_ "E2EDataId" SG_ 1042 ADS_HornReq_412h 479;
BA_ "E2EProfile" SG_ 1042 ADS_HornReq_412h "P01";
BA_ "E2EDataLength" SG_ 1042 ADS_HornReq_412h 64;
BA_ "GRC_Sig_ASIL" SG_ 1042 ADS_LeFmtWinCtrl_412h 1;
BA_ "GenSigSendType" SG_ 1042 ADS_LeFmtWinCtrl_412h 0;
BA_ "E2EDataId" SG_ 1042 ADS_LeFmtWinCtrl_412h 479;
BA_ "E2EProfile" SG_ 1042 ADS_LeFmtWinCtrl_412h "P01";
BA_ "E2EDataLength" SG_ 1042 ADS_LeFmtWinCtrl_412h 64;
BA_ "GRC_Sig_ASIL" SG_ 1042 ADS_RiFmtWinCtrl_412h 1;
BA_ "GenSigSendType" SG_ 1042 ADS_RiFmtWinCtrl_412h 0;
BA_ "E2EDataId" SG_ 1042 ADS_RiFmtWinCtrl_412h 479;
BA_ "E2EProfile" SG_ 1042 ADS_RiFmtWinCtrl_412h "P01";
BA_ "E2EDataLength" SG_ 1042 ADS_RiFmtWinCtrl_412h 64;
BA_ "GRC_Sig_ASIL" SG_ 1042 ADS_LeReWinCtrl_412h 1;
BA_ "GenSigSendType" SG_ 1042 ADS_LeReWinCtrl_412h 0;
BA_ "E2EDataId" SG_ 1042 ADS_LeReWinCtrl_412h 479;
BA_ "E2EProfile" SG_ 1042 ADS_LeReWinCtrl_412h "P01";
BA_ "E2EDataLength" SG_ 1042 ADS_LeReWinCtrl_412h 64;
BA_ "GRC_Sig_ASIL" SG_ 1042 ADS_RiReWinCtrl_412h 1;
BA_ "GenSigSendType" SG_ 1042 ADS_RiReWinCtrl_412h 0;
BA_ "E2EDataId" SG_ 1042 ADS_RiReWinCtrl_412h 479;
BA_ "E2EProfile" SG_ 1042 ADS_RiReWinCtrl_412h "P01";
BA_ "E2EDataLength" SG_ 1042 ADS_RiReWinCtrl_412h 64;
BA_ "GRC_Sig_ASIL" SG_ 1042 ADS_TopWinCtrl_412h 1;
BA_ "GenSigSendType" SG_ 1042 ADS_TopWinCtrl_412h 0;
BA_ "E2EDataId" SG_ 1042 ADS_TopWinCtrl_412h 479;
BA_ "E2EProfile" SG_ 1042 ADS_TopWinCtrl_412h "P01";
BA_ "E2EDataLength" SG_ 1042 ADS_TopWinCtrl_412h 64;
BA_ "GRC_Sig_ASIL" SG_ 1042 ADS_FrontWiperReq_412h 1;
BA_ "GenSigSendType" SG_ 1042 ADS_FrontWiperReq_412h 0;
BA_ "E2EDataId" SG_ 1042 ADS_FrontWiperReq_412h 479;
BA_ "E2EProfile" SG_ 1042 ADS_FrontWiperReq_412h "P01";
BA_ "E2EDataLength" SG_ 1042 ADS_FrontWiperReq_412h 64;
BA_ "GenSigSendType" SG_ 1042 ADS_ChargingPortCmd_412h 0;
BA_ "E2EDataId" SG_ 1042 ADS_ChargingPortCmd_412h 479;
BA_ "E2EProfile" SG_ 1042 ADS_ChargingPortCmd_412h "P01";
BA_ "E2EDataLength" SG_ 1042 ADS_ChargingPortCmd_412h 64;
BA_ "GenSigSendType" SG_ 1042 ADAS_FctSts_412h 0;
BA_ "E2EDataId" SG_ 1042 ADAS_FctSts_412h 479;
BA_ "E2EProfile" SG_ 1042 ADAS_FctSts_412h "P01";
BA_ "E2EDataLength" SG_ 1042 ADAS_FctSts_412h 64;
BA_ "GenSigSendType" SG_ 1042 ADS_MdcCrtSts_412h 0;
BA_ "GenSigInvalidValue" SG_ 1042 ADS_MdcCrtSts_412h 7;
BA_ "E2EDataId" SG_ 1042 ADS_MdcCrtSts_412h 479;
BA_ "E2EProfile" SG_ 1042 ADS_MdcCrtSts_412h "P01";
BA_ "E2EDataLength" SG_ 1042 ADS_MdcCrtSts_412h 64;
BA_ "GenSigSendType" SG_ 1042 ADS_HVCtrlReq_412h 0;
BA_ "GenSigSendType" SG_ 1042 ADS_ThmPostRun_412h 0;
BA_ "GenSigSendType" SG_ 1042 ADS_FlowReq_412h 0;
BA_ "GenSigInvalidValue" SG_ 1042 ADS_FlowReq_412h 15;
BA_ "GenSigSendType" SG_ 1042 ADS_PwrOnOffReq_412h 0;
BA_ "GenSigSendType" SG_ 1042 ADS_hmaOnOffSts_412h 0;
BA_ "GenSigSendType" SG_ 1042 ADS_HMAStatus_412h 0;
BA_ "GenSigSendType" SG_ 1042 ADS_HiBeamReq_412h 0;
BA_ "GRC_Sig_ASIL" SG_ 1046 LBMS_LoWSocFlt 3;
BA_ "GenSigSendType" SG_ 1046 LBMS_LoWSocFlt 0;
BA_ "GRC_Sig_ASIL" SG_ 1046 LBMS_ThermRunawayFlt 3;
BA_ "GenSigSendType" SG_ 1046 LBMS_ThermRunawayFlt 0;
BA_ "GRC_Sig_ASIL" SG_ 1046 LBMS_SysFlt 3;
BA_ "GenSigSendType" SG_ 1046 LBMS_SysFlt 0;
BA_ "GRC_Sig_ASIL" SG_ 1046 LBMS_LowPowerRemind 3;
BA_ "GenSigSendType" SG_ 1046 LBMS_LowPowerRemind 0;
BA_ "GRC_Sig_ASIL" SG_ 1046 LBMS_EndLifeFlt 3;
BA_ "GenSigSendType" SG_ 1046 LBMS_EndLifeFlt 0;
VAL_ 1107 TMS_PM25_Detect 0 "NotActive" 1 "Active" ;
VAL_ 1107 TMS_CCP_FrontAutoACSts 0 "NotActive" 1 "Active" ;
VAL_ 1107 TMS_CCP_ACStatus 0 "NotActive" 1 "Active" ;
VAL_ 1107 TMS_CCP_FrontOFFSts 0 "NotActive" 1 "Active" ;
VAL_ 1107 TMS_CCP_FBlowSpdCtrlSts 0 "No_Request" 1 "Speed_1_Request" 2 "Speed_2_Request" 3 "Speed_3_Request" 4 "Speed_4_Request" 5 "Speed_5_Request" 6 "Speed_6_Request" 7 "Speed_7_Request" 8 "Speed_8_Request" 9 "Speed_9_Request" 10 "Speed_10_Request" 12 "Speed_0_Request" 15 "Invalid" ;
VAL_ 1107 TMS_CCP_RecyMode 0 "no_Request" 1 "internal_Recycle_Request" 2 "external_Recycle_Request" 3 "auto_Recycle_Request" ;
VAL_ 1107 TMS_CCP_FrontDefrostSts 0 "NotActive" 1 "Active" ;
VAL_ 1107 TMS_UVC_WorkingBfReq 0 "No_Request" 1 "Open_Request" 2 "Close_Request" 3 "AUTO" ;
VAL_ 1107 TMS_UVC_LuminanceBfReq 0 "No_Request" 1 "Higher" 2 "Lower" 3 "Reserved" ;
VAL_ 1107 TMS_CCP_ACFastCool 0 "Not_Active" 1 "ON" 2 "OFF" 3 "Not_Used" ;
VAL_ 1107 TMS_CCP_ACFastHeat 0 "Not_Active" 1 "ON" 2 "OFF" 3 "Not_Used" ;
VAL_ 1175 CCP_2_RecyModeReq 0 "no_Request" 1 "internal_Recycle_Request" 2 "external_Recycle_Request" ;
VAL_ 1175 CCP_2_DefrostModeSwitchReq 0 "No_Pressed" 1 "Pressed" ;
VAL_ 1175 CCP_2_RearDefrostSwitchReq 0 "No_Pressed" 1 "Pressed" ;
VAL_ 1175 CCP_2_ACFastHeat 0 "Not_Active" 1 "ON" 2 "OFF" 3 "Not_Used" ;
VAL_ 1175 CCP_2_FrontBlowSpdCtrlSwitchReq 0 "No_Request" 1 "Speed_1_Request" 2 "Speed_2_Request" 3 "Speed_3_Request" 4 "Speed_4_Request" 5 "Speed_5_Request" 6 "Speed_6_Request" 7 "Speed_7_Request" 8 "Speed_8_Request" 9 "Speed_9_Request" 10 "Speed_10_Request" 12 "Speed_0_Request" 15 "Invalid" ;
VAL_ 1175 FRCCP_DeputySetHeatReq 0 "Not_Active" 1 "OFF" 2 "Seat_heating_Level1" 3 "Seat_heating_Level2" 4 "Seat_heating_Level3" ;
VAL_ 1175 FRCCP_DeputySetVentilationReq 0 "Not_Active" 1 "OFF" 2 "Seat_Ventilation_Level1" 3 "Seat_Ventilation_Level2" 4 "Seat_Ventilation_Level3" ;
VAL_ 1175 CCP_2_ACSwitchReq 0 "No_Pressed" 1 "Pressed" ;
VAL_ 1292 CHB_App_Sts 0 "NotActive" 1 "Chb_ON" 2 "Chb_OFF" 3 "reserved" ;
VAL_ 1292 CHB_AppMem_Sts 0 "NotActive" 1 "ChbMem_ON" 2 "ChbMem_OFF" 3 "reserved" ;
VAL_ 1292 CHB_AppDelay_Sts 0 "NotActive" 1 "ChbDelay_ON" 2 "ChbDelay_OFF" 3 "reserved" ;
VAL_ 1292 CHB_AppCoolorheat_Sts 0 "NotActive" 1 "ChbCool_on" 2 "ChbHeat_on" 3 "Close" 4 "ColdDrinkMode" 5 "IceCreamMode" 6 "WarmMilkMode" 7 "WarmDrinkMode" ;
VAL_ 1292 CHB_AppCoolset_Sts 0 "Not_Active" 1 "ChbCoolset_-6" 2 "ChbCoolset_-5" 3 "ChbCoolset_-4" 4 "ChbCoolset_-3" 5 "ChbCoolset_-2" 6 "ChbCoolset_-1" 7 "ChbCoolset_0" 8 "ChbCoolset_1" 9 "ChbCoolset_2" 10 "ChbCoolset_3" 11 "ChbCoolset_4" 12 "ChbCoolset_5" 13 "ChbCoolset_6" 14 "ChbCoolset_-18" 15 "ChbCoolset_-17" 16 "ChbCoolset_-16" 17 "ChbCoolset_-15" 18 "ChbCoolset_-14" 19 "ChbCoolset_-13" 20 "ChbCoolset_-12" 21 "ChbCoolset_-11" 22 "ChbCoolset_-10" 23 "ChbCoolset_-9" 24 "ChbCoolset_-8" 25 "ChbCoolset_-7" 26 "Reserved" 27 "Reserved" 28 "Reserved" 29 "Reserved" 30 "Reserved" 31 "Reserved" ;
VAL_ 1292 CHB_AppHeatset_Sts 0 "Not_Active" 1 "ChbHeatset_35" 2 "ChbHeatset_36" 3 "ChbHeatset_37" 4 "ChbHeatset_38" 5 "ChbHeatset_39" 6 "ChbHeatset_40" 7 "ChbHeatset_41" 8 "ChbHeatset_42" 9 "ChbHeatset_43" 10 "ChbHeatset_44" 11 "ChbHeatset_45" 12 "ChbHeatset_46" 13 "ChbHeatset_47" 14 "ChbHeatset_48" 15 "ChbHeatset_49" 16 "ChbHeatset_50" ;
VAL_ 1292 CHB_AppSterilization_Sts 0 "NotActive" 1 "Chbsterilize_ON" 2 "Chbsterilize_OFF" 3 "Chbsterilize_Stop" ;
VAL_ 1292 CHB_AppItemsLeft_Sts 0 "NotActive" 1 "ChbItemsLeft_ON" 2 "ChbItemsLeft_OFF" 3 "reserved" ;
VAL_ 1292 CHB_AppItemsLeftset_Sts 0 "NotActive" 1 "CHB_ItemsLeftset_ON" 2 "CHB_ItemsLeftset_OFF" 3 "Reserved" ;
VAL_ 1292 CHB_AppChbDoor_Sts 0 "NotActive" 1 "ChbDoor_ON" 2 "ChbDoor_OFF" 3 "reserved" ;
VAL_ 1241 FuelTankLidSystemFailureSts 0 "No failure" 1 "Failure" ;
VAL_ 1241 FuelTankPressureConditionReached 0 "Not Active" 1 "Wait to refuel" 2 "Ready to refuel" 3 "Reserved" ;
VAL_ 49 ACU_2_LateralAcceleration 65535 "Invalid" ;
VAL_ 49 ACU_2_YawRate 65535 "Invalid" ;
VAL_ 49 ACU_2_YawrateSigValidData 0 "Valid" 1 "Reserved" 2 "Invalid" 3 "Initialize" ;
VAL_ 49 ACU_2_LateralAccelerationSigVD 0 "Valid" 1 "Reserved" 2 "Invalid" 3 "Initialize" ;
VAL_ 1024 CSunshadeSts 0 "Not Active" 1 "Open" 2 "Close" 3 "Half_Open" 4 "Opening" 5 "Closing" 6 "Stop" 7 "Error" ;
VAL_ 1024 CSunshadePercentSts 0 "Not Active" 1 "0%" 2 "10%" 3 "20%" 4 "30%" 5 "40%" 6 "50%" 7 "60%" 8 "70%" 9 "80%" 10 "90%" 11 "100%" 12 "reserved" 13 "reserved" 14 "reserved" 15 "reserved" ;
VAL_ 1024 FRZCU_SeatHeatLvlFR2 0 "Not Active" 1 "OFF" 2 "Level1" 3 "Level2" 4 "Level3" 5 "Level4" 6 "Level5" 7 "Level6" 8 "Level7" 9 "Level8" 10 "Level9" ;
VAL_ 1024 FRZCU_SeatVentLvlFR2 0 "Not Active" 1 "OFF" 2 "Level1" 3 "Level2" 4 "Level3" 5 "Level4" 6 "Level5" 7 "Level6" 8 "Level7" 9 "Level8" 10 "Level9" ;
VAL_ 1024 FRZCU_SeatVentLvlRR2 0 "Not Active" 1 "OFF" 2 "Level1" 3 "Level2" 4 "Level3" 5 "Level4" 6 "Level5" 7 "Level6" 8 "Level7" 9 "Level8" 10 "Level9" ;
VAL_ 1024 FRZCU_SeatHeatLvlRR2 0 "Not Active" 1 "OFF" 2 "Level1" 3 "Level2" 4 "Level3" 5 "Level4" 6 "Level5" 7 "Level6" 8 "Level7" 9 "Level8" 10 "Level9" ;
VAL_ 1024 FRZCU_ContainerlightSts 0 "Not Active" 1 "ON" 2 "OFF" 3 "reserved" ;
VAL_ 1024 FRZCU_FRWinThermalSts 0 "Normal" 1 "Thermal protection" ;
VAL_ 1024 FRZCU_RRWinThermalSts 0 "Normal" 1 "Thermal protection" ;
VAL_ 1024 FRZCU_CSunshadeThermalSts 0 "Normal" 1 "Thermal protection" ;
VAL_ 1182 OBC_ElectronicLockSts 0 "Unlock" 1 "Lock" 2 "Lock error" 3 "Unlock error" 4 "Elock error" ;
VAL_ 1182 OBC_WorkingMode 0 "Init" 1 "Standby" 2 "Chg" 3 "Default" 4 "Preheat" 5 "Keepwarm" 6 "V2L" 7 "V2V" 8 "Powerdown" 9 "Afterrun" 10 "Fault" 11 "Reserved" 12 "Reserved" 13 "Reserved" 14 "Reserved" 15 "Reserved" ;
VAL_ 1182 OBC_OutDischgCurr 1023 "Invalid" ;
VAL_ 1182 OBC_OutDischgVolt 8191 "Invalid" ;
VAL_ 290 EPSFailSts 0 "Not present" 1 "Fail present" 2 "Reserved" 3 "Reserved" ;
VAL_ 290 EPSSteeringAngleCalibrationSts 0 "Calibration is fine" 1 "No calibration or no initialization" ;
VAL_ 290 EPS_EOTLearning_Sts 0 "Learnt" 1 "Not Learnt" ;
VAL_ 513 MFSL_UP_SW 0 "Not_action" 1 "Pressed" 2 "Stuck" 3 "invalid" ;
VAL_ 513 MFSL_DW_SW 0 "Not_action" 1 "Pressed" 2 "Stuck" 3 "invalid" ;
VAL_ 513 MFSL_Left_SW 0 "Not_action" 1 "Pressed" 2 "Stuck" 3 "invalid" ;
VAL_ 513 MFSL_Right_SW 0 "Not_action" 1 "Pressed" 2 "Stuck" 3 "invalid" ;
VAL_ 513 MFSL_OK_SW 0 "Not_action" 1 "Pressed" 2 "Stuck" 3 "invalid" ;
VAL_ 513 MFSL_AVM_SW 0 "Not_action" 1 "Pressed" 2 "Stuck" 3 "invalid" ;
VAL_ 513 MFSL_Customize 0 "Not_action" 1 "Pressed" 2 "Stuck" 3 "invalid" ;
VAL_ 513 MFSL_APA_SW 0 "Not_action" 1 "Pressed" 2 "Stuck" 3 "invalid" ;
VAL_ 1208 PPMID_1_PPMICounter 0 "Count not full" 1 "Count is full" ;
VAL_ 1208 PPMID_1_PPMISt 0 "PPMI no error" 1 "PPMI initialization" 2 "PPMI internal error" 3 "External error" 4 "Reserved" 5 "Reserved" 6 "Reserved" 7 "Reserved" ;
VAL_ 1208 PPMID_1_HWSts 0 "Not active" 1 "ON" 2 "OFF" 3 "Reserved" ;
VAL_ 1208 PPMID_1_BSRBPASts 0 "Not active" 1 "ON" 2 "OFF" 3 "Reserved" ;
VAL_ 794 ADS_3_ICAStatus 0 "Off" 1 "Passive" 2 "Standby" 3 "Active" 4 "Failure" 5 "Suspend" 6 "reserved" 7 "reserved" ;
VAL_ 794 ADS_3_ICATextinfo 0 "No dispaly" 1 "TJAICA Activated" 2 "TJAICA Cannot Be Activated" 3 "TJAICA Cancelled" 4 "TJAICA failure" 5 "TJAICA Suspend" 6 "TJAICA resumed" 7 "TJAICA degrade to ACC" 8 "Urgent TOR request" 9 "uncentered" 10 "Too Large curve" 11 "Abnormal tire pressure" 12 "Camera block" 13 "Master switch is off" 14 "reserved" 15 "reserved" ;
VAL_ 794 ADS_3_ACCSts 0 "Off" 1 "Passive" 2 "Standby" 3 "Active_Control" 4 "Brake Only" 5 "Override" 6 "Stand Wait" 7 "failure" 8 "Stand Active" 9 "reserved" 10 "reserved" 11 "reserved" 12 "reserved" 13 "reserved" 14 "reserved" 15 "reserved" ;
VAL_ 794 ADS_3_DriverHandsoffWarning 0 "None" 1 "Warning 1 for stage1" 2 "Warning 2  for stage2" 3 "Warning 3 for stage3(TOR)" 4 "Warning 4 for stage4(Punishment)" 5 "reserved" 6 "reserved" 7 "reserved" ;
VAL_ 794 ADS_3_LKSMod 0 "Off" 1 "Warning" 2 "Warning+intervention" 3 "reserved" ;
VAL_ 794 ADS_3_LKSSts 0 "OFF" 1 "Standby" 2 "Active" 3 "Failure" 4 "Passive" 5 "Reserved" 6 "Blindness(捷途使用)" 7 "Reserved" ;
VAL_ 794 ADS_3_ELKSts 0 "OFF" 1 "Standby" 2 "Active" 3 "Failure" 4 "Passive" 5 "Reserved" 6 "Blindness(捷途使用)" 7 "Reserved" ;
VAL_ 794 ADS_3_LKSLeftTrackingSt 0 "Inactive" 1 "Lane Tracking" 2 "Intervention" 3 "warning" ;
VAL_ 794 ADS_3_LKSRightTrackingSt 0 "Inactive" 1 "Lane Tracking" 2 "Intervention" 3 "warning" ;
VAL_ 794 ADS_3_ELKLeftActiveSt 0 "no warning" 1 "tracking" 2 "intervention" ;
VAL_ 794 ADS_3_ELKRightActiveSt 0 "no warning" 1 "tracking" 2 "intervention" ;
VAL_ 1155 ASU_3_horizontalSts 0 "Not Active" 1 "ON" 2 "OFF" 3 "Not use" ;
VAL_ 1155 ASU_3_horizontalmodeFb 0 "Not Active" 1 "Working" 2 "Complete" 3 "Abort" 4 "Failure" 5 "Reserved" 6 "Reserved" 7 "Reserved" ;
VAL_ 1164 OBC_DischgSts 0 "NoDischarge" 1 "Discharging" 2 "Discharging-Interior" 3 "Discharging_AND_Discharging-Interior" ;
VAL_ 789 ATCM_DriveModeSw 0 "Not Active" 1 "Plus" 2 "Minus" 3 "Reserved" ;
VAL_ 789 ATCM_XModeSw 0 "Not_Active" 1 "ON" 2 "OFF" 3 "Reserved" ;
VAL_ 789 ATCM_SwitchUTurnModeSet 0 "Release" 1 "Press" ;
VAL_ 1095 RLCR_1_SysSt 0 "Off" 1 "On" 2 "Temporary Error" 3 "System Error" ;
VAL_ 1095 RLCR_1_BlkSts 0 "Not Blockage" 1 "Blockage" ;
VAL_ 1095 RLCR_1_BSDWarn 0 "No Warning" 1 "Standard Warning" 2 "Critical Warning" 3 "Not Used" ;
VAL_ 1095 RLCR_1_DOWWarn 0 "No Warning" 1 "Level1 Warning" 2 "Level2 Warning" 3 "Not Used" ;
VAL_ 1095 RLCR_1_DowLock 0 "No Warning" 1 "Dow lock" 2 "Dow unlock" 3 "Not Used" ;
VAL_ 1095 RLCR_1_ELK_Collision_flag 0 "No critical situation of collision" 1 "Critical situation of collision" ;
VAL_ 1095 RLCR_1_ELK_CollisionFlagValid 0 "Not valid" 1 "Valid" ;
VAL_ 1267 RRCR_1_SysSt 0 "Off" 1 "On" 2 "Temporary Error" 3 "System Error" ;
VAL_ 1267 RRCR_1_BlkSts 0 "Not Blockage" 1 "Blockage" ;
VAL_ 1267 RRCR_1_BSDWarn 0 "No Warning" 1 "Standard Warning" 2 "Critical Warning" 3 "Not Used" ;
VAL_ 1267 RRCR_1_DOWWarn 0 "No Warning" 1 "Level1 Warning" 2 "Level2 Warning" 3 "Not Used" ;
VAL_ 1267 RRCR_1_DowLock 0 "No Warning" 1 "Dow lock" 2 "Dow unlock" 3 "Not Used" ;
VAL_ 1267 RRCR_1_ELK_Collision_flag 0 "No critical situation of collision" 1 "Critical situation of collision" ;
VAL_ 1267 RRCR_1_ELK_CollisionFlagValid 0 "Not valid" 1 "Valid" ;
VAL_ 788 ADS_2_AEBStatus 0 "OFF" 1 "ON" 2 "Failure" 3 "available" 4 "active" 5 "pre-fill" 6 "blindness" ;
VAL_ 788 ADS_2_FCWStatus 0 "no request" 1 "level 1(low)" 2 "level 2(middle)" 3 "level 3(high)" 4 "reserved" 5 "reserved" 6 "reserved" 7 "reserved" ;
VAL_ 788 FCM_2_IHCfunctionSts 0 "Off" 1 "Standby" 2 "Active" 3 "Fault" 4 "Reserved" 5 "Reserved" 6 "Reserved" 7 "Reserved" ;
VAL_ 571 LHTurnlightSts 0 "Not Active" 1 "Active" ;
VAL_ 571 RHTurnlightSts 0 "Not Active" 1 "Active" ;
VAL_ 571 LHFdoorSts 0 "Close" 1 "Ajar" 2 "full_open" 3 "Reserved" ;
VAL_ 571 LHFDoorLockSts 0 "Locked" 1 "Unlocked" 2 "Superlocked" 3 "Unknown" ;
VAL_ 571 LHTurnSW 0 "Off" 1 "Active" ;
VAL_ 571 RHTurnSW 0 "Off" 1 "Active" ;
VAL_ 571 HazardLightSW 0 "Close" 1 "Open" ;
VAL_ 571 LHFSeatBeltSW 0 "Not Active" 1 "Active" ;
VAL_ 571 DirectionIndLeft 0 "Close" 1 "Open" ;
VAL_ 571 DirectionIndRight 0 "Close" 1 "Open" ;
VAL_ 699 LHRdoorSts 0 "Close" 1 "Ajar" 2 "full_open" 3 "Reserved" ;
VAL_ 787 ChrgHoodSts 0 "Close" 1 "Open" ;
VAL_ 787 FRZCU_FRSitPosnSts 0 "Not Active" 1 "Location1" 2 "Location2" 3 "Location3" ;
VAL_ 524 ADS_6_AVM_FuncSts 0 "default" 1 "off" 2 "active" 3 "failure" ;
VAL_ 524 ADS_6_AVM_ButtonClick 0 "none" 1 "clicked" ;
VAL_ 524 ADS_6_Customize_buttonsFB 0 "Not Active" 1 "APA" 2 "TJA/ICA/ACC/NOA" 3 "Offroad AutoPilot" 4 "HPA" 5 "Not used" 6 "Not used" 7 "Not used" ;
VAL_ 524 ADS_6_PAS_AudioTone 0 "No Object" 1 "Continous Tone" 2 "Fast Tone" 3 "Medium Tone" 4 "Slow Tone" 5 "Reserved" 6 "Reserved" 7 "Reserved" ;
VAL_ 572 ONEBOX_7_TAB_HighTemp 0 "No Active" 1 "Active" ;
VAL_ 572 ONEBOX_7_TAB_Active 0 "Not Active" 1 "Active" 2 "Stand by" 3 "Failed" ;
VAL_ 572 ONEBOX_7_BSW_Active 0 "Not Active" 1 "Active" 2 "Filed" 3 "Reserved" ;
VAL_ 783 ADCC_SysReadySts 0 "Ready" 1 "not Ready" ;
VAL_ 1037 ADS_RCTAWarn_Left 0 "No Warning" 1 "Warning" ;
VAL_ 1037 ADS_RCTAWarn_Rigth 0 "No Warning" 1 "Warning" ;
VAL_ 1037 ADS_FCTAWarn_Left 0 "No Warning" 1 "Warning" ;
VAL_ 1037 ADS_FCTAWarn_Right 0 "No Warning" 1 "Warning" ;
VAL_ 943 OverWeightRatio 0 "未超载" 1 "超载0-10%" 2 "超载10%~20%" 3 "超载20%~30%" 4 "超载30%`40%" 5 "严重超载" 6 "Reserved" 7 "Reserved" ;
VAL_ 943 OverWeightWarning 0 "No warning" 1 "Warning" ;
VAL_ 943 OverLoadWarnShieldSetFed 0 "Not Active" 1 "ON" 2 "OFF" 3 "Fault" ;
VAL_ 1120 RLHS_2_AmbBrightness 4095 "Invalid" ;
VAL_ 1120 RLHS_LiSwithReason 0 "Darkstart" 1 "Day" 2 "Night" 3 "Tunnul" ;
VAL_ 850 ASU_6_HMIFailFb_JT 0 "Not Active" 1 "SUSP IS lock" 2 "PLG is open" 3 "suspension height disable" 4 "suspension damping disable" 5 "Altitude too high" 6 "reserved" 7 "reserved" 8 "reserved" 9 "reserved" 10 "reserved" 11 "reserved" 12 "reserved" 13 "reserved" 14 "reserved" 15 "reserved" ;
VAL_ 1199 TCM_1_TrailerSts 0 "Disconnect" 1 "Connect" ;
VAL_ 770 ADS_RPAOnlineOrNot_302h 0 "None" 1 "rolling counter" 2 "rolling counter" 3 "rolling counter" 4 "rolling counter" 5 "rolling counter" 6 "rolling counter" 7 "rolling counter" 8 "rolling counter" 9 "rolling counter" 10 "rolling counter" 11 "rolling counter" 12 "rolling counter" 13 "rolling counter" 14 "rolling counter" 15 "rolling counter" 16 "rolling counter" 17 "rolling counter" 18 "rolling counter" 19 "rolling counter" 20 "rolling counter" 21 "rolling counter" 22 "rolling counter" 23 "rolling counter" 24 "rolling counter" 25 "rolling counter" 26 "rolling counter" 27 "rolling counter" 28 "rolling counter" 29 "rolling counter" 30 "rolling counter" 31 "rolling counter" 32 "rolling counter" 33 "rolling counter" 34 "rolling counter" 35 "rolling counter" 36 "rolling counter" 37 "rolling counter" 38 "rolling counter" 39 "rolling counter" 40 "rolling counter" 41 "rolling counter" 42 "rolling counter" 43 "rolling counter" 44 "rolling counter" 45 "rolling counter" 46 "rolling counter" 47 "rolling counter" 48 "rolling counter" 49 "rolling counter" 50 "rolling counter" 51 "rolling counter" 52 "rolling counter" 53 "rolling counter" 54 "rolling counter" 55 "rolling counter" 56 "rolling counter" 57 "rolling counter" 58 "rolling counter" 59 "rolling counter" 60 "rolling counter" 61 "rolling counter" 62 "rolling counter" 63 "rolling counter" 64 "rolling counter" 65 "rolling counter" 66 "rolling counter" 67 "rolling counter" 68 "rolling counter" 69 "rolling counter" 70 "rolling counter" 71 "rolling counter" 72 "rolling counter" 73 "rolling counter" 74 "rolling counter" 75 "rolling counter" 76 "rolling counter" 77 "rolling counter" 78 "rolling counter" 79 "rolling counter" 80 "rolling counter" 81 "rolling counter" 82 "rolling counter" 83 "rolling counter" 84 "rolling counter" 85 "rolling counter" 86 "rolling counter" 87 "rolling counter" 88 "rolling counter" 89 "rolling counter" 90 "rolling counter" 91 "rolling counter" 92 "rolling counter" 93 "rolling counter" 94 "rolling counter" 95 "rolling counter" 96 "rolling counter" 97 "rolling counter" 98 "rolling counter" 99 "rolling counter" 100 "rolling counter" 101 "rolling counter" 102 "rolling counter" 103 "rolling counter" 104 "rolling counter" 105 "rolling counter" 106 "rolling counter" 107 "rolling counter" 108 "rolling counter" 109 "rolling counter" 110 "rolling counter" 111 "rolling counter" 112 "rolling counter" 113 "rolling counter" 114 "rolling counter" 115 "rolling counter" 116 "rolling counter" 117 "rolling counter" 118 "rolling counter" 119 "rolling counter" 120 "rolling counter" 121 "rolling counter" 122 "rolling counter" 123 "rolling counter" 124 "rolling counter" 125 "rolling counter" 126 "rolling counter" 127 "rolling counter" 128 "rolling counter" 129 "rolling counter" 130 "rolling counter" 131 "rolling counter" 132 "rolling counter" 133 "rolling counter" 134 "rolling counter" 135 "rolling counter" 136 "rolling counter" 137 "rolling counter" 138 "rolling counter" 139 "rolling counter" 140 "rolling counter" 141 "rolling counter" 142 "rolling counter" 143 "rolling counter" 144 "rolling counter" 145 "rolling counter" 146 "rolling counter" 147 "rolling counter" 148 "rolling counter" 149 "rolling counter" 150 "rolling counter" 151 "rolling counter" 152 "rolling counter" 153 "rolling counter" 154 "rolling counter" 155 "rolling counter" 156 "rolling counter" 157 "rolling counter" 158 "rolling counter" 159 "rolling counter" 160 "rolling counter" 161 "rolling counter" 162 "rolling counter" 163 "rolling counter" 164 "rolling counter" 165 "rolling counter" 166 "rolling counter" 167 "rolling counter" 168 "rolling counter" 169 "rolling counter" 170 "rolling counter" 171 "rolling counter" 172 "rolling counter" 173 "rolling counter" 174 "rolling counter" 175 "rolling counter" 176 "rolling counter" 177 "rolling counter" 178 "rolling counter" 179 "rolling counter" 180 "rolling counter" 181 "rolling counter" 182 "rolling counter" 183 "rolling counter" 184 "rolling counter" 185 "rolling counter" 186 "rolling counter" 187 "rolling counter" 188 "rolling counter" 189 "rolling counter" 190 "rolling counter" 191 "rolling counter" 192 "rolling counter" 193 "rolling counter" 194 "rolling counter" 195 "rolling counter" 196 "rolling counter" 197 "rolling counter" 198 "rolling counter" 199 "rolling counter" 200 "rolling counter" 201 "rolling counter" 202 "rolling counter" 203 "rolling counter" 204 "rolling counter" 205 "rolling counter" 206 "rolling counter" 207 "rolling counter" 208 "rolling counter" 209 "rolling counter" 210 "rolling counter" 211 "rolling counter" 212 "rolling counter" 213 "rolling counter" 214 "rolling counter" 215 "rolling counter" 216 "rolling counter" 217 "rolling counter" 218 "rolling counter" 219 "rolling counter" 220 "rolling counter" 221 "rolling counter" 222 "rolling counter" 223 "rolling counter" 224 "rolling counter" 225 "rolling counter" 226 "rolling counter" 227 "rolling counter" 228 "rolling counter" 229 "rolling counter" 230 "rolling counter" 231 "rolling counter" 232 "rolling counter" 233 "rolling counter" 234 "rolling counter" 235 "rolling counter" 236 "rolling counter" 237 "rolling counter" 238 "rolling counter" 239 "rolling counter" 240 "rolling counter" 241 "rolling counter" 242 "rolling counter" 243 "rolling counter" 244 "rolling counter" 245 "rolling counter" 246 "rolling counter" 247 "rolling counter" 248 "rolling counter" 249 "rolling counter" 250 "rolling counter" 251 "rolling counter" 252 "rolling counter" 253 "rolling counter" 254 "rolling counter" 255 "rolling counter" ;
VAL_ 770 ADS_RpaParkAuthn_302h 0 "不允许手机操作" 1 "允许手机操作" 2 "预留" 3 "预留" ;
VAL_ 770 ADS_VehParkMod_302h 0 "None" 1 "车头泊入" 2 "车尾泊入" 3 "Reserved" 4 "Reserved" 5 "Reserved" 6 "Reserved" 7 "Reserved" ;
VAL_ 770 ADS_RemParkPatSel_302h 0 "NONE" 1 "PARK_IN_REQUEST_CONFIRMED" 2 "PARK_OUT_REQUEST_CONFIRMED" 3 "RESERVED" ;
VAL_ 770 ADS_ParkDirCfm_302h 0 "None" 1 "ParallelLeft_confirm" 2 "ParallelRight_confirm" 3 "PerpendicularForward_confirm" 4 "PerpendicularLeftForward_confirm" 5 "PerpendicularRightForward_confirm" 6 "PerpendicularLeftBack_confirm" 7 "PerpendicularRightBack_confirm" 8 "PerpendicularBack_confirm" 9 "Reserved" 10 "Reserved" 11 "Reserved" 12 "Reserved" 13 "Reserved" 14 "Reserved" 15 "Reserved" ;
VAL_ 770 ADS_ObstclDst_302h 0 "None" 1 "前左障碍物距离Level1" 2 "前左障碍物距离Level2" 3 "前左障碍物距离Level3" 4 "前障碍物距离Level1" 5 "前障碍物距离Level2" 6 "前障碍物距离Level3" 7 "前右障碍物距离Level1" 8 "前右障碍物距离Level2" 9 "前右障碍物距离Level3" 10 "后左障碍物距离Level1" 11 "后左障碍物距离Level2" 12 "后左障碍物距离Level3" 13 "后障碍物距离Level1" 14 "后障碍物距离Level2" 15 "后障碍物距离Level3" 16 "后右障碍物距离Level1" 17 "后右障碍物距离Level2" 18 "后右障碍物距离Level3" 19 "Reserved" 20 "Reserved" 21 "Reserved" 22 "Reserved" 23 "Reserved" 24 "Reserved" 25 "Reserved" 26 "Reserved" 27 "Reserved" 28 "Reserved" 29 "Reserved" 30 "Reserved" 31 "Reserved" ;
VAL_ 770 ADS_AutEve_302h 1 "MOP_HMI_NULL = 0" 2 "MOP_HMI_CRUISE = 1" 3 "MOP_HMI_BYPASS = 2" 4 "MOP_HMI_STOP_MAN = 3" 5 "MOP_HMI_STOP_CAR = 4" 6 "MOP_HMI_FOLLOW = 5" 7 "MOP_HMI_MEET = 6" 8 "MOP_HMI_TIME_OUT = 7" 9 "Reserved" 10 "Reserved" 11 "Reserved" 12 "Reserved" 13 "Reserved" 14 "Reserved" 15 "Reserved" ;
VAL_ 770 ADS_parkInterruptDuration_302h 0 "None（无倒计时或倒计时已结束）" 1 "30s倒计时，精度为1s" 2 "30s倒计时，精度为1s" 3 "30s倒计时，精度为1s" 4 "30s倒计时，精度为1s" 5 "30s倒计时，精度为1s" 6 "30s倒计时，精度为1s" 7 "30s倒计时，精度为1s" 8 "30s倒计时，精度为1s" 9 "30s倒计时，精度为1s" 10 "30s倒计时，精度为1s" 11 "30s倒计时，精度为1s" 12 "30s倒计时，精度为1s" 13 "30s倒计时，精度为1s" 14 "30s倒计时，精度为1s" 15 "30s倒计时，精度为1s" 16 "30s倒计时，精度为1s" 17 "30s倒计时，精度为1s" 18 "30s倒计时，精度为1s" 19 "30s倒计时，精度为1s" 20 "30s倒计时，精度为1s" 21 "30s倒计时，精度为1s" 22 "30s倒计时，精度为1s" 23 "30s倒计时，精度为1s" 24 "30s倒计时，精度为1s" 25 "30s倒计时，精度为1s" 26 "30s倒计时，精度为1s" 27 "30s倒计时，精度为1s" 28 "30s倒计时，精度为1s" 29 "30s倒计时，精度为1s" 30 "30s倒计时，精度为1s" 49 "Reserved" 50 "Reserved" 51 "Reserved" 52 "Reserved" 53 "Reserved" 54 "Reserved" 55 "Reserved" 56 "Reserved" 57 "Reserved" 58 "Reserved" 59 "Reserved" 60 "Reserved" 61 "Reserved" 62 "Reserved" 63 "Reserved" 64 "Reserved" 65 "Reserved" 66 "Reserved" 67 "Reserved" 68 "Reserved" 69 "Reserved" 70 "Reserved" 71 "Reserved" 72 "Reserved" 73 "Reserved" 74 "Reserved" 75 "Reserved" 76 "Reserved" 77 "Reserved" 78 "Reserved" 79 "Reserved" 80 "Reserved" 81 "Reserved" 82 "Reserved" 83 "Reserved" 84 "Reserved" 85 "Reserved" 86 "Reserved" 87 "Reserved" 88 "Reserved" 89 "Reserved" 90 "Reserved" 91 "Reserved" 92 "Reserved" 93 "Reserved" 94 "Reserved" 95 "Reserved" 96 "Reserved" 97 "Reserved" 98 "Reserved" 99 "Reserved" 100 "Reserved" 101 "Reserved" 102 "Reserved" 103 "Reserved" 104 "Reserved" 105 "Reserved" 106 "Reserved" 107 "Reserved" 108 "Reserved" 109 "Reserved" 110 "Reserved" 111 "Reserved" 112 "Reserved" 113 "Reserved" 114 "Reserved" 115 "Reserved" 116 "Reserved" 117 "Reserved" 118 "Reserved" 119 "Reserved" 120 "Reserved" 121 "Reserved" 122 "Reserved" 123 "Reserved" 124 "Reserved" 125 "Reserved" 126 "Reserved" 127 "Reserved" 128 "Reserved" 129 "Reserved" 130 "Reserved" 131 "Reserved" 132 "Reserved" 133 "Reserved" 134 "Reserved" 135 "Reserved" 136 "Reserved" 137 "Reserved" 138 "Reserved" 139 "Reserved" 140 "Reserved" 141 "Reserved" 142 "Reserved" 143 "Reserved" 144 "Reserved" 145 "Reserved" 146 "Reserved" 147 "Reserved" 148 "Reserved" 149 "Reserved" 150 "Reserved" 151 "Reserved" 152 "Reserved" 153 "Reserved" 154 "Reserved" 155 "Reserved" 156 "Reserved" 157 "Reserved" 158 "Reserved" 159 "Reserved" 160 "Reserved" 161 "Reserved" 162 "Reserved" 163 "Reserved" 164 "Reserved" 165 "Reserved" 166 "Reserved" 167 "Reserved" 168 "Reserved" 169 "Reserved" 170 "Reserved" 171 "Reserved" 172 "Reserved" 173 "Reserved" 174 "Reserved" 175 "Reserved" 176 "Reserved" 177 "Reserved" 178 "Reserved" 179 "Reserved" 180 "Reserved" 181 "Reserved" 182 "Reserved" 183 "Reserved" 184 "Reserved" 185 "Reserved" 186 "Reserved" 187 "Reserved" 188 "Reserved" 189 "Reserved" 190 "Reserved" 191 "Reserved" 192 "Reserved" 193 "Reserved" 194 "Reserved" 195 "Reserved" 196 "Reserved" 197 "Reserved" 198 "Reserved" 199 "Reserved" 200 "Reserved" 201 "Reserved" 202 "Reserved" 203 "Reserved" 204 "Reserved" 205 "Reserved" 206 "Reserved" 207 "Reserved" 208 "Reserved" 209 "Reserved" 210 "Reserved" 211 "Reserved" 212 "Reserved" 213 "Reserved" 214 "Reserved" 215 "Reserved" 216 "Reserved" 217 "Reserved" 218 "Reserved" 219 "Reserved" 220 "Reserved" 221 "Reserved" 222 "Reserved" 223 "Reserved" 224 "Reserved" 225 "Reserved" 226 "Reserved" 227 "Reserved" 228 "Reserved" 229 "Reserved" 230 "Reserved" 231 "Reserved" 232 "Reserved" 233 "Reserved" 234 "Reserved" 235 "Reserved" 236 "Reserved" 237 "Reserved" 238 "Reserved" 239 "Reserved" 240 "Reserved" 241 "Reserved" 242 "Reserved" 243 "Reserved" 244 "Reserved" 245 "Reserved" 246 "Reserved" 247 "Reserved" 248 "Reserved" 249 "Reserved" 250 "Reserved" 251 "Reserved" 252 "Reserved" 253 "Reserved" 254 "Reserved" 255 "Reserved" ;
VAL_ 770 APA_ResuAvl_302h 0 "默认" 1 "自检过程中" 2 "自检成功，to active满足" 3 "自检不成功，to active不满足" ;
VAL_ 770 ADS_ParkStMac_302h 0 "STATE_OFF = 0" 1 "STATE_RDA_FORWARD = 1" 2 "STATE_RDA_BACK = 2" 3 "STATE_RDA_ABORT = 3" 4 "STATE_RDA_FINISH = 4" 5 "STATE_CRUISE_FINISH = 5" 6 "STATE_APA_SUSPEND = 6" 7 "STATE_APA_SEARCH = 7" 8 "STATE_APA_STANDBY = 8" 9 "STATE_PARK_OUT = 9" 10 "STATE_PARK_IN = 10" 11 "STATE_APA_FINISH = 11" 12 "STATE_PAUSE = 12" 13 "STATE_OVERRIDE = 13" 14 "预留1" 15 "Reserved" 16 "Reserved" 17 "Reserved" 18 "Reserved" 19 "Reserved" 20 "Reserved" 21 "Reserved" 22 "Reserved" 23 "Reserved" 24 "Reserved" 25 "Reserved" 26 "Reserved" 27 "Reserved" 28 "Reserved" 29 "Reserved" 30 "Reserved" 31 "Reserved" ;
VAL_ 770 ADS_ParkOutDir_ParaLe_302h 0 "不可用" 1 "可用" ;
VAL_ 770 ADS_ParkOutDir_ParaRi_302h 0 "不可用" 1 "可用" ;
VAL_ 770 ADS_ParkOutDir_PerpFwd_302h 0 "不可用" 1 "可用" ;
VAL_ 770 ADS_ParkOutDir_PerpLeFwd_302h 0 "不可用" 1 "可用" ;
VAL_ 770 ADS_ParkOutDir_PerpRiFwd_302h 0 "不可用" 1 "可用" ;
VAL_ 770 ADS_ParkOutDir_PerpLeBack_302h 0 "不可用" 1 "可用" ;
VAL_ 770 ADS_ParkOutDir_PerpRiBack_302h 0 "不可用" 1 "可用" ;
VAL_ 770 ADS_ParkOutDir_PerpBack_302h 0 "不可用" 1 "可用" ;
VAL_ 770 APA_RPAFctUnavlMsg_1_302h 0 "none" 1 "happened 出现该原因" ;
VAL_ 770 APA_RPAFctUnavlMsg_2_302h 0 "none" 1 "happened 出现该原因" ;
VAL_ 770 APA_RPAFctUnavlMsg_3_302h 0 "none" 1 "happened 出现该原因" ;
VAL_ 770 APA_RPAFctUnavlMsg_4_302h 0 "none" 1 "happened 出现该原因" ;
VAL_ 770 APA_RPAFctUnavlMsg_5_302h 0 "none" 1 "happened 出现该原因" ;
VAL_ 770 APA_RPAFctUnavlMsg_6_302h 0 "none" 1 "happened 出现该原因" ;
VAL_ 770 APA_RPAFctUnavlMsg_7_302h 0 "none" 1 "happened 出现该原因" ;
VAL_ 770 APA_RPAFctUnavlMsg_8_302h 0 "none" 1 "happened 出现该原因" ;
VAL_ 770 APA_RPAFctUnavlMsg_9_302h 0 "none" 1 "happened 出现该原因" ;
VAL_ 770 APA_RPAFctUnavlMsg_10_302h 0 "none" 1 "happened 出现该原因" ;
VAL_ 770 APA_RPAFctUnavlMsg_11_302h 0 "none" 1 "happened 出现该原因" ;
VAL_ 770 APA_RPAFctUnavlMsg_12_302h 0 "none" 1 "happened 出现该原因" ;
VAL_ 770 APA_RPAFctUnavlMsg_13_302h 0 "none" 1 "happened 出现该原因" ;
VAL_ 770 APA_RPAFctUnavlMsg_14_302h 0 "none" 1 "happened 出现该原因" ;
VAL_ 770 APA_RPAFctUnavlMsg_15_302h 0 "none" 1 "happened 出现该原因" ;
VAL_ 770 APA_RPAFctUnavlMsg_16_302h 0 "none" 1 "happened 出现该原因" ;
VAL_ 770 APA_RPAFctUnavlMsg_17_302h 0 "none" 1 "happened 出现该原因" ;
VAL_ 770 APA_RPAFctUnavlMsg_18_302h 0 "none" 1 "happened 出现该原因" ;
VAL_ 770 APA_RPAFctUnavlMsg_19_302h 0 "none" 1 "happened 出现该原因" ;
VAL_ 770 APA_RPAFctUnavlMsg_20_302h 0 "none" 1 "happened 出现该原因" ;
VAL_ 770 APA_RPAFctUnavlMsg_21_302h 0 "none" 1 "happened 出现该原因" ;
VAL_ 770 APA_RPAFctUnavlMsg_22_302h 0 "none" 1 "happened 出现该原因" ;
VAL_ 770 APA_RPAFctUnavlMsg_23_302h 0 "none" 1 "happened 出现该原因" ;
VAL_ 770 APA_RPAFctUnavlMsg_24_302h 0 "none" 1 "happened 出现该原因" ;
VAL_ 770 APA_RPAFctUnavlMsg_25_302h 0 "none" 1 "happened 出现该原因" ;
VAL_ 770 APA_RPACnclMsg_1_302h 0 "none" 1 "happened 出现该原因" ;
VAL_ 770 APA_RPACnclMsg_2_302h 0 "none" 1 "happened 出现该原因" ;
VAL_ 770 APA_RPACnclMsg_3 0 "none" 1 "happened 出现该原因" ;
VAL_ 770 APA_RPACnclMsg_4_302h 0 "none" 1 "happened 出现该原因" ;
VAL_ 770 APA_RPACnclMsg_5_302h 0 "none" 1 "happened 出现该原因" ;
VAL_ 770 APA_RPACnclMsg_6_302h 0 "none" 1 "happened 出现该原因" ;
VAL_ 770 APA_RPACnclMsg_7_302h 0 "none" 1 "happened 出现该原因" ;
VAL_ 770 APA_RPACnclMsg_8_302h 0 "none" 1 "happened 出现该原因" ;
VAL_ 770 APA_RPACnclMsg_9_302h 0 "none" 1 "happened 出现该原因" ;
VAL_ 770 APA_RPACnclMsg_10_302h 0 "none" 1 "happened 出现该原因" ;
VAL_ 770 APA_RPACnclMsg_11_302h 0 "none" 1 "happened 出现该原因" ;
VAL_ 770 APA_RPACnclMsg_12_302h 0 "none" 1 "happened 出现该原因" ;
VAL_ 770 APA_RPACnclMsg_13_302h 0 "none" 1 "happened 出现该原因" ;
VAL_ 770 APA_RPACnclMsg_14_302h 0 "none" 1 "happened 出现该原因" ;
VAL_ 770 APA_RPACnclMsg_15_302h 0 "none" 1 "happened 出现该原因" ;
VAL_ 770 APA_RPACnclMsg_16_302h 0 "none" 1 "happened 出现该原因" ;
VAL_ 770 APA_RPACnclMsg_17_302h 0 "none" 1 "happened 出现该原因" ;
VAL_ 770 APA_RPACnclMsg_18_302h 0 "none" 1 "happened 出现该原因" ;
VAL_ 770 APA_RPACnclMsg_19_302h 0 "none" 1 "happened 出现该原因" ;
VAL_ 770 APA_RPACnclMsg_20_302h 0 "none" 1 "happened 出现该原因" ;
VAL_ 770 APA_RPAPauseMsg_1_302h 0 "none" 1 "happened 出现该原因" ;
VAL_ 770 APA_RPAPauseMsg_2_302h 0 "none" 1 "happened 出现该原因" ;
VAL_ 770 APA_RPAPauseMsg_3_302h 0 "none" 1 "happened 出现该原因" ;
VAL_ 770 APA_RPAPauseMsg_4_302h 0 "none" 1 "happened 出现该原因" ;
VAL_ 770 APA_RPAPauseMsg_5_302h 0 "none" 1 "happened 出现该原因" ;
VAL_ 770 APA_RPAPauseMsg_6_302h 0 "none" 1 "happened 出现该原因" ;
VAL_ 770 APA_RPAPauseMsg_7_302h 0 "none" 1 "happened 出现该原因" ;
VAL_ 770 APA_RPAPauseMsg_8_302h 0 "none" 1 "happened 出现该原因" ;
VAL_ 770 APA_RPAPauseMsg_9_302h 0 "none" 1 "happened 出现该原因" ;
VAL_ 770 APA_RPAPauseMsg_10_302h 0 "none" 1 "happened 出现该原因" ;
VAL_ 770 ADS_MnvrOrintChng1_302h 0 "None" 1 "Parallel" 2 "Cross" 3 "斜列" ;
VAL_ 770 ADS_MnvrOrintChng2_302h 0 "None" 1 "Parallel" 2 "Cross" 3 "斜列" ;
VAL_ 770 ADS_TarParkSt_Posn1_302h 0 "None" 1 "Invalid" 2 "Valid" 3 "Selectable" 4 "Selected" 5 "Reserved" 6 "Reserved" 7 "Reserved" ;
VAL_ 770 ADS_ParkChkSrc_Posn1_302h 0 "None" 1 "camera" 2 "lidar" 3 "mixed" 4 "Reserved" 5 "Reserved" 6 "Reserved" 7 "Reserved" ;
VAL_ 770 ADS_VdcActvSts_302h 0 "NotActive" 1 "Active" ;
VAL_ 770 ADS_TcsActvSts_302h 0 "NotActive" 1 "Active" ;
VAL_ 770 ADS_TarParkSt_Posn2_302h 0 "None" 1 "Invalid" 2 "Valid" 3 "Selectable" 4 "Selected" 5 "Reserved" 6 "Reserved" 7 "Reserved" ;
VAL_ 770 ADS_ParkChkSrc_Posn2_302h 0 "None" 1 "camera" 2 "lidar" 3 "mixed" 4 "Reserved" 5 "Reserved" 6 "Reserved" 7 "Reserved" ;
VAL_ 514 ADS_AdsFault_202h 0 "no request" 1 "无故障" 2 "有故障" 3 "reserved" 7 "Invalid" ;
VAL_ 514 ADS_NicaReminderLEDVisual_202h 0 "no request" 1 "turn on" 2 "turn off" 3 "reserved" 4 "reserved" 5 "reserved" 6 "reserved" 7 "Invalid" ;
VAL_ 514 ADS_NicaReminderAcoustic_202h 0 "no request" 1 "acoustic" 2 "no acoustic" 3 "torL1_acoustic" 4 "aeb_acoustic" 5 "reserved" 6 "reserved" 7 "Invalid" ;
VAL_ 514 ADS_TakeoverID_202h 0 "no request作为默认值" ;
VAL_ 514 ADS_TakeoverLevel_202h 0 "no request" 1 "Level 1" 2 "Level 2" 3 "Level 3" 4 "Level 4" 7 "Invalid" ;
VAL_ 514 ADS_TakeoverType_202h 0 "no request" 1 "大红手" 2 "松开加速踏板" 3 "制动踏板" 4 "MRM大红手" 5 "大黄手" 15 "Invalid" ;
VAL_ 514 ADS_TORIDCorrespErrorID_202h 0 "no request作为默认值" ;
VAL_ 1041 ADS_RadarWarning0AcLvl_411h 0 "no request" 1 "Level 1" 2 "Level 2" 3 "Level 3" 4 "Level 4" 5 "Level 5" 7 "Invalid" ;
VAL_ 1041 ADS_RadarWarning1AcLvl_411h 0 "no request" 1 "Level 1" 2 "Level 2" 3 "Level 3" 4 "Level 4" 5 "Level 5" 7 "Invalid" ;
VAL_ 1041 ADS_RadarWarning2AcLvl_411h 0 "no request" 1 "Level 1" 2 "Level 2" 3 "Level 3" 4 "Level 4" 5 "Level 5" 7 "Invalid" ;
VAL_ 1041 ADS_RadarWarning3AcLvl_411h 0 "no request" 1 "Level 1" 2 "Level 2" 3 "Level 3" 4 "Level 4" 5 "Level 5" 7 "Invalid" ;
VAL_ 1041 ADS_RadarWarning4AcLvl_411h 0 "no request" 1 "Level 1" 2 "Level 2" 3 "Level 3" 4 "Level 4" 5 "Level 5" 7 "Invalid" ;
VAL_ 1041 ADS_RadarWarning5AcLvl_411h 0 "no request" 1 "Level 1" 2 "Level 2" 3 "Level 3" 4 "Level 4" 5 "Level 5" 7 "Invalid" ;
VAL_ 1041 ADS_RadarWarning6AcLvl_411h 0 "no request" 1 "Level 1" 2 "Level 2" 3 "Level 3" 4 "Level 4" 5 "Level 5" 7 "Invalid" ;
VAL_ 1041 ADS_RadarWarning7AcLvl_411h 0 "no request" 1 "Level 1" 2 "Level 2" 3 "Level 3" 4 "Level 4" 5 "Level 5" 7 "Invalid" ;
VAL_ 1041 ADS_RadarWarning8AcLvl_411h 0 "no request" 1 "Level 1" 2 "Level 2" 3 "Level 3" 4 "Level 4" 5 "Level 5" 7 "Invalid" ;
VAL_ 1041 ADS_RadarWarning9AcLvl_411h 0 "no request" 1 "Level 1" 2 "Level 2" 3 "Level 3" 4 "Level 4" 5 "Level 5" 7 "Invalid" ;
VAL_ 1041 ADS_RadarWarning10AcLvl_411h 0 "no request" 1 "Level 1" 2 "Level 2" 3 "Level 3" 4 "Level 4" 5 "Level 5" 7 "Invalid" ;
VAL_ 1041 ADS_RadarWarning11AcLvl_411h 0 "no request" 1 "Level 1" 2 "Level 2" 3 "Level 3" 4 "Level 4" 5 "Level 5" 7 "Invalid" ;
VAL_ 1041 ADS_RadarWarning12AcLvl_411h 0 "no request" 1 "Level 1" 2 "Level 2" 3 "Level 3" 4 "Level 4" 5 "Level 5" 7 "Invalid" ;
VAL_ 1041 ADS_RadarWarning13AcLvl_411h 0 "no request" 1 "Level 1" 2 "Level 2" 3 "Level 3" 4 "Level 4" 5 "Level 5" 7 "Invalid" ;
VAL_ 1041 ADS_RadarWarning14AcLvl_411h 0 "no request" 1 "Level 1" 2 "Level 2" 3 "Level 3" 4 "Level 4" 5 "Level 5" 7 "Invalid" ;
VAL_ 1041 ADS_RadarWarning15AcLvl_411h 0 "no request" 1 "Level 1" 2 "Level 2" 3 "Level 3" 4 "Level 4" 5 "Level 5" 7 "Invalid" ;
VAL_ 1041 ADC_FuncReq_SentryModWarn_411h 0 "OFF;" 1 "哨兵模式唤醒" ;
VAL_ 1041 ADC_FuncReq_SentryModDetec_411h 0 "OFF;" 1 "哨兵模式维持" ;
VAL_ 1041 ADC_MdcSentryAlarmMod_411h 0 "无告警" 1 "警报" ;
VAL_ 769 ADS_AccFunctionStatus_301h 0 "No request" 1 "ACC_OFF" 2 "ACC_STANDBY" 3 "ACC_OVERRIDE" 4 "ACC_ACTIVE" 5 "ACC_STANDSTILL" 15 "Invalid" ;
VAL_ 769 ADS_LccNcaFunctionStatus_301h 0 "no request" 1 "OFF" 2 "LCC_STANDBY" 3 "LCC_LATERAL_OVERRIDE" 4 "LCC_LONGITUDINAL_OVERRIDE" 5 "LCC_LAT_LONG_OVERRIDE" 6 "LCC_ACTIVE" 7 "NCA_STANDBY" 8 "NCA_LATERAL_OVERRIDE" 9 "NCA_LONGITUDINAL_OVERRIDE" 10 "NCA_LAT_LONG_OVERRIDE" 11 "NCA_ACTIVE" 63 "Invalid" ;
VAL_ 769 ADS_AdsFucntionNotActive_301h 0 "no request" 1 "OFF" 2 "ACC" 3 "LCC" 4 "NCA" 5 "AVP" 15 "Invalid" ;
VAL_ 769 ADS_AvpFunctionStatus_301h 0 "no request" 1 "AVP_STATE_OFF" 2 "AVP_STATE_STANDBY" 3 "AVP_STATE_OVERRIDE" 4 "AVP_STATE_ACTIVE" 31 "invalid" ;
VAL_ 769 ADS_SpeedAutoFollow_301h 0 "no request" 1 "OFF" 2 "Active" 7 "Invalid" ;
VAL_ 769 ADS_OneTouchSpeedAdjustment_301h 0 "no request" 1 "Speed+" 2 "Speed-" 7 "Invalid" ;
VAL_ 769 ADS_CalibState_301h 0 "no request" 1 "off" 2 "on" 3 "reserved" 4 "reserved" 5 "reserved" 6 "reserved" 7 "Invalid" ;
VAL_ 769 ADS_HODReminder_301h 0 "no request" 1 "OFF" 2 "warning_level 1" 3 "warning_level 2" 4 "warning_level 3" 5 "warning_level 4" 6 "reserved" 7 "Invalid" ;
VAL_ 769 ADS_DMSReminder_301h 0 "no request" 1 "OFF" 2 "Distraction_warning_level 1" 3 "Fatigue_warning_level 1" 4 "Distraction_warning_level 2" 5 "Fatigue_warning_level 2" 6 "Distraction_warning_level 3" 7 "Fatigue_warning_level 3" 8 "Distraction_tellphone_call" 15 "Invalid" ;
VAL_ 769 ADS_FcwWaning_301h 0 "no request" 1 "Off" 2 "Standby" 3 "Active_level1" 4 "Active_level2" 5 "Nolicense" 7 "invalid" ;
VAL_ 769 ADS_FcwFault_301h 0 "no request" 1 "no fault" 2 "fault" 3 "invalid" ;
VAL_ 769 ADS_AebWaning_301h 0 "no request" 1 "Off" 2 "Active" 3 "IBA" 4 "Hold" 5 "Inactive (standby)" 6 "Nolicense" 7 "invalid" ;
VAL_ 769 ADS_AebFault_301h 0 "no request" 1 "no fault" 2 "fault" 3 "invalid" ;
VAL_ 769 ADS_AebObjType_301h 0 "no request" 1 "NONE" 2 "CARS" 3 "CYCLIST" 4 "Pedestrian" 5 "Others（通用障碍物）" 7 "invalid" ;
VAL_ 769 ADS_RaebWarning_301h 0 "no request" 1 "Off" 2 "Active" 3 "Hold" 4 "Inactive (standby)" 5 "Nolicense" 6 "Reserved" 7 "invalid" ;
VAL_ 769 ADS_RaebFault_301h 0 "no request" 1 "no fault" 2 "fault" 3 "invalid" ;
VAL_ 769 ADS_RcwWarning_301h 0 "no request" 1 "Off" 2 "Standby" 3 "Active_level1" 4 "Active_level2" 5 "Nolicense" 7 "invalid" ;
VAL_ 769 ADS_RcwFault_301h 0 "no request" 1 "no fault" 2 "fault" 3 "invalid" ;
VAL_ 769 ADS_FctaLeftWarning_301h 0 "no request" 1 "Off" 2 "Standby" 3 "Active_level1_Left" 4 "Active_level2_Left" 5 "Nolicense" 7 "invalid" ;
VAL_ 769 ADS_FctaRightWarning_301h 0 "no request" 1 "Off" 2 "Standby" 3 "Active_level1_Right" 4 "Active_level2_Right" 5 "Nolicense" 7 "invalid" ;
VAL_ 769 ADS_FctbLeftWarning_301h 0 "no request" 1 "Off" 2 "Active_Left" 3 "IBA" 4 "Hold" 5 "inactive (standby)" 6 "Nolicense" 7 "invalid" ;
VAL_ 769 ADS_FctbRightWarning_301h 0 "no request" 1 "Off" 2 "Active_Right" 3 "IBA" 4 "Hold" 5 "inactive (standby)" 6 "Nolicense" 7 "invalid" ;
VAL_ 769 ADS_RctaLeftWarning_301h 0 "no request" 1 "Off" 2 "Standby" 3 "Warning_Left" 4 "Warning_level2_Left" 5 "Nolicense" 6 "Reserved" 7 "invalid" ;
VAL_ 769 ADS_RctaRightWarning_301h 0 "no request" 1 "Off" 2 "Standby" 3 "Warning_Right" 4 "Warning_level2_Right" 5 "Nolicense" 6 "Reserved" 7 "invalid" ;
VAL_ 769 ADS_RctaFault_301h 0 "no request" 1 "no fault" 2 "fault" 3 "invalid" ;
VAL_ 769 ADS_RctbLeftWarning_301h 0 "no request" 1 "Off" 2 "Active_Left" 3 "Hold" 4 "Inactive (Standby)" 5 "Nolicense" 7 "invalid" ;
VAL_ 769 ADS_RctbRightWarning_301h 0 "no request" 1 "Off" 2 "Active_Right" 3 "Hold" 4 "Inactive (Standby)" 5 "Nolicense" 7 "invalid" ;
VAL_ 769 ADS_LdwWarning_301h 0 "no request" 1 "Off" 2 "Standby" 3 "Ready" 4 "Active_Left" 5 "Active_Right" 6 "Switchoff" 7 "invalid" ;
VAL_ 769 ADS_LdwFault_301h 0 "no request" 1 "no fault" 2 "fault" 3 "invalid" ;
VAL_ 769 ADS_LKAWarning_301h 0 "no request" 1 "Off" 2 "Standby" 3 "Ready" 4 "Active_Left" 5 "Active_Right" 6 "Switchoff" 7 "invalid" ;
VAL_ 769 ADS_LkaFault_301h 0 "no request" 1 "no fault" 2 "fault" 3 "invalid" ;
VAL_ 769 ADS_LeftMirrWarningCmd_301h 0 "no request" 1 "no warning" 2 "level 1" 3 "level 2" 4 "reserved" 7 "Invalid" ;
VAL_ 769 ADS_RightMirrWarningCmd_301h 0 "no request" 1 "no warning" 2 "level 1" 3 "level 2" 4 "reserved" 7 "Invalid" ;
VAL_ 769 ADS_BsdFault_301h 0 "no request" 1 "no fault" 2 "fault" 3 "invalid" ;
VAL_ 769 ADS_LeFrntDoorWarningCmd_301h 0 "no request" 1 "no warning" 2 "level 1" 3 "level 2" 4 "reserved" 7 "Invalid" ;
VAL_ 769 ADS_LeReDoorWarningCmd_301h 0 "no request" 1 "no warning" 2 "level 1" 3 "level 2" 4 "reserved" 7 "Invalid" ;
VAL_ 769 ADS_RiFrntDoorWarningCmd_301h 0 "no request" 1 "no warning" 2 "level 1" 3 "level 2" 4 "reserved" 7 "Invalid" ;
VAL_ 769 ADS_RiReDoorWarningCmd_301h 0 "no request" 1 "no warning" 2 "level 1" 3 "level 2" 4 "reserved" 7 "Invalid" ;
VAL_ 769 ADS_DowFault_301h 0 "no request" 1 "no fault" 2 "fault" 3 "invalid" ;
VAL_ 769 ADS_SpeedLimitWarning_301h 0 "no request" 1 "no_warning" 2 "warning_Relative" 3 "warning_Absolute" 4 "reserved_1" 5 "reserved_2" 6 "reserved_3" 7 "Invalid" ;
VAL_ 769 ADS_TsrFault_301h 0 "no request" 1 "no fault" 2 "fault" 3 "invalid" ;
VAL_ 769 ADS_TlaFault_301h 0 "no request" 1 "no fault" 2 "fault" 3 "invalid" ;
VAL_ 769 ADS_ElkaFault_301h 0 "no request" 1 "no fault" 2 "fault" 3 "invalid" ;
VAL_ 769 ADS_TlaWarning_301h 0 "no request" 1 "No Warning" 2 "Red Light Warning" 3 "Start Warning" 4 "reserved_1" 5 "reserved_2" 6 "reserved_3" 7 "Invalid" ;
VAL_ 769 ADS_ElkaWarning_301h 0 "no request" 1 "Off" 2 "Standby" 3 "Ready" 4 "Active_Left" 5 "Active_Right" 6 "Switchoff" 7 "invalid" ;
VAL_ 1042 ADS_BrkBeamReq_412h 0 "无请求" 1 "ON" 2 "Resvered" 3 "Resvered" ;
VAL_ 1042 ADS_AutoLightSwCtrl_412h 0 "无请求" 1 "POSITION_LIGHT" 2 "LOW_BEAM" 3 "AUTO_MODE" ;
VAL_ 1042 ADS_LeFrntDowWarning_412h 0 "无请求" 1 "常亮" 2 "闪烁" 3 "reserved" ;
VAL_ 1042 ADS_RiFrntDowWarning_412h 0 "无请求" 1 "常亮" 2 "闪烁" 3 "reserved" ;
VAL_ 1042 ADS_LeReDowWarning_412h 0 "无请求" 1 "常亮" 2 "闪烁" 3 "reserved" ;
VAL_ 1042 ADS_RiReDowWarning_412h 0 "无请求" 1 "常亮" 2 "闪烁" 3 "reserved" ;
VAL_ 1042 ADS_LeftMirrWarningCmd_412h 0 "无请求" 1 "Level（常亮）" 2 "Level (闪烁）" 3 "resversed" ;
VAL_ 1042 ADS_RightMirrWarningCmd_412h 0 "无请求" 1 "Level（常亮）" 2 "Level (闪烁）" 3 "resversed" ;
VAL_ 1042 ADS_ReMirrReq_412h 0 "Not Request" 1 "展开" 2 "折叠" 3 "Not used" ;
VAL_ 1042 ADS_DoorLockReq_412h 0 "Not Request 无请求" 1 "UnLock 解锁请求" 2 "Lock 上锁请求" 3 "reserved" ;
VAL_ 1042 ADS_SBeltControl_412h 0 "No Request" 1 "Shake" 2 "Tied level 1" 3 "Tied level 2 （预留）" 4 "reserved" 5 "reserved" 6 "reserved" 7 "reserved" ;
VAL_ 1042 ADS_WshrReq_412h 0 "无请求" 1 "有请求" ;
VAL_ 1042 ADS_SeatShakeControl_412h 0 "No Request" 1 "Shake" 2 "reserved" 3 "reserved" ;
VAL_ 1042 ADS_FrtWindshildHeatReq_412h 0 "无请求" 1 "有请求" 2 "reserved" 3 "reserved" ;
VAL_ 1042 ADS_HornReq_412h 0 "无请求" 1 "哨兵模式喇叭请求" 2 "巡航功能喇叭请求" 3 "resevered" ;
VAL_ 1042 ADS_LeFmtWinCtrl_412h 0 "无请求" 1 "关闭" 2 "打开" 3 "resevered" ;
VAL_ 1042 ADS_RiFmtWinCtrl_412h 0 "无请求" 1 "关闭" 2 "打开" 3 "resevered" ;
VAL_ 1042 ADS_LeReWinCtrl_412h 0 "无请求" 1 "关闭" 2 "打开" 3 "resevered" ;
VAL_ 1042 ADS_RiReWinCtrl_412h 0 "无请求" 1 "关闭" 2 "打开" 3 "resevered" ;
VAL_ 1042 ADS_TopWinCtrl_412h 0 "无请求" 1 "关闭" 2 "打开" 3 "resevered" ;
VAL_ 1042 ADS_FrontWiperReq_412h 0 "无请求" 1 "有请求" ;
VAL_ 1042 ADS_ChargingPortCmd_412h 0 "no request" 1 "OFF" 2 "ON" 3 "Reversed" ;
VAL_ 1042 ADAS_FctSts_412h 0 "Off" 1 "On" ;
VAL_ 1042 ADS_MdcCrtSts_412h 0 "DeepSleep深度睡眠状态" 1 "LightSleep浅睡眠状态" 2 "Active激活状态" 3 "PartialActive半激活状态" 4 "Reserved" 5 "Reserved" 6 "Reserved" 7 "Invalid" ;
VAL_ 1042 ADS_HVCtrlReq_412h 0 "No Request" 1 "Request" ;
VAL_ 1042 ADS_ThmPostRun_412h 0 "No Request" 1 "Request" ;
VAL_ 1042 ADS_FlowReq_412h 0 "0.0L/min" 1 "0.25L/min" 2 "0.5L/min" 3 "0.75L/min" 4 "1.0L/min" 5 "1.25L/min" 6 "1.5L/min" 7 "1.75L/min" 8 "2.00L/min" 9 "2.25L/min" 10 "2.5L/min" 11 "2.75L/min" 12 "3.0L/min" 13 "3.25L/min" ;
VAL_ 1042 ADS_PwrOnOffReq_412h 0 "no request" 1 "Power on 上电（从OFF至整车Ready状态）" 2 "Power off 下电（KL15 OFF)" 3 "上Ready（等同于过动力防盗）" 4 "下Ready（等同于退动力防盗，需维持高压）" 5 "reserved" 6 "reserved" 7 "reserved" ;
VAL_ 1042 ADS_hmaOnOffSts_412h 0 "Initial" 1 "OFF" 2 "ON" 3 "INVALID" ;
VAL_ 1042 ADS_HMAStatus_412h 0 "Off" 1 "Standby" 2 "Active" 3 "Failure" ;
VAL_ 1042 ADS_HiBeamReq_412h 0 "No Request" 1 "Request" ;
VAL_ 1046 LBMS_LoWSocFlt 0 "No Remind" 1 "Low Power Remind" 2 "Level 2 fault" 3 "Level 3 fault" 4 "Reserved" 5 "Reserved" 6 "Reserved" 7 "Reserved" 8 "Reserved" 9 "Reserved" 10 "Reserved" 11 "Reserved" 12 "Reserved" 13 "Reserved" 14 "Reserved" 15 "Reserved" ;
VAL_ 1046 LBMS_ThermRunawayFlt 0 "No Active" 1 "Active" ;
VAL_ 1046 LBMS_SysFlt 0 "No Active" 1 "Active" ;
VAL_ 1046 LBMS_LowPowerRemind 0 "No Remind" 1 "Low Power Remind" 2 "Level 2 fault" 3 "Level 3 fault" 4 "Reserved" 5 "Reserved" 6 "Reserved" 7 "Reserved" 8 "Reserved" 9 "Reserved" 10 "Reserved" 11 "Reserved" 12 "Reserved" 13 "Reserved" 14 "Reserved" 15 "Reserved" ;
VAL_ 1046 LBMS_EndLifeFlt 0 "No Active" 1 "Active" ;
SIG_GROUP_ 290 EPS_1_0x122_E2E_P01_1 1 : EPS_1_CRC EPS_1_RollgCntr EPSFailSts EPSSteeringAngleCalibrationSts EPS_EOTLearning_Sts;
SIG_GROUP_ 1095 RLCR_1_0x447_E2E_P01_1 1 : RLCR_1_CRC1 RLCR_1_RollgCntr1 RLCR_1_Resd1 RLCR_1_SysSt RLCR_1_BlkSts RLCR_1_BSDWarn RLCR_1_DOWWarn RLCR_1_DowLock RLCR_1_ELK_Collision_flag RLCR_1_ELK_CollisionFlagValid;
SIG_GROUP_ 1267 RRCR_1_0x4F3_E2E_P01_1 1 : RRCR_1_CRC1 RRCR_1_RollgCntr1 RRCR_1_Resd1 RRCR_1_SysSt RRCR_1_BlkSts RRCR_1_BSDWarn RRCR_1_DOWWarn RRCR_1_DowLock RRCR_1_ELK_Collision_flag RRCR_1_ELK_CollisionFlagValid;
SIG_GROUP_ 524 ADS_6_0x20C_E2E_P01_1 1 : New_Signal_20C New_Signal_20C_1 ADS_6_CRC1 ADS_6_RollgCntr1 ADS_6_Resd1 ADS_6_AVM_FuncSts ADS_6_AVM_ButtonClick ADS_6_Customize_buttonsFB ADS_6_PAS_AudioTone;
SIG_GROUP_ 514 New_Signal_Group_202 1 : ADS_CRC1_202h ADS_RollgCntr1_202h ADS_Resd1_202h ADS_TORIDCorrespErrorID_202h ADS_TakeoverType_202h ADS_TakeoverLevel_202h ADS_TakeoverID_202h ADS_NicaReminderAcoustic_202h ADS_NicaReminderLEDVisual_202h ADS_AdsFault_202h;
SIG_GROUP_ 1042 New_Signal_Group_412 1 : New_Signal_412_1 ADS_CRC1_412h ADS_RollgCntr1_412h ADS_Resd1_412h ADS_MdcCrtSts_412h ADAS_FctSts_412h ADS_ChargingPortCmd_412h ADS_FrontWiperReq_412h ADS_TopWinCtrl_412h ADS_RiReWinCtrl_412h ADS_LeReWinCtrl_412h ADS_RiFmtWinCtrl_412h ADS_LeFmtWinCtrl_412h ADS_HornReq_412h ADS_FrtWindshildHeatReq_412h ADS_SeatShakeControl_412h ADS_WshrReq_412h ADS_SBeltControl_412h ADS_DoorLockReq_412h ADS_ReMirrReq_412h ADS_RightMirrWarningCmd_412h ADS_LeftMirrWarningCmd_412h ADS_RiReDowWarning_412h ADS_LeReDowWarning_412h ADS_RiFrntDowWarning_412h ADS_LeFrntDowWarning_412h ADS_AutoLightSwCtrl_412h ADS_BrkBeamReq_412h;
